VERSION ""

NS_ :

BS_:

BU_: ACM APIM APIM_CDC APIM_CIM APIM_CISM ARM DSP ESPM FCIMB GENERIC GWM HUD_ADV IPC MRCMB_RDAPM_HS3 RACM_RCIM TRM_ITRM TSTR WCM WCMB WCMC

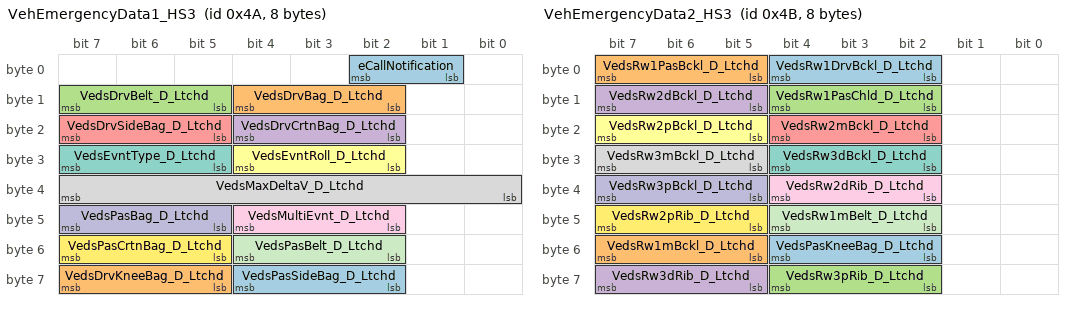
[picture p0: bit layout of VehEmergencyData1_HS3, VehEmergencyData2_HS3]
BO_ 74 VehEmergencyData1_HS3: 8 GWM
 SG_ eCallNotification : 2|2@0+ (1,0) [0|3] "SED"  APIM,APIM_CDC,APIM_CIM,APIM_CISM
 SG_ VedsDrvBag_D_Ltchd : 12|3@0+ (1,0) [0|7] "SED"  ACM,APIM,APIM_CDC,APIM_CIM,APIM_CISM
 SG_ VedsDrvBelt_D_Ltchd : 15|3@0+ (1,0) [0|7] "SED"  APIM,APIM_CDC,APIM_CIM,APIM_CISM
 SG_ VedsDrvCrtnBag_D_Ltchd : 20|3@0+ (1,0) [0|7] "SED"  APIM,APIM_CDC,APIM_CIM,APIM_CISM
 SG_ VedsDrvSideBag_D_Ltchd : 23|3@0+ (1,0) [0|7] "SED"  APIM,APIM_CDC,APIM_CIM,APIM_CISM
 SG_ VedsEvntRoll_D_Ltchd : 28|3@0+ (1,0) [0|7] "SED"  APIM,APIM_CDC,APIM_CIM,APIM_CISM
 SG_ VedsEvntType_D_Ltchd : 31|3@0+ (1,0) [0|7] "SED"  APIM,APIM_CDC,APIM_CIM,APIM_CISM
 SG_ VedsMaxDeltaV_D_Ltchd : 39|8@0+ (1,0) [0|255] "kph"  APIM,APIM_CDC,APIM_CIM,APIM_CISM
 SG_ VedsMultiEvnt_D_Ltchd : 44|3@0+ (1,0) [0|7] "SED"  APIM,APIM_CDC,APIM_CIM,APIM_CISM
 SG_ VedsPasBag_D_Ltchd : 47|3@0+ (1,0) [0|7] "SED"  APIM,APIM_CDC,APIM_CIM,APIM_CISM
 SG_ VedsPasBelt_D_Ltchd : 52|3@0+ (1,0) [0|7] "SED"  APIM,APIM_CDC,APIM_CIM,APIM_CISM
 SG_ VedsPasCrtnBag_D_Ltchd : 55|3@0+ (1,0) [0|7] "SED"  APIM,APIM_CDC,APIM_CIM,APIM_CISM
 SG_ VedsPasSideBag_D_Ltchd : 60|3@0+ (1,0) [0|7] "SED"  APIM,APIM_CDC,APIM_CIM,APIM_CISM
 SG_ VedsDrvKneeBag_D_Ltchd : 63|3@0+ (1,0) [0|7] "SED"  APIM,APIM_CDC,APIM_CIM,APIM_CISM

BO_ 75 VehEmergencyData2_HS3: 8 GWM
 SG_ VedsRw1DrvBckl_D_Ltchd : 4|3@0+ (1,0) [0|7] "SED"  APIM,APIM_CDC,APIM_CIM,APIM_CISM
 SG_ VedsRw1PasBckl_D_Ltchd : 7|3@0+ (1,0) [0|7] "SED"  APIM,APIM_CDC,APIM_CIM,APIM_CISM
 SG_ VedsRw1PasChld_D_Ltchd : 12|3@0+ (1,0) [0|7] "SED"  APIM,APIM_CDC,APIM_CIM,APIM_CISM
 SG_ VedsRw2dBckl_D_Ltchd : 15|3@0+ (1,0) [0|7] "SED"  APIM,APIM_CDC,APIM_CIM,APIM_CISM
 SG_ VedsRw2mBckl_D_Ltchd : 20|3@0+ (1,0) [0|7] "SED"  APIM,APIM_CDC,APIM_CIM,APIM_CISM
 SG_ VedsRw2pBckl_D_Ltchd : 23|3@0+ (1,0) [0|7] "SED"  APIM,APIM_CDC,APIM_CIM,APIM_CISM
 SG_ VedsRw3dBckl_D_Ltchd : 28|3@0+ (1,0) [0|7] "SED"  APIM,APIM_CDC,APIM_CIM,APIM_CISM
 SG_ VedsRw3mBckl_D_Ltchd : 31|3@0+ (1,0) [0|7] "SED"  APIM,APIM_CDC,APIM_CIM,APIM_CISM
 SG_ VedsRw2dRib_D_Ltchd : 36|3@0+ (1,0) [0|7] "SED"  APIM,APIM_CDC,APIM_CIM,APIM_CISM
 SG_ VedsRw3pBckl_D_Ltchd : 39|3@0+ (1,0) [0|7] "SED"  APIM,APIM_CDC,APIM_CIM,APIM_CISM
 SG_ VedsRw1mBelt_D_Ltchd : 44|3@0+ (1,0) [0|7] "SED"  APIM,APIM_CDC,APIM_CIM,APIM_CISM
 SG_ VedsRw2pRib_D_Ltchd : 47|3@0+ (1,0) [0|7] "SED"  APIM,APIM_CDC,APIM_CIM,APIM_CISM
 SG_ VedsPasKneeBag_D_Ltchd : 52|3@0+ (1,0) [0|7] "SED"  ACM,APIM,APIM_CDC,APIM_CIM,APIM_CISM
 SG_ VedsRw1mBckl_D_Ltchd : 55|3@0+ (1,0) [0|7] "SED"  APIM,APIM_CDC,APIM_CIM,APIM_CISM
 SG_ VedsRw3pRib_D_Ltchd : 60|3@0+ (1,0) [0|7] "SED"  APIM,APIM_CDC,APIM_CIM,APIM_CISM
 SG_ VedsRw3dRib_D_Ltchd : 63|3@0+ (1,0) [0|7] "SED"  APIM,APIM_CDC,APIM_CIM,APIM_CISM

BO_ 76 RCMStatusMessage2_HS3: 8 GWM
 SG_ RstrnImpactEvntStatus : 3|3@0+ (1,0) [0|7] "SED"  APIM,APIM_CDC,APIM_CIM,APIM_CISM,HUD_ADV
 SG_ PsngrFrntDetct_D_Actl : 5|2@0+ (1,0) [0|3] "SED"  APIM,APIM_CDC,APIM_CIM,APIM_CISM,IPC
 SG_ RILReq : 7|2@0+ (1,0) [0|3] "SED"  APIM_CDC,APIM_CIM,APIM_CISM,IPC
 SG_ SecondRowBuckleMid : 9|2@0+ (1,0) [0|3] "SED"  APIM,APIM_CDC,APIM_CIM,APIM_CISM,IPC
 SG_ SecondRowBuckleDriver : 11|2@0+ (1,0) [0|3] "SED"  APIM,APIM_CDC,APIM_CIM,APIM_CISM,IPC
 SG_ FirstRowBucklePsngr : 13|2@0+ (1,0) [0|3] "SED"  APIM,APIM_CDC,APIM_CIM,APIM_CISM,IPC
 SG_ FirstRowBuckleDriver : 15|2@0+ (1,0) [0|3] "SED"  APIM,APIM_CDC,APIM_CIM,APIM_CISM,IPC
 SG_ ThirdRowBucklePsngr : 17|2@0+ (1,0) [0|3] "SED"  APIM,APIM_CDC,APIM_CIM,APIM_CISM,IPC
 SG_ ThirdRowBuckleMid : 19|2@0+ (1,0) [0|3] "SED"  APIM,APIM_CDC,APIM_CIM,APIM_CISM,IPC
 SG_ ThirdRowBuckleDriver : 21|2@0+ (1,0) [0|3] "SED"  APIM,APIM_CDC,APIM_CIM,APIM_CISM,IPC
 SG_ SecondRowBucklePsngr : 23|2@0+ (1,0) [0|3] "SED"  APIM,APIM_CDC,APIM_CIM,APIM_CISM,IPC
 SG_ PsngrFmidDetct_D_Actl : 26|2@0+ (1,0) [0|3] "SED"  APIM,APIM_CDC,APIM_CIM,APIM_CISM,IPC
 SG_ FirstRowBuckleMid : 28|2@0+ (1,0) [0|3] "SED"  APIM,APIM_CDC,APIM_CIM,APIM_CISM,IPC
 SG_ EDRTriggerEvntSync : 29|1@0+ (1,0) [0|1] "SED"  APIM,APIM_CDC,APIM_CIM,APIM_CISM,IPC
 SG_ PassRstrnInd_Req : 31|2@0+ (1,0) [0|3] "SED"  APIM_CDC,APIM_CIM,APIM_CISM,FCIMB,GENERIC
 SG_ RCMStatusMsg2_No_Cnt : 35|4@0+ (1,0) [0|15] "unitless"  APIM_CDC,GENERIC
 SG_ RstrnPsngrOn_D_Stat : 39|4@0+ (1,0) [0|15] "SED"  APIM_CDC,APIM_CIM,APIM_CISM,IPC
 SG_ FirstRowBuckle_No_Cs : 47|8@0+ (1,0) [0|255] "unitless"  APIM_CDC,GENERIC
 SG_ RCMStatusMsg2_No_Cs : 55|8@0+ (1,0) [0|255] "unitless"  APIM_CDC
 SG_ PassRstrnIndB_Req : 61|2@0+ (1,0) [0|3] "SED"  APIM,APIM_CDC
 SG_ AirbagDrv_D_Actv : 63|2@0+ (1,0) [0|3] "SED"  APIM_CDC

BO_ 90 Gear_Shift_by_Wire_HS3: 8 GWM
 SG_ TrnGearButtn_B_ActlN0 : 0|1@0+ (1,0) [0|1] "SED" Vector__XXX
 SG_ TrnGearButtn_B_ActlM2 : 1|1@0+ (1,0) [0|1] "SED" Vector__XXX
 SG_ TrnGearButtn_B_ActlM1 : 2|1@0+ (1,0) [0|1] "SED" Vector__XXX
 SG_ TrnGearButtn_B_ActlM0 : 3|1@0+ (1,0) [0|1] "SED" Vector__XXX
 SG_ TrnGearButtn_B_ActlD2 : 4|1@0+ (1,0) [0|1] "SED" Vector__XXX
 SG_ TrnGearButtn_B_ActlD1 : 5|1@0+ (1,0) [0|1] "SED" Vector__XXX
 SG_ TrnGearButtn_B_ActlD0 : 6|1@0+ (1,0) [0|1] "SED" Vector__XXX
 SG_ BrkSwtchPos_B_ActlGsm : 7|1@0+ (1,0) [0|1] "SED" Vector__XXX
 SG_ TrnGearButtn_B_ActlR2 : 8|1@0+ (1,0) [0|1] "SED" Vector__XXX
 SG_ TrnGearButtn_B_ActlR1 : 9|1@0+ (1,0) [0|1] "SED" Vector__XXX
 SG_ TrnGearButtn_B_ActlR0 : 10|1@0+ (1,0) [0|1] "SED" Vector__XXX
 SG_ TrnGearButtn_B_ActlP2 : 11|1@0+ (1,0) [0|1] "SED" Vector__XXX
 SG_ TrnGearButtn_B_ActlP1 : 12|1@0+ (1,0) [0|1] "SED" Vector__XXX
 SG_ TrnGearButtn_B_ActlP0 : 13|1@0+ (1,0) [0|1] "SED" Vector__XXX
 SG_ TrnGearButtn_B_ActlN2 : 14|1@0+ (1,0) [0|1] "SED" Vector__XXX
 SG_ TrnGearButtn_B_ActlN1 : 15|1@0+ (1,0) [0|1] "SED" Vector__XXX
 SG_ TrnGearButtn_U_Actl : 23|8@0+ (0.05,0) [0|12.75] "VOLT" Vector__XXX
 SG_ TrnValidGearRq_D_Stat : 25|2@0+ (1,0) [0|3] "SED" Vector__XXX
 SG_ TrnGearRqCnt_B_Actl : 26|1@0+ (1,0) [0|1] "unitless" Vector__XXX
 SG_ TrnGear_D_RqDrv : 31|5@0+ (1,0) [0|31] "SED" Vector__XXX
 SG_ TrnGear_No_Cs : 39|8@0+ (1,0) [0|255] "unitless" Vector__XXX
 SG_ DrQltyDrv_D_StatGsm : 42|3@0+ (1,0) [0|7] "SED"  IPC
 SG_ TrnBtsiOvrrd_B_Stat : 43|1@0+ (1,0) [0|1] "SED" Vector__XXX
 SG_ TrnGear_No_Cnt : 47|4@0+ (1,0) [0|15] "unitless" Vector__XXX
 SG_ TrnRng_D_RqGsm : 51|4@0+ (1,0) [0|15] "SED" Vector__XXX
 SG_ TrnGsmNtmState_D_Actl : 55|2@0+ (1,0) [0|3] "SED" Vector__XXX
 SG_ GsmGearMsgTxt_D_Rq : 63|2@0+ (1,0) [0|3] "SED"  APIM_CDC,APIM_CIM,IPC

BO_ 92 Gear_Shift_by_Wire_3_HS3: 8 GWM
 SG_ TrnSbwSysHlth_D_Actl : 1|2@0+ (1,0) [0|3] "SED" Vector__XXX
 SG_ TrnGear_D_RqPt : 4|3@0+ (1,0) [0|7] "SED" Vector__XXX
 SG_ TrnNtrlTowCmd_D_Actl : 6|2@0+ (1,0) [0|3] "SED"  APIM,APIM_CDC,APIM_CIM
 SG_ TrnCmdCnt_B_Actl : 7|1@0+ (1,0) [0|1] "unitless" Vector__XXX
 SG_ TrnGearCmd_Pc_ActlPt : 9|10@0+ (0.1,0) [0|102.3] "percent duty cycle" Vector__XXX
 SG_ TrnValidGear_D_Cnfm : 11|2@0+ (1,0) [0|3] "SED" Vector__XXX
 SG_ TrnGearCmd_No_Cnt : 15|4@0+ (1,0) [0|15] "unitless" Vector__XXX
 SG_ TrnGearCmd_No_Cs : 31|8@0+ (1,0) [0|255] "unitless" Vector__XXX
 SG_ TrnGearMsgTxt_D_Rq : 36|5@0+ (1,0) [0|31] "SED"  APIM,APIM_CDC,APIM_CIM,IPC
 SG_ PrkBrkActv_D_RqTrnGear : 38|2@0+ (1,0) [0|3] "SED" Vector__XXX
 SG_ TrnCmdState_B_Actl : 39|1@0+ (1,0) [0|1] "SED" Vector__XXX
 SG_ GearSelLck_D_Rq : 41|2@0+ (1,0) [0|3] "SED" Vector__XXX
 SG_ TrnLvrV_D_Rq : 43|2@0+ (1,0) [0|3] "SED" Vector__XXX
 SG_ TrnDtpCmd_D_Actl : 46|3@0+ (1,0) [0|7] "SED" Vector__XXX
 SG_ TrnGearNtmAllow_B_Stat : 47|1@0+ (1,0) [0|1] "SED"  APIM,APIM_CDC,APIM_CIM,APIM_CISM,IPC
 SG_ TrnGearMsgTxt2_D_Rq : 53|5@0+ (1,0) [0|31] "SED"  APIM_CDC,APIM_CIM,IPC
 SG_ RaceTrakMde_D_Stat : 55|2@0+ (1,0) [0|3] "SED" Vector__XXX
 SG_ PrkBrkAppl_D_Rq : 63|3@0+ (1,0) [0|7] "SED" Vector__XXX

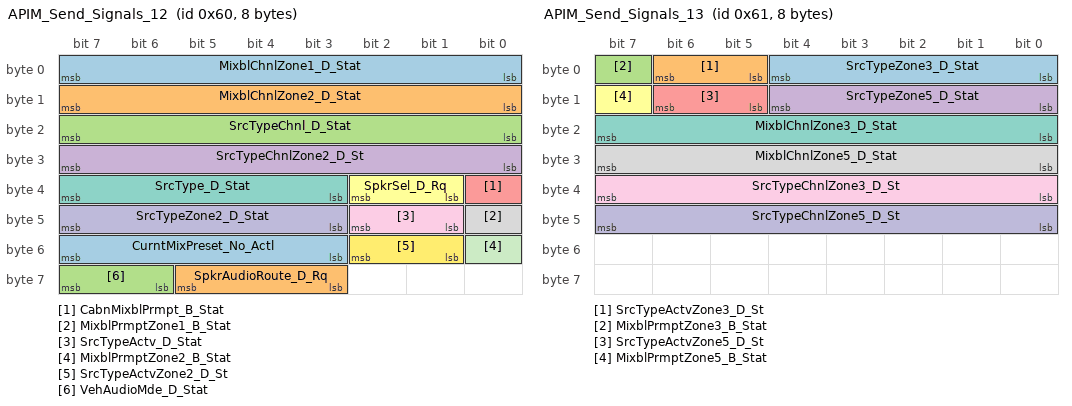
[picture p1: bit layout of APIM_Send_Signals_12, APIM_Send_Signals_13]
BO_ 96 APIM_Send_Signals_12: 8 APIM_CDC
 SG_ MixblChnlZone1_D_Stat : 7|8@0+ (1,0) [0|255] "SED"  ACM,DSP,HUD_ADV,RACM_RCIM,WCM,WCMB,WCMC
 SG_ MixblChnlZone2_D_Stat : 15|8@0+ (1,0) [0|255] "SED"  ACM,DSP
 SG_ SrcTypeChnl_D_Stat : 23|8@0+ (1,0) [0|255] "SED"  ACM,DSP,HUD_ADV,RACM_RCIM,WCM,WCMB,WCMC
 SG_ SrcTypeChnlZone2_D_St : 31|8@0+ (1,0) [0|255] "SED"  ACM,DSP
 SG_ CabnMixblPrmpt_B_Stat : 32|1@0+ (1,0) [0|1] "SED"  ACM,DSP,RACM_RCIM
 SG_ SpkrSel_D_Rq : 34|2@0+ (1,0) [0|3] "unitless"  ACM
 SG_ SrcType_D_Stat : 39|5@0+ (1,0) [0|31] "SED"  ACM,DSP,HUD_ADV,RACM_RCIM,WCM,WCMB,WCMC
 SG_ MixblPrmptZone1_B_Stat : 40|1@0+ (1,0) [0|1] "SED"  ACM,DSP,HUD_ADV,RACM_RCIM,WCM
 SG_ SrcTypeActv_D_Stat : 42|2@0+ (1,0) [0|3] "SED"  ACM,DSP,HUD_ADV,RACM_RCIM,WCM,WCMB,WCMC
 SG_ SrcTypeZone2_D_Stat : 47|5@0+ (1,0) [0|31] "SED"  ACM,DSP,WCM,WCMB,WCMC
 SG_ MixblPrmptZone2_B_Stat : 48|1@0+ (1,0) [0|1] "SED"  ACM,DSP
 SG_ SrcTypeActvZone2_D_St : 50|2@0+ (1,0) [0|3] "SED"  ACM,DSP,WCM,WCMB,WCMC
 SG_ CurntMixPreset_No_Actl : 55|5@0+ (1,0) [0|31] "unitless"  ACM,RACM_RCIM
 SG_ SpkrAudioRoute_D_Rq : 61|3@0+ (1,0) [0|7] "SED"  ACM
 SG_ VehAudioMde_D_Stat : 63|2@0+ (1,0) [0|3] "SED"  ACM,DSP,RACM_RCIM

BO_ 97 APIM_Send_Signals_13: 8 APIM_CDC
 SG_ SrcTypeZone3_D_Stat : 4|5@0+ (1,0) [0|31] "SED"  ACM,DSP,WCM,WCMB,WCMC
 SG_ SrcTypeActvZone3_D_St : 6|2@0+ (1,0) [0|3] "SED"  ACM,DSP,WCM,WCMB,WCMC
 SG_ MixblPrmptZone3_B_Stat : 7|1@0+ (1,0) [0|1] "SED"  ACM,DSP
 SG_ SrcTypeZone5_D_Stat : 12|5@0+ (1,0) [0|31] "SED"  ACM,DSP,WCM,WCMB,WCMC
 SG_ SrcTypeActvZone5_D_St : 14|2@0+ (1,0) [0|3] "SED"  ACM,DSP,WCM,WCMB,WCMC
 SG_ MixblPrmptZone5_B_Stat : 15|1@0+ (1,0) [0|1] "SED"  ACM,DSP
 SG_ MixblChnlZone3_D_Stat : 23|8@0+ (1,0) [0|255] "SED"  ACM,DSP
 SG_ MixblChnlZone5_D_Stat : 31|8@0+ (1,0) [0|255] "SED"  ACM,DSP
 SG_ SrcTypeChnlZone3_D_St : 39|8@0+ (1,0) [0|255] "SED"  ACM,DSP
 SG_ SrcTypeChnlZone5_D_St : 47|8@0+ (1,0) [0|255] "SED"  ACM,DSP

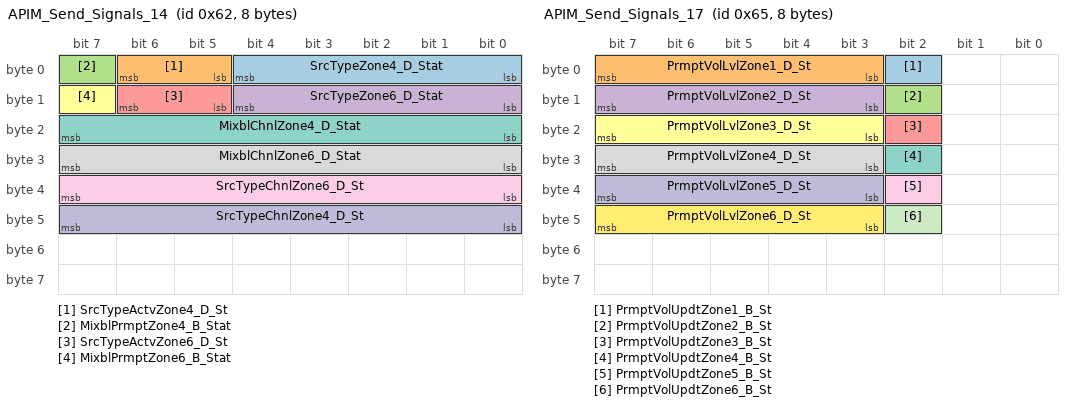
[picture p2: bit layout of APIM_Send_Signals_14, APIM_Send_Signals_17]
BO_ 98 APIM_Send_Signals_14: 8 APIM_CDC
 SG_ SrcTypeZone4_D_Stat : 4|5@0+ (1,0) [0|31] "SED"  ACM,DSP,WCM,WCMB,WCMC
 SG_ SrcTypeActvZone4_D_St : 6|2@0+ (1,0) [0|3] "SED"  ACM,DSP,WCM,WCMB,WCMC
 SG_ MixblPrmptZone4_B_Stat : 7|1@0+ (1,0) [0|1] "SED"  ACM,DSP
 SG_ SrcTypeZone6_D_Stat : 12|5@0+ (1,0) [0|31] "SED"  ACM,DSP,WCM,WCMB,WCMC
 SG_ SrcTypeActvZone6_D_St : 14|2@0+ (1,0) [0|3] "SED"  ACM,DSP,WCM,WCMB,WCMC
 SG_ MixblPrmptZone6_B_Stat : 15|1@0+ (1,0) [0|1] "SED"  ACM,DSP
 SG_ MixblChnlZone4_D_Stat : 23|8@0+ (1,0) [0|255] "SED"  ACM,DSP
 SG_ MixblChnlZone6_D_Stat : 31|8@0+ (1,0) [0|255] "SED"  ACM,DSP
 SG_ SrcTypeChnlZone6_D_St : 39|8@0+ (1,0) [0|255] "SED"  ACM,DSP
 SG_ SrcTypeChnlZone4_D_St : 47|8@0+ (1,0) [0|255] "SED"  ACM,DSP

BO_ 99 APIM_Send_Signals_15: 8 APIM_CDC
 SG_ OffstVolUpdtZone2_B_St : 0|1@0+ (1,0) [0|1] "SED"  ACM,DSP
 SG_ OffstVolZone2_No_Actl : 3|3@0+ (1,-3) [-3|4] "unitless"  ACM,DSP
 SG_ OffstVolUpdtZone1_B_St : 4|1@0+ (1,0) [0|1] "SED"  ACM,DSP
 SG_ OffstVolZone1_No_Actl : 7|3@0+ (1,-3) [-3|4] "unitless"  ACM,DSP
 SG_ OffstVolUpdtZone4_B_St : 8|1@0+ (1,0) [0|1] "SED"  ACM,DSP
 SG_ OffstVolZone4_No_Actl : 11|3@0+ (1,-3) [-3|4] "unitless"  ACM,DSP
 SG_ OffstVolUpdtZone3_B_St : 12|1@0+ (1,0) [0|1] "SED"  ACM,DSP
 SG_ OffstVolZone3_No_Actl : 15|3@0+ (1,-3) [-3|4] "unitless"  ACM,DSP
 SG_ OffstVolUpdtZone6_B_St : 16|1@0+ (1,0) [0|1] "SED"  ACM,DSP
 SG_ OffstVolZone6_No_Actl : 19|3@0+ (1,-3) [-3|4] "unitless"  ACM,DSP
 SG_ OffstVolUpdtZone5_B_St : 20|1@0+ (1,0) [0|1] "SED"  ACM,DSP
 SG_ OffstVolZone5_No_Actl : 23|3@0+ (1,-3) [-3|4] "unitless"  ACM,DSP
 SG_ MedVolUpdt_B_Stat : 26|1@0+ (1,0) [0|1] "SED"  ACM,DSP,RACM_RCIM
 SG_ CabnMedVolLvl_D_Stat : 31|5@0+ (1,0) [0|31] "SED"  ACM,DSP,RACM_RCIM
 SG_ PhonVolUpdt_B_Stat : 34|1@0+ (1,0) [0|1] "SED"  ACM,DSP
 SG_ CabnPhonVolLvl_D_Stat : 39|5@0+ (1,0) [0|31] "SED"  ACM,DSP
 SG_ PrmptVolUpdt_B_Stat : 42|1@0+ (1,0) [0|1] "SED"  ACM,DSP
 SG_ CabnPrmptVolLvl_D_Stat : 47|5@0+ (1,0) [0|31] "SED"  ACM,DSP
 SG_ RaVolUpdt_B_Stat : 50|1@0+ (1,0) [0|1] "SED"  ACM,DSP
 SG_ CabnRaVolLvl_D_Stat : 55|5@0+ (1,0) [0|31] "SED"  ACM,DSP
 SG_ CallRngVolUpdt_B_Stat : 58|1@0+ (1,0) [0|1] "SED"  ACM,DSP
 SG_ CabnCallRngVolLvl_D_St : 63|5@0+ (1,0) [0|31] "SED"  ACM,DSP

BO_ 100 APIM_Send_Signals_16: 8 APIM_CDC
 SG_ OvrhdLamp_B_Rq : 0|1@0+ (1,0) [0|1] "SED"  GWM
 SG_ DrDefeatMde_B_Rq : 1|1@0+ (1,0) [0|1] "SED"  GWM
 SG_ MedVolUpdtZone1_B_Stat : 2|1@0+ (1,0) [0|1] "unitless"  ACM,DSP,RACM_RCIM
 SG_ MedVolLvlZone1_D_Stat : 7|5@0+ (1,0) [0|31] "unitless"  ACM,DSP,RACM_RCIM
 SG_ OvrhdLampFmid_B_Rq : 8|1@0+ (1,0) [0|1] "SED"  GWM
 SG_ OvrhdLampFl_B_Rq : 9|1@0+ (1,0) [0|1] "SED"  GWM
 SG_ MedVolUpdtZone2_B_Stat : 10|1@0+ (1,0) [0|1] "unitless"  ACM,DSP,RACM_RCIM
 SG_ MedVolLvlZone2_D_Stat : 15|5@0+ (1,0) [0|31] "unitless"  ACM,DSP,RACM_RCIM
 SG_ OvrhdLampR2Left_B_Rq : 16|1@0+ (1,0) [0|1] "SED"  GWM
 SG_ OvrhdLampFr_B_Rq : 17|1@0+ (1,0) [0|1] "SED"  GWM
 SG_ MedVolUpdtZone3_B_Stat : 18|1@0+ (1,0) [0|1] "unitless"  ACM,DSP,RACM_RCIM
 SG_ MedVolLvlZone3_D_Stat : 23|5@0+ (1,0) [0|31] "unitless"  ACM,DSP,RACM_RCIM
 SG_ OvrhdLampR2Right_B_Rq : 24|1@0+ (1,0) [0|1] "SED"  GWM
 SG_ OvrhdLampR2Mid_B_Rq : 25|1@0+ (1,0) [0|1] "SED"  GWM
 SG_ MedVolUpdtZone4_B_Stat : 26|1@0+ (1,0) [0|1] "unitless"  ACM,DSP,RACM_RCIM
 SG_ MedVolLvlZone4_D_Stat : 31|5@0+ (1,0) [0|31] "unitless"  ACM,DSP,RACM_RCIM
 SG_ OvrhdLampR3Mid_B_Rq : 32|1@0+ (1,0) [0|1] "SED"  GWM
 SG_ OvrhdLampR3Left_B_Rq : 33|1@0+ (1,0) [0|1] "SED"  GWM
 SG_ MedVolUpdtZone5_B_Stat : 34|1@0+ (1,0) [0|1] "unitless"  ACM,DSP,RACM_RCIM
 SG_ MedVolLvlZone5_D_Stat : 39|5@0+ (1,0) [0|31] "unitless"  ACM,DSP,RACM_RCIM
 SG_ OvrhdLampR3Right_B_Rq : 41|1@0+ (1,0) [0|1] "SED"  GWM
 SG_ MedVolUpdtZone6_B_Stat : 42|1@0+ (1,0) [0|1] "unitless"  ACM,DSP,RACM_RCIM
 SG_ MedVolLvlZone6_D_Stat : 47|5@0+ (1,0) [0|31] "unitless"  ACM,DSP,RACM_RCIM
 SG_ PersStorePsngr_D_Rq : 51|3@0+ (1,0) [0|7] "SED"  GWM
 SG_ PersRecallPsngr_D_Rq : 61|3@0+ (1,0) [0|7] "SED"  GWM
 SG_ StwblStewMde_D_RqMnu : 63|2@0+ (1,0) [0|3] "SED"  GWM

BO_ 101 APIM_Send_Signals_17: 8 APIM_CDC
 SG_ PrmptVolUpdtZone1_B_St : 2|1@0+ (1,0) [0|1] "SED"  ACM,DSP
 SG_ PrmptVolLvlZone1_D_St : 7|5@0+ (1,0) [0|31] "SED"  ACM,DSP
 SG_ PrmptVolUpdtZone2_B_St : 10|1@0+ (1,0) [0|1] "SED"  ACM,DSP
 SG_ PrmptVolLvlZone2_D_St : 15|5@0+ (1,0) [0|31] "SED"  ACM,DSP
 SG_ PrmptVolUpdtZone3_B_St : 18|1@0+ (1,0) [0|1] "SED"  ACM,DSP
 SG_ PrmptVolLvlZone3_D_St : 23|5@0+ (1,0) [0|31] "SED"  ACM,DSP
 SG_ PrmptVolUpdtZone4_B_St : 26|1@0+ (1,0) [0|1] "SED"  ACM,DSP
 SG_ PrmptVolLvlZone4_D_St : 31|5@0+ (1,0) [0|31] "SED"  ACM,DSP
 SG_ PrmptVolUpdtZone5_B_St : 34|1@0+ (1,0) [0|1] "SED"  ACM,DSP
 SG_ PrmptVolLvlZone5_D_St : 39|5@0+ (1,0) [0|31] "SED"  ACM,DSP
 SG_ PrmptVolUpdtZone6_B_St : 42|1@0+ (1,0) [0|1] "SED"  ACM,DSP
 SG_ PrmptVolLvlZone6_D_St : 47|5@0+ (1,0) [0|31] "SED"  ACM,DSP

BO_ 102 APIM_Send_Signals_18: 8 APIM_CDC
 SG_ CaptAnouncmnt_D_Rq : 1|2@0+ (1,0) [0|3] "unitless"  ACM,GWM
 SG_ PhonRaVolUpdtZon1_B_St : 2|1@0+ (1,0) [0|1] "SED"  ACM,DSP,GWM
 SG_ PhonRaVolLvlZone1_D_St : 7|5@0+ (1,0) [0|31] "SED"  ACM,DSP,GWM
 SG_ PhonCallZone2_D_Stat : 9|2@0+ (1,0) [0|3] "unitless"  ACM,GWM
 SG_ PhonRaVolUpdtZon2_B_St : 10|1@0+ (1,0) [0|1] "SED"  ACM,DSP,GWM
 SG_ PhonRaVolLvlZone2_D_St : 15|5@0+ (1,0) [0|31] "SED"  ACM,DSP,GWM
 SG_ PhonCallZone3_D_Stat : 17|2@0+ (1,0) [0|3] "unitless"  ACM,GWM
 SG_ PhonRaVolUpdtZon3_B_St : 18|1@0+ (1,0) [0|1] "SED"  ACM,DSP,GWM
 SG_ PhonRaVolLvlZone3_D_St : 23|5@0+ (1,0) [0|31] "SED"  ACM,DSP,GWM
 SG_ PhonCallZone4_D_Stat : 25|2@0+ (1,0) [0|3] "unitless"  ACM,GWM
 SG_ PhonRaVolUpdtZon4_B_St : 26|1@0+ (1,0) [0|1] "SED"  ACM,DSP,GWM
 SG_ PhonRaVolLvlZone4_D_St : 31|5@0+ (1,0) [0|31] "SED"  ACM,DSP,GWM
 SG_ PhonCallZone5_D_Stat : 33|2@0+ (1,0) [0|3] "unitless"  ACM,GWM
 SG_ PhonRaVolUpdtZon5_B_St : 34|1@0+ (1,0) [0|1] "SED"  ACM,DSP,GWM
 SG_ PhonRaVolLvlZone5_D_St : 39|5@0+ (1,0) [0|31] "SED"  ACM,DSP,GWM
 SG_ PhonCallZone6_D_Stat : 41|2@0+ (1,0) [0|3] "unitless"  ACM,GWM
 SG_ PhonRaVolUpdtZon6_B_St : 42|1@0+ (1,0) [0|1] "SED"  ACM,DSP,GWM
 SG_ PhonRaVolLvlZone6_D_St : 47|5@0+ (1,0) [0|31] "SED"  ACM,DSP,GWM
 SG_ ThemSel_D_Stat : 52|4@0+ (1,0) [0|15] "SED"  GWM,HUD_ADV,RACM_RCIM
 SG_ InCarComm_B_Rq : 55|1@0+ (1,0) [0|1] "unitless"  ACM,GWM
 SG_ TvfSndShrt_D_Stat : 63|2@0+ (1,0) [0|3] "SED"  GWM

BO_ 103 ACU_Send_Signals_15: 8 ACM
 SG_ AuxAmpfy_D_Stat : 1|2@0+ (1,0) [0|3] "SED"  APIM_CDC
 SG_ RaSrcType_D_Stat : 3|2@0+ (1,0) [0|3] "SED"  APIM_CDC,APIM_CIM
 SG_ VehAudioMdeCtl_D_Stat : 5|2@0+ (1,0) [0|3] "SED"  APIM_CDC,APIM_CIM
 SG_ ActvNseMute_D_Stat2 : 7|2@0+ (1,0) [0|3] "SED"  APIM_CDC,APIM_CIM
 SG_ AudioCtlChnl1_D_Stat : 10|2@0+ (1,0) [0|3] "SED"  APIM_CDC
 SG_ RaActvType_D_Stat : 15|5@0+ (1,0) [0|31] "SED"  APIM_CDC,APIM_CIM
 SG_ AudioCtlChnl2_D_Stat : 18|2@0+ (1,0) [0|3] "SED"  APIM_CDC
 SG_ PresetTunCnfm_No_Actl : 23|5@0+ (1,0) [0|31] "unitless"  APIM_CDC,APIM_CIM
 SG_ AudioCtlChnl3_D_Stat : 26|2@0+ (1,0) [0|3] "SED"  APIM_CDC
 SG_ CabnMedVolCtl_D_Stat : 31|5@0+ (1,0) [0|31] "SED"  APIM_CDC,APIM_CIM
 SG_ AudioCtlChnl4_D_Stat : 34|2@0+ (1,0) [0|3] "SED"  APIM_CDC
 SG_ CabnRaVolCtl_D_Stat : 39|5@0+ (1,0) [0|31] "SED"  APIM_CDC,APIM_CIM
 SG_ AudioCtlChnl5_D_Stat : 42|2@0+ (1,0) [0|3] "SED"  APIM_CDC
 SG_ SpkrCnnctRear_D_Stat : 44|2@0+ (1,0) [0|3] "SED"  APIM_CDC,APIM_CIM
 SG_ SpkrCnnctFront_D_Stat : 46|2@0+ (1,0) [0|3] "SED"  APIM_CDC,APIM_CIM
 SG_ SpkrSel_B_Res : 47|1@0+ (1,0) [0|1] "SED"  APIM_CDC,APIM_CIM
 SG_ AuxAmpfyChnl4_D_Stat : 49|2@0+ (1,0) [0|3] "SED"  APIM_CDC
 SG_ AuxAmpfyChnl3_D_Stat : 51|2@0+ (1,0) [0|3] "SED"  APIM_CDC
 SG_ AuxAmpfyChnl2_D_Stat : 53|2@0+ (1,0) [0|3] "SED"  APIM_CDC
 SG_ AuxAmpfyChnl1_D_Stat : 55|2@0+ (1,0) [0|3] "SED"  APIM_CDC
 SG_ SetCrntStation_D_Res : 57|2@0+ (1,0) [0|3] "SED"  APIM_CDC
 SG_ AudioCtlChnl8_D_Stat : 59|2@0+ (1,0) [0|3] "SED"  APIM_CDC
 SG_ AudioCtlChnl7_D_Stat : 61|2@0+ (1,0) [0|3] "SED"  APIM_CDC
 SG_ AudioCtlChnl6_D_Stat : 63|2@0+ (1,0) [0|3] "SED"  APIM_CDC

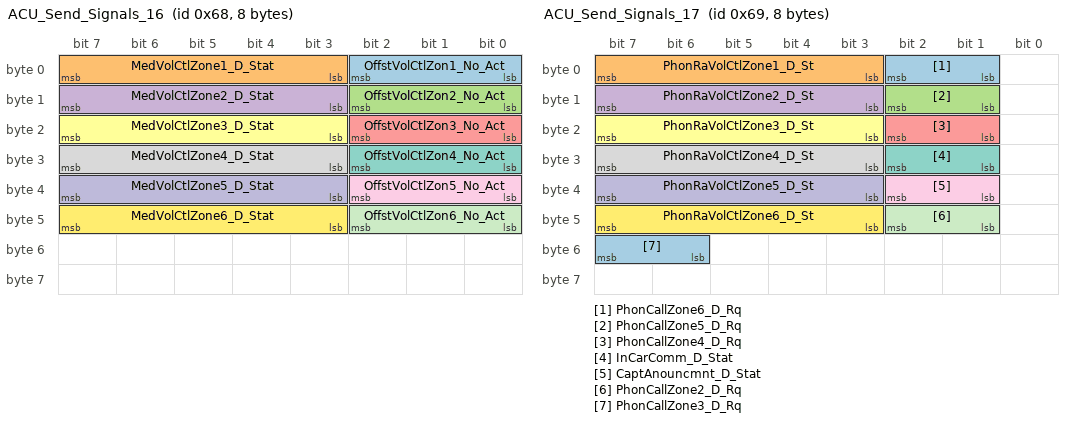
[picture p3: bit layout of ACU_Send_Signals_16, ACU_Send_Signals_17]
BO_ 104 ACU_Send_Signals_16: 8 ACM
 SG_ OffstVolCtlZon1_No_Act : 2|3@0+ (1,-3) [-3|4] "unitless"  APIM_CDC
 SG_ MedVolCtlZone1_D_Stat : 7|5@0+ (1,0) [0|31] "SED"  APIM_CDC,APIM_CIM
 SG_ OffstVolCtlZon2_No_Act : 10|3@0+ (1,-3) [-3|4] "unitless"  APIM_CDC,APIM_CIM
 SG_ MedVolCtlZone2_D_Stat : 15|5@0+ (1,0) [0|31] "SED"  APIM_CDC,APIM_CIM
 SG_ OffstVolCtlZon3_No_Act : 18|3@0+ (1,-3) [-3|4] "unitless"  APIM_CDC,APIM_CIM
 SG_ MedVolCtlZone3_D_Stat : 23|5@0+ (1,0) [0|31] "SED"  APIM_CDC,APIM_CIM
 SG_ OffstVolCtlZon4_No_Act : 26|3@0+ (1,-3) [-3|4] "unitless"  APIM_CDC,APIM_CIM
 SG_ MedVolCtlZone4_D_Stat : 31|5@0+ (1,0) [0|31] "SED"  APIM_CDC,APIM_CIM
 SG_ OffstVolCtlZon5_No_Act : 34|3@0+ (1,-3) [-3|4] "unitless"  APIM_CDC
 SG_ MedVolCtlZone5_D_Stat : 39|5@0+ (1,0) [0|31] "SED"  APIM_CDC,APIM_CIM
 SG_ OffstVolCtlZon6_No_Act : 42|3@0+ (1,-3) [-3|4] "unitless"  APIM_CDC,APIM_CIM
 SG_ MedVolCtlZone6_D_Stat : 47|5@0+ (1,0) [0|31] "SED"  APIM_CDC

BO_ 105 ACU_Send_Signals_17: 8 ACM
 SG_ PhonCallZone6_D_Rq : 2|2@0+ (1,0) [0|3] "SED"  APIM_CDC,APIM_CIM
 SG_ PhonRaVolCtlZone1_D_St : 7|5@0+ (1,0) [0|31] "SED"  APIM_CDC,APIM_CIM
 SG_ PhonCallZone5_D_Rq : 10|2@0+ (1,0) [0|3] "SED"  APIM_CDC,APIM_CIM
 SG_ PhonRaVolCtlZone2_D_St : 15|5@0+ (1,0) [0|31] "SED"  APIM_CDC,APIM_CIM
 SG_ PhonCallZone4_D_Rq : 18|2@0+ (1,0) [0|3] "SED"  APIM_CDC,APIM_CIM
 SG_ PhonRaVolCtlZone3_D_St : 23|5@0+ (1,0) [0|31] "SED"  APIM_CDC,APIM_CIM
 SG_ InCarComm_D_Stat : 26|2@0+ (1,0) [0|3] "SED"  APIM_CDC,APIM_CIM
 SG_ PhonRaVolCtlZone4_D_St : 31|5@0+ (1,0) [0|31] "SED"  APIM_CDC,APIM_CIM
 SG_ CaptAnouncmnt_D_Stat : 34|2@0+ (1,0) [0|3] "SED"  APIM_CDC,APIM_CIM
 SG_ PhonRaVolCtlZone5_D_St : 39|5@0+ (1,0) [0|31] "SED"  APIM_CDC,APIM_CIM
 SG_ PhonCallZone2_D_Rq : 42|2@0+ (1,0) [0|3] "SED"  APIM_CDC,APIM_CIM
 SG_ PhonRaVolCtlZone6_D_St : 47|5@0+ (1,0) [0|31] "SED"  APIM_CDC,APIM_CIM
 SG_ PhonCallZone3_D_Rq : 55|2@0+ (1,0) [0|3] "SED"  APIM_CDC,APIM_CIM

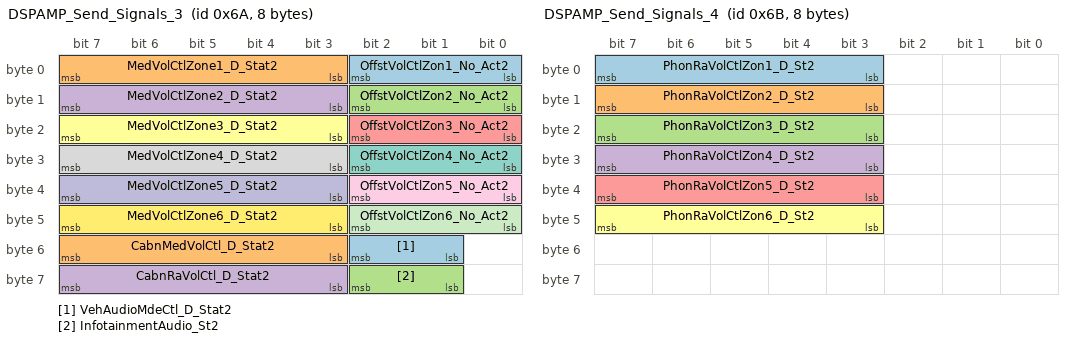
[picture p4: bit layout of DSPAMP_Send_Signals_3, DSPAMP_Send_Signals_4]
BO_ 106 DSPAMP_Send_Signals_3: 8 DSP
 SG_ OffstVolCtlZon1_No_Act2 : 2|3@0+ (1,-3) [-3|4] "unitless"  APIM_CDC,APIM_CIM
 SG_ MedVolCtlZone1_D_Stat2 : 7|5@0+ (1,0) [0|31] "unitless"  APIM_CDC,APIM_CIM
 SG_ OffstVolCtlZon2_No_Act2 : 10|3@0+ (1,-3) [-3|4] "unitless"  APIM_CDC,APIM_CIM
 SG_ MedVolCtlZone2_D_Stat2 : 15|5@0+ (1,0) [0|31] "unitless"  APIM_CDC,APIM_CIM
 SG_ OffstVolCtlZon3_No_Act2 : 18|3@0+ (1,-3) [-3|4] "unitless"  APIM_CDC,APIM_CIM
 SG_ MedVolCtlZone3_D_Stat2 : 23|5@0+ (1,0) [0|31] "unitless"  APIM_CDC,APIM_CIM
 SG_ OffstVolCtlZon4_No_Act2 : 26|3@0+ (1,-3) [-3|4] "unitless"  APIM_CDC,APIM_CIM
 SG_ MedVolCtlZone4_D_Stat2 : 31|5@0+ (1,0) [0|31] "unitless"  APIM_CDC,APIM_CIM
 SG_ OffstVolCtlZon5_No_Act2 : 34|3@0+ (1,-3) [-3|4] "unitless"  APIM_CDC,APIM_CIM
 SG_ MedVolCtlZone5_D_Stat2 : 39|5@0+ (1,0) [0|31] "unitless"  APIM_CDC,APIM_CIM
 SG_ OffstVolCtlZon6_No_Act2 : 42|3@0+ (1,-3) [-3|4] "unitless"  APIM_CDC,APIM_CIM
 SG_ MedVolCtlZone6_D_Stat2 : 47|5@0+ (1,0) [0|31] "unitless"  APIM_CDC,APIM_CIM
 SG_ VehAudioMdeCtl_D_Stat2 : 50|2@0+ (1,0) [0|3] "unitless"  APIM_CDC,APIM_CIM
 SG_ CabnMedVolCtl_D_Stat2 : 55|5@0+ (1,0) [0|31] "unitless"  APIM_CDC,APIM_CIM
 SG_ InfotainmentAudio_St2 : 58|2@0+ (1,0) [0|3] "unitless"  APIM_CDC,APIM_CIM
 SG_ CabnRaVolCtl_D_Stat2 : 63|5@0+ (1,0) [0|31] "unitless"  APIM_CDC,APIM_CIM

BO_ 107 DSPAMP_Send_Signals_4: 8 DSP
 SG_ PhonRaVolCtlZon1_D_St2 : 7|5@0+ (1,0) [0|31] "unitless"  APIM_CDC,APIM_CIM
 SG_ PhonRaVolCtlZon2_D_St2 : 15|5@0+ (1,0) [0|31] "unitless"  APIM_CDC,APIM_CIM
 SG_ PhonRaVolCtlZon3_D_St2 : 23|5@0+ (1,0) [0|31] "unitless"  APIM_CDC,APIM_CIM
 SG_ PhonRaVolCtlZon4_D_St2 : 31|5@0+ (1,0) [0|31] "unitless"  APIM_CDC,APIM_CIM
 SG_ PhonRaVolCtlZon5_D_St2 : 39|5@0+ (1,0) [0|31] "unitless"  APIM_CDC,APIM_CIM
 SG_ PhonRaVolCtlZon6_D_St2 : 47|5@0+ (1,0) [0|31] "unitless"  APIM_CDC,APIM_CIM

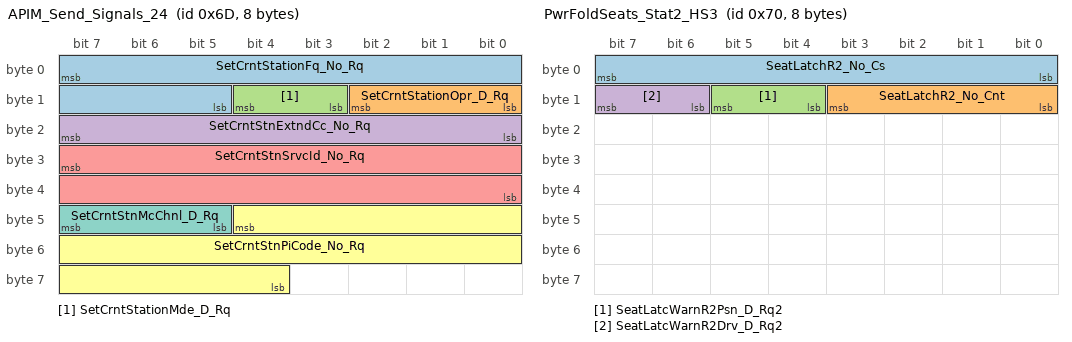
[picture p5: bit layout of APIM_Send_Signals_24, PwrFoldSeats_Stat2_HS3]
BO_ 109 APIM_Send_Signals_24: 8 APIM_CDC
 SG_ SetCrntStationFq_No_Rq : 7|11@0+ (1,0) [0|1557] "unitless"  ACM
 SG_ SetCrntStationOpr_D_Rq : 10|3@0+ (1,0) [0|7] "SED"  ACM
 SG_ SetCrntStationMde_D_Rq : 12|2@0+ (1,0) [0|3] "SED"  ACM
 SG_ SetCrntStnExtndCc_No_Rq : 23|8@0+ (1,0) [0|255] "unitless"  ACM
 SG_ SetCrntStnSrvcId_No_Rq : 31|16@0+ (1,0) [0|65535] "unitless"  ACM
 SG_ SetCrntStnPiCode_No_Rq : 44|17@0+ (1,0) [0|65535] "unitless"  ACM
 SG_ SetCrntStnMcChnl_D_Rq : 47|3@0+ (1,0) [0|7] "SED"  ACM

BO_ 110 DSPAMP_Send_Signals_5: 8 DSP
 SG_ AudioAmpfyChnl4_D_Stat : 1|2@0+ (1,0) [0|3] "SED"  APIM_CDC
 SG_ AudioAmpfyChnl3_D_Stat : 3|2@0+ (1,0) [0|3] "SED"  APIM_CDC
 SG_ AudioAmpfyChnl2_D_Stat : 5|2@0+ (1,0) [0|3] "SED"  APIM_CDC
 SG_ AudioAmpfyChnl1_D_Stat : 7|2@0+ (1,0) [0|3] "SED"  APIM_CDC
 SG_ AudioAmpfyChnl8_D_Stat : 9|2@0+ (1,0) [0|3] "SED"  APIM_CDC
 SG_ AudioAmpfyChnl7_D_Stat : 11|2@0+ (1,0) [0|3] "SED"  APIM_CDC
 SG_ AudioAmpfyChnl6_D_Stat : 13|2@0+ (1,0) [0|3] "SED"  APIM_CDC
 SG_ AudioAmpfyChnl5_D_Stat : 15|2@0+ (1,0) [0|3] "SED"  APIM_CDC
 SG_ AudioAmpfyChnl12_D_St : 17|2@0+ (1,0) [0|3] "SED"  APIM_CDC
 SG_ AudioAmpfyChnl11_D_St : 19|2@0+ (1,0) [0|3] "SED"  APIM_CDC
 SG_ AudioAmpfyChnl10_D_St : 21|2@0+ (1,0) [0|3] "SED"  APIM_CDC
 SG_ AudioAmpfyChnl9_D_Stat : 23|2@0+ (1,0) [0|3] "SED"  APIM_CDC
 SG_ AudioAmpfyChnl16_D_St : 25|2@0+ (1,0) [0|3] "SED"  APIM_CDC
 SG_ AudioAmpfyChnl15_D_St : 27|2@0+ (1,0) [0|3] "SED"  APIM_CDC
 SG_ AudioAmpfyChnl14_D_St : 29|2@0+ (1,0) [0|3] "SED"  APIM_CDC
 SG_ AudioAmpfyChnl13_D_St : 31|2@0+ (1,0) [0|3] "SED"  APIM_CDC
 SG_ AudioAmpfyChnl20_D_St : 33|2@0+ (1,0) [0|3] "SED"  APIM_CDC
 SG_ AudioAmpfyChnl19_D_St : 35|2@0+ (1,0) [0|3] "SED"  APIM_CDC
 SG_ AudioAmpfyChnl18_D_St : 37|2@0+ (1,0) [0|3] "SED"  APIM_CDC
 SG_ AudioAmpfyChnl17_D_St : 39|2@0+ (1,0) [0|3] "SED"  APIM_CDC
 SG_ AudioAmpfyChnl24_D_St : 41|2@0+ (1,0) [0|3] "SED"  APIM_CDC
 SG_ AudioAmpfyChnl23_D_St : 43|2@0+ (1,0) [0|3] "SED"  APIM_CDC
 SG_ AudioAmpfyChnl22_D_St : 45|2@0+ (1,0) [0|3] "SED"  APIM_CDC
 SG_ AudioAmpfyChnl21_D_St : 47|2@0+ (1,0) [0|3] "SED"  APIM_CDC

BO_ 112 PwrFoldSeats_Stat2_HS3: 8 GWM
 SG_ SeatLatchR2_No_Cs : 7|8@0+ (1,0) [0|255] "unitless"  APIM_CDC,IPC
 SG_ SeatLatchR2_No_Cnt : 11|4@0+ (1,0) [0|15] "unitless"  APIM_CDC,IPC
 SG_ SeatLatcWarnR2Psn_D_Rq2 : 13|2@0+ (1,0) [0|3] "SED"  APIM_CDC,IPC
 SG_ SeatLatcWarnR2Drv_D_Rq2 : 15|2@0+ (1,0) [0|3] "SED"  APIM_CDC,IPC

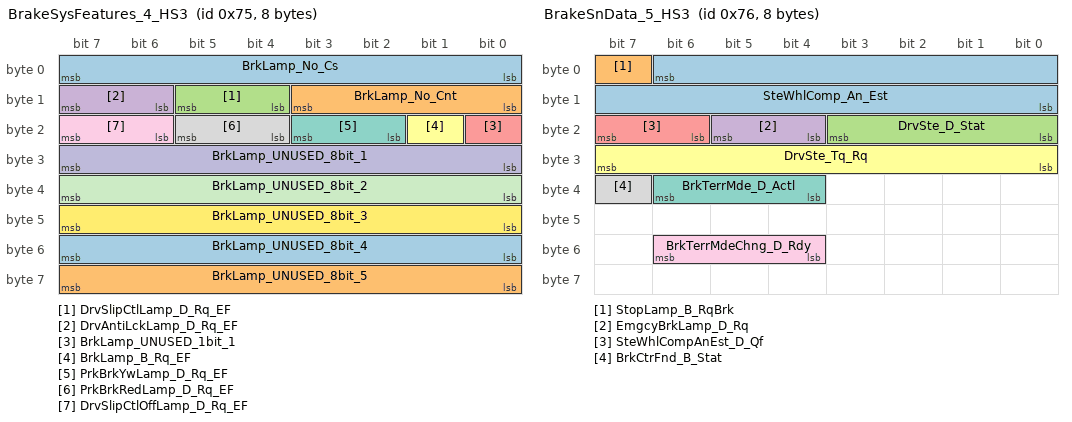
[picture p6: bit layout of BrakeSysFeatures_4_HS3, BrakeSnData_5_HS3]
BO_ 117 BrakeSysFeatures_4_HS3: 8 GWM
 SG_ BrkLamp_No_Cs : 7|8@0+ (1,0) [0|255] "unitless"  APIM_CDC,APIM_CIM,IPC
 SG_ BrkLamp_No_Cnt : 11|4@0+ (1,0) [0|15] "unitless"  APIM_CDC,APIM_CIM,IPC
 SG_ DrvSlipCtlLamp_D_Rq_EF : 13|2@0+ (1,0) [0|3] "SED"  APIM_CDC,APIM_CIM,IPC
 SG_ DrvAntiLckLamp_D_Rq_EF : 15|2@0+ (1,0) [0|3] "SED"  APIM_CDC,APIM_CIM,IPC
 SG_ BrkLamp_UNUSED_1bit_1 : 16|1@0+ (1,0) [1|1] "Unitless"  APIM_CDC,IPC
 SG_ BrkLamp_B_Rq_EF : 17|1@0+ (1,0) [0|1] "SED"  APIM_CDC,APIM_CIM,IPC
 SG_ PrkBrkYwLamp_D_Rq_EF : 19|2@0+ (1,0) [0|3] "SED"  APIM_CDC,APIM_CIM,IPC
 SG_ PrkBrkRedLamp_D_Rq_EF : 21|2@0+ (1,0) [0|3] "SED"  APIM_CDC,APIM_CIM,IPC
 SG_ DrvSlipCtlOffLamp_D_Rq_EF : 23|2@0+ (1,0) [0|3] "SED"  APIM_CDC,APIM_CIM,IPC
 SG_ BrkLamp_UNUSED_8bit_1 : 31|8@0+ (1,0) [255|255] "Unitless"  APIM_CDC,IPC
 SG_ BrkLamp_UNUSED_8bit_2 : 39|8@0+ (1,0) [255|255] "Unitless"  APIM_CDC,IPC
 SG_ BrkLamp_UNUSED_8bit_3 : 47|8@0+ (1,0) [255|255] "Unitless"  APIM_CDC,IPC
 SG_ BrkLamp_UNUSED_8bit_4 : 55|8@0+ (1,0) [255|255] "Unitless"  APIM_CDC,IPC
 SG_ BrkLamp_UNUSED_8bit_5 : 63|8@0+ (1,0) [255|255] "Unitless"  APIM_CDC,IPC

BO_ 118 BrakeSnData_5_HS3: 8 GWM
 SG_ SteWhlComp_An_Est : 6|15@0+ (0.1,-1600) [-1600|1676.7] "degrees"  APIM,APIM_CDC,APIM_CIM,APIM_CISM,IPC
 SG_ StopLamp_B_RqBrk : 7|1@0+ (1,0) [0|1] "SED" Vector__XXX
 SG_ DrvSte_D_Stat : 19|4@0+ (1,0) [0|15] "SED" Vector__XXX
 SG_ EmgcyBrkLamp_D_Rq : 21|2@0+ (1,0) [0|3] "SED" Vector__XXX
 SG_ SteWhlCompAnEst_D_Qf : 23|2@0+ (1,0) [0|3] "SED"  APIM,APIM_CDC,APIM_CIM,APIM_CISM,IPC
 SG_ DrvSte_Tq_Rq : 31|8@0+ (0.0625,-8) [-8|7.9375] "Nm" Vector__XXX
 SG_ BrkTerrMde_D_Actl : 38|3@0+ (1,0) [0|7] "SED" Vector__XXX
 SG_ BrkCtrFnd_B_Stat : 39|1@0+ (1,0) [0|1] "SED" Vector__XXX
 SG_ BrkTerrMdeChng_D_Rdy : 54|3@0+ (1,0) [0|7] "SED" Vector__XXX

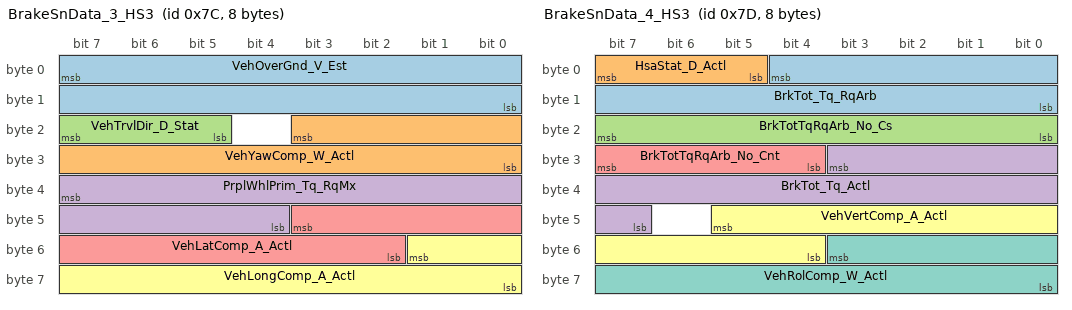
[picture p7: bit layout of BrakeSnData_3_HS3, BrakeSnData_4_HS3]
BO_ 124 BrakeSnData_3_HS3: 8 GWM
 SG_ VehOverGnd_V_Est : 7|16@0+ (0.01,0) [0|655.35] "kph"  APIM,APIM_CDC,APIM_CIM,APIM_CISM,IPC
 SG_ VehYawComp_W_Actl : 19|12@0+ (0.03663,-75) [-75|74.99985] "deg/s"  APIM,APIM_CDC,APIM_CIM,APIM_CISM,ARM,IPC
 SG_ VehTrvlDir_D_Stat : 23|3@0+ (1,0) [0|7] "SED"  GENERIC
 SG_ PrplWhlPrim_Tq_RqMx : 39|12@0+ (8,0) [0|32760] "Nm"  GENERIC
 SG_ VehLatComp_A_Actl : 43|10@0+ (0.035,-17.9) [-17.9|17.905] "m/s^2"  APIM,APIM_CDC,APIM_CIM,APIM_CISM,ARM,IPC
 SG_ VehLongComp_A_Actl : 49|10@0+ (0.035,-17.9) [-17.9|17.905] "m/s^2"  APIM,APIM_CDC,APIM_CIM,APIM_CISM,ARM,IPC

BO_ 125 BrakeSnData_4_HS3: 8 GWM
 SG_ BrkTot_Tq_RqArb : 4|13@0+ (4,0) [0|32764] "Nm"  APIM,APIM_CDC,APIM_CIM,APIM_CISM,TRM_ITRM
 SG_ HsaStat_D_Actl : 7|3@0+ (1,0) [0|7] "SED"  APIM_CDC,APIM_CIM,IPC
 SG_ BrkTotTqRqArb_No_Cs : 23|8@0+ (1,0) [0|255] "unitless"  TRM_ITRM
 SG_ BrkTot_Tq_Actl : 27|13@0+ (4,0) [0|32764] "Nm"  APIM,APIM_CDC,APIM_CIM,APIM_CISM,IPC
 SG_ BrkTotTqRqArb_No_Cnt : 31|4@0+ (1,0) [0|15] "unitless"  TRM_ITRM
 SG_ VehVertComp_A_Actl : 45|10@0+ (0.035,-17.9) [-17.9|17.905] "m/s^2"  APIM,APIM_CDC,APIM_CIM,APIM_CISM
 SG_ VehRolComp_W_Actl : 51|12@0+ (0.03663,-75) [-75|74.99985] "degrees/sec"  APIM,APIM_CDC,APIM_CIM,APIM_CISM,ARM

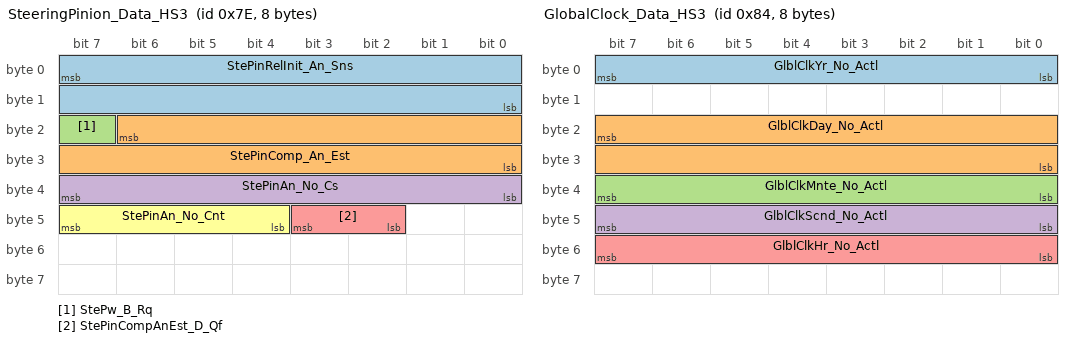
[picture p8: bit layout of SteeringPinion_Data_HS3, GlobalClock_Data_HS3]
BO_ 126 SteeringPinion_Data_HS3: 8 GWM
 SG_ StePinRelInit_An_Sns : 7|16@0+ (0.1,-3200) [-3200|3353.5] "degrees" Vector__XXX
 SG_ StePinComp_An_Est : 22|15@0+ (0.1,-1600) [-1600|1676.7] "degrees"  APIM,APIM_CDC,APIM_CIM,APIM_CISM,ARM,HUD_ADV,IPC
 SG_ StePw_B_Rq : 23|1@0+ (1,0) [0|1] "SED" Vector__XXX
 SG_ StePinAn_No_Cs : 39|8@0+ (1,0) [0|255] "unitless" Vector__XXX
 SG_ StePinCompAnEst_D_Qf : 43|2@0+ (1,0) [0|3] "SED"  APIM,APIM_CDC,APIM_CIM,APIM_CISM,ARM,HUD_ADV,IPC
 SG_ StePinAn_No_Cnt : 47|4@0+ (1,0) [0|15] "unitless" Vector__XXX

BO_ 129 Steering_Wheel_Data2_HS3: 8 GWM
 SG_ SteWhlSwtchDown_B_Stat : 0|1@0+ (1,0) [0|1] "SED"  APIM_CDC,APIM_CIM,HUD_ADV,IPC
 SG_ SteWhlSwtchLeft_B_Stat : 1|1@0+ (1,0) [0|1] "SED"  APIM_CDC,APIM_CIM,IPC
 SG_ SteWhlSwtchRght_B_Stat : 2|1@0+ (1,0) [0|1] "SED"  APIM_CDC,APIM_CIM,IPC
 SG_ SteWhlSwtchUp_B_Stat : 3|1@0+ (1,0) [0|1] "SED"  APIM_CDC,APIM_CIM,HUD_ADV,IPC
 SG_ SteWhlSwtchOk_B_Stat : 4|1@0+ (1,0) [0|1] "SED"  APIM_CDC,APIM_CIM,HUD_ADV,IPC
 SG_ SteEffortInc_B_RqDrv : 5|1@0+ (1,0) [0|1] "SED"  APIM_CDC,APIM_CIM,IPC
 SG_ SelDrvMdeInc_B_RqDrv : 6|1@0+ (1,0) [0|1] "SED"  APIM_CDC,APIM_CIM,IPC
 SG_ SelDrvMdeDec_B_RqDrv : 7|1@0+ (1,0) [0|1] "SED"  APIM_CDC,APIM_CIM,IPC
 SG_ SteWhlSwtchSet_B_Stat : 8|1@0+ (1,0) [0|1] "SED"  APIM_CDC,APIM_CIM,IPC
 SG_ SteWhlSwtchPhon_B_Stat : 9|1@0+ (1,0) [0|1] "SED"  APIM_CDC,APIM_CIM,HUD_ADV,IPC
 SG_ SteWhlSwtchNav_B_Stat : 10|1@0+ (1,0) [0|1] "SED"  APIM_CDC,APIM_CIM,IPC
 SG_ SteWhlSwtchMed_B_Stat : 11|1@0+ (1,0) [0|1] "SED"  APIM_CDC,APIM_CIM,HUD_ADV,IPC
 SG_ SteWhlSwtchIod_B_Stat : 12|1@0+ (1,0) [0|1] "SED"  IPC
 SG_ SteWhlSwtchHud_B_Stat : 13|1@0+ (1,0) [0|1] "SED"  APIM_CDC,APIM_CIM,HUD_ADV,IPC
 SG_ SteWhlSwtchBack_B_Stat : 14|1@0+ (1,0) [0|1] "SED"  APIM_CDC,APIM_CIM,HUD_ADV,IPC
 SG_ SuspDampInc_B_RqDrv : 15|1@0+ (1,0) [0|1] "SED"  APIM_CDC,APIM_CIM,IPC
 SG_ PoliceAux2Swtch_B_Stat : 16|1@0+ (1,0) [0|1] "SED"  TRM_ITRM
 SG_ PoliceAux1Swtch_B_Stat : 17|1@0+ (1,0) [0|1] "SED"  TRM_ITRM
 SG_ SteWhlSwtchInfo_B_Stat : 18|1@0+ (1,0) [0|1] "SED"  APIM_CDC,APIM_CIM,IPC
 SG_ SteWhlSwtchHome_B_Stat : 19|1@0+ (1,0) [0|1] "SED"  APIM_CDC,APIM_CIM,IPC
 SG_ SelDrvMdeSwtch_D_Stat4 : 21|2@0+ (1,0) [0|3] "SED"  APIM,APIM_CDC,APIM_CIM,APIM_CISM
 SG_ SteWhlSwtchMenu_B_Stat : 22|1@0+ (1,0) [0|1] "SED"  APIM_CDC,APIM_CIM,IPC
 SG_ SteWhlSwtchView_B_Stat : 23|1@0+ (1,0) [0|1] "SED"  APIM_CDC,APIM_CIM,IPC
 SG_ SelDrvMdeSwtch3_D_Stat4 : 25|2@0+ (1,0) [0|3] "SED"  GENERIC
 SG_ SelDrvMdeSwtch2_D_Stat4 : 27|2@0+ (1,0) [0|3] "SED"  GENERIC
 SG_ SelDrvMdeSwtch1_D_Stat4 : 29|2@0+ (1,0) [0|3] "SED"  GENERIC
 SG_ PoliceAux4Swtch_B_Stat : 30|1@0+ (1,0) [0|1] "SED"  TRM_ITRM
 SG_ PoliceAux3Swtch_B_Stat : 31|1@0+ (1,0) [0|1] "SED"  TRM_ITRM
 SG_ TiltableSteMsgTxt_D_Rq : 35|4@0+ (1,0) [0|15] "SED"  APIM_CDC,APIM_CIM,IPC
 SG_ AirbagDrv_B_RqDactv : 36|1@0+ (1,0) [0|1] "SED" Vector__XXX
 SG_ SelDrvMdeSwtch4_D_Stat4 : 38|2@0+ (1,0) [0|3] "SED" Vector__XXX
 SG_ EngExhMdeQuiet_B_RqDrv2 : 39|1@0+ (1,0) [0|1] "SED"  APIM_CDC,APIM_CIM,IPC
 SG_ StewSwtchScnd_D_Stat : 40|1@0+ (1,0) [0|1] "SED"  APIM_CDC,APIM_CIM
 SG_ StewSwtchPrimPos_D_St : 44|4@0+ (1,0) [0|15] "SED"  APIM_CDC,APIM_CIM
 SG_ StewSwtchPrim_D_Stat : 45|1@0+ (1,0) [0|1] "SED"  APIM_CDC,APIM_CIM
 SG_ VdsButtnOn_B_Rq : 46|1@0+ (1,0) [0|1] "SED" Vector__XXX
 SG_ VdsButtnActv_B_Rq : 47|1@0+ (1,0) [0|1] "SED" Vector__XXX
 SG_ AirbagDrvRqDac_No_Cnt : 51|4@0+ (1,0) [0|15] "unitless" Vector__XXX
 SG_ StewSwtchScndPos_D_St : 55|4@0+ (1,0) [0|15] "SED"  APIM_CDC,APIM_CIM
 SG_ AirbagDrvRqDac_No_Cs : 63|8@0+ (1,0) [0|255] "unitless" Vector__XXX

BO_ 130 EPAS_INFO_HS3: 8 GWM
 SG_ SteeringColumnTorque : 7|8@0+ (0.0625,-8) [-8|7.9375] "Nm" Vector__XXX
 SG_ EPAS_Failure : 9|2@0+ (1,0) [0|3] "SED"  APIM_CDC,APIM_CIM,IPC
 SG_ DrvSteActv_B_Stat : 10|1@0+ (1,0) [0|1] "SED" Vector__XXX
 SG_ SAPPAngleControlStat2 : 11|1@0+ (1,0) [0|1] "SED" Vector__XXX
 SG_ SAPPAngleControlStat3 : 12|1@0+ (1,0) [0|1] "SED" Vector__XXX
 SG_ SAPPAngleControlStat4 : 13|1@0+ (1,0) [0|1] "SED" Vector__XXX
 SG_ SAPPAngleControlStat5 : 14|1@0+ (1,0) [0|1] "SED" Vector__XXX
 SG_ SAPPAngleControlStat6 : 15|1@0+ (1,0) [0|1] "SED" Vector__XXX
 SG_ SteMdule_I_Est : 21|12@0+ (0.05,-64) [-64|140.75] "Amps" Vector__XXX
 SG_ SAPPAngleControlStat1 : 23|2@0+ (1,0) [0|3] "SED" Vector__XXX
 SG_ TrlrHitchLamp_D_Rqst : 24|1@0+ (1,0) [0|1] "SED" Vector__XXX
 SG_ VehVTrlrAid_B_Rq : 25|1@0+ (1,0) [0|1] "SED" Vector__XXX
 SG_ SteMdule_U_Meas : 39|8@0+ (0.05,6) [6|18.75] "Volts" Vector__XXX
 SG_ DrvSte_Tq_Actl : 47|8@0+ (0.0625,-8) [-8|7.9375] "Nm" Vector__XXX
 SG_ ElPwAsstSte_B_Stat : 49|1@0+ (1,0) [0|1] "SED" Vector__XXX
 SG_ SteEffort_D_Stat : 52|3@0+ (1,0) [0|7] "SED"  APIM_CDC,APIM_CIM,IPC
 SG_ SteMdule_D_Stat : 55|3@0+ (1,0) [0|7] "SED" Vector__XXX
 SG_ Veh_V_RqMxTrlrAid : 63|8@0+ (0.1,0) [0|25.5] "km/h" Vector__XXX

BO_ 131 Steering_Data_HS3: 8 GWM
 SG_ WiprFront_D_Stat : 3|4@0+ (1,0) [0|15] "SED"  APIM,APIM_CDC,APIM_CIM,APIM_CISM,ARM
 SG_ TurnLghtSwtch_D_Stat : 5|2@0+ (1,0) [0|3] "SED"  APIM,APIM_CDC,APIM_CIM,APIM_CISM,ARM,IPC
 SG_ ElPwAsstSte_B_RqDactv : 7|1@0+ (1,0) [0|1] "SED" Vector__XXX
 SG_ CcAslButtnCnclPress : 8|1@0+ (1,0) [0|1] "SED" Vector__XXX
 SG_ AslButtnOnOffPress : 9|1@0+ (1,0) [0|1] "SED" Vector__XXX
 SG_ AslButtnOnOffCnclPress : 10|1@0+ (1,0) [0|1] "SED" Vector__XXX
 SG_ AccButtnGapIncPress : 11|1@0+ (1,0) [0|1] "SED" Vector__XXX
 SG_ AccButtnGapDecPress : 12|1@0+ (1,0) [0|1] "SED" Vector__XXX
 SG_ LghtAmb_D_Sns : 15|3@0+ (1,0) [0|7] "SED" Vector__XXX
 SG_ CcAslButtnOnOffCncl : 16|1@0+ (1,0) [0|1] "SED" Vector__XXX
 SG_ CcAslButtnOffCnclPress : 17|1@0+ (1,0) [0|1] "SED" Vector__XXX
 SG_ CcAslButtnIndxIncPress : 18|1@0+ (1,0) [0|1] "SED" Vector__XXX
 SG_ CcAslButtnIndxDecPress : 19|1@0+ (1,0) [0|1] "SED" Vector__XXX
 SG_ CcAslButtnDeny_B_Actl : 20|1@0+ (1,0) [0|1] "SED" Vector__XXX
 SG_ CcAslButtnCnclResPress : 21|1@0+ (1,0) [0|1] "SED" Vector__XXX
 SG_ LaSwtchPos_D_Stat : 23|2@0+ (1,0) [0|3] "SED" Vector__XXX
 SG_ CcButtnOffPress : 24|1@0+ (1,0) [0|1] "SED" Vector__XXX
 SG_ CcAsllButtnResPress : 25|1@0+ (1,0) [0|1] "SED" Vector__XXX
 SG_ CcAslButtnSetPress : 26|1@0+ (1,0) [0|1] "SED" Vector__XXX
 SG_ CcAslButtnSetIncPress : 27|1@0+ (1,0) [0|1] "SED" Vector__XXX
 SG_ CcAslButtnSetDecPress : 28|1@0+ (1,0) [0|1] "SED" Vector__XXX
 SG_ CcAslButtnResIncPress : 29|1@0+ (1,0) [0|1] "SED" Vector__XXX
 SG_ CcAslButtnResDecPress : 30|1@0+ (1,0) [0|1] "SED" Vector__XXX
 SG_ CcAslButtnOnPress : 31|1@0+ (1,0) [0|1] "SED" Vector__XXX
 SG_ AccButtnGapTogglePress : 32|1@0+ (1,0) [0|1] "SED" Vector__XXX
 SG_ AhbStat_B_Dsply : 33|1@0+ (1,0) [0|1] "SED"  APIM_CDC,APIM_CIM,APIM_CISM,IPC
 SG_ HeadLghtHiOn_B_StatAhb : 34|1@0+ (1,0) [0|1] "SED"  APIM,APIM_CDC,APIM_CIM,APIM_CISM,IPC
 SG_ HeadLghtHiFlash_D_Actl : 36|2@0+ (1,0) [0|3] "SED" Vector__XXX
 SG_ CcButtnOnPress : 37|1@0+ (1,0) [0|1] "SED" Vector__XXX
 SG_ CcButtnOnOffPress : 38|1@0+ (1,0) [0|1] "SED" Vector__XXX
 SG_ CcButtnOnOffCnclPress : 39|1@0+ (1,0) [0|1] "SED" Vector__XXX
 SG_ TjaButtnOnOffPress : 40|1@0+ (1,0) [0|1] "SED" Vector__XXX
 SG_ HeadLghtHiCtrl_D_RqAhb : 43|3@0+ (1,0) [0|7] "SED" Vector__XXX
 SG_ WiprFrontSwtch_D_Stat : 47|4@0+ (1,0) [0|15] "SED"  ARM
 SG_ RainIntensity_D_Stat : 49|3@0+ (1,0) [0|7] "SED" Vector__XXX
 SG_ HeadLghtHiFlash_D_Stat : 51|2@0+ (1,0) [0|3] "SED" Vector__XXX
 SG_ TurnLghtSwtch_D_Arb : 55|4@0+ (1,0) [0|15] "SED" Vector__XXX

BO_ 132 GlobalClock_Data_HS3: 8 GWM
 SG_ GlblClkYr_No_Actl : 7|8@0+ (1,2000) [2000|2255] "year"  ACM,APIM,APIM_CDC,APIM_CIM,APIM_CISM,HUD_ADV,IPC,MRCMB_RDAPM_HS3,RACM_RCIM,TRM_ITRM
 SG_ GlblClkDay_No_Actl : 23|16@0+ (1,0) [0|65535] "julian day"  ACM,APIM,APIM_CDC,APIM_CIM,APIM_CISM,HUD_ADV,IPC,MRCMB_RDAPM_HS3,RACM_RCIM,TRM_ITRM
 SG_ GlblClkMnte_No_Actl : 39|8@0+ (1,0) [0|255] "minute"  APIM,APIM_CDC,APIM_CIM,APIM_CISM,HUD_ADV,IPC,MRCMB_RDAPM_HS3,RACM_RCIM,TRM_ITRM
 SG_ GlblClkScnd_No_Actl : 47|8@0+ (1,0) [0|255] "second"  APIM,APIM_CDC,APIM_CIM,APIM_CISM,HUD_ADV,IPC,MRCMB_RDAPM_HS3,RACM_RCIM,TRM_ITRM
 SG_ GlblClkHr_No_Actl : 55|8@0+ (1,0) [0|255] "hour"  APIM,APIM_CDC,APIM_CIM,APIM_CISM,HUD_ADV,IPC,MRCMB_RDAPM_HS3,RACM_RCIM,TRM_ITRM

BO_ 133 WCMB_Send_Signals: 8 WCMB
 SG_ WrlssAcsyChrg_Pc_Actl2 : 7|7@0+ (1,0) [0|127] "percent"  APIM
 SG_ WrlssAcsyChrgr_D_Stat2 : 15|3@0+ (1,0) [0|7] "SED"  ACM,APIM

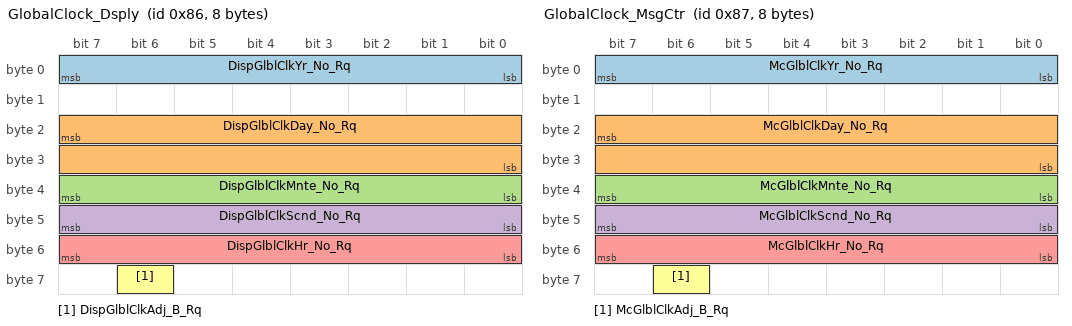
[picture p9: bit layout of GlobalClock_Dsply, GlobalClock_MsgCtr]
BO_ 134 GlobalClock_Dsply: 8 APIM_CDC
 SG_ DispGlblClkYr_No_Rq : 7|8@0+ (1,2000) [2000|2255] "year"  GWM,IPC
 SG_ DispGlblClkDay_No_Rq : 23|16@0+ (1,0) [0|65535] "julian day"  GWM,IPC
 SG_ DispGlblClkMnte_No_Rq : 39|8@0+ (1,0) [0|255] "minute"  GWM,IPC
 SG_ DispGlblClkScnd_No_Rq : 47|8@0+ (1,0) [0|255] "second"  GWM,IPC
 SG_ DispGlblClkHr_No_Rq : 55|8@0+ (1,0) [0|255] "hour"  GWM,IPC
 SG_ DispGlblClkAdj_B_Rq : 62|1@0+ (1,0) [0|1] "SED"  GWM,IPC

BO_ 135 GlobalClock_MsgCtr: 8 APIM_CDC
 SG_ McGlblClkYr_No_Rq : 7|8@0+ (1,2000) [2000|2255] "year"  GWM
 SG_ McGlblClkDay_No_Rq : 23|16@0+ (1,0) [0|65535] "julian day"  GWM
 SG_ McGlblClkMnte_No_Rq : 39|8@0+ (1,0) [0|255] "minute"  GWM
 SG_ McGlblClkScnd_No_Rq : 47|8@0+ (1,0) [0|255] "second"  GWM
 SG_ McGlblClkHr_No_Rq : 55|8@0+ (1,0) [0|255] "hour"  GWM
 SG_ McGlblClkAdj_B_Rq : 62|1@0+ (1,0) [0|1] "SED"  GWM

BO_ 139 CruiseCtrl_Strg_Data_HS3: 8 GWM
 SG_ CcAslButtnIndxDecPres2 : 0|1@0+ (1,0) [0|1] "SED" Vector__XXX
 SG_ CcAslButtnDeny_B_Actl2 : 1|1@0+ (1,0) [0|1] "SED" Vector__XXX
 SG_ CcAslButtnCnclResPres2 : 2|1@0+ (1,0) [0|1] "SED" Vector__XXX
 SG_ CcAslButtnCnclPress2 : 3|1@0+ (1,0) [0|1] "SED" Vector__XXX
 SG_ AslButtnOnOffPress2 : 4|1@0+ (1,0) [0|1] "SED" Vector__XXX
 SG_ AslButtnOnOffCnclPres2 : 5|1@0+ (1,0) [0|1] "SED" Vector__XXX
 SG_ AccButtnGapIncPress2 : 6|1@0+ (1,0) [0|1] "SED" Vector__XXX
 SG_ AccButtnGapDecPress2 : 7|1@0+ (1,0) [0|1] "SED" Vector__XXX
 SG_ CcAslButtnSetIncPress2 : 8|1@0+ (1,0) [0|1] "SED" Vector__XXX
 SG_ CcAslButtnSetDecPress2 : 9|1@0+ (1,0) [0|1] "SED" Vector__XXX
 SG_ CcAslButtnResIncPress2 : 10|1@0+ (1,0) [0|1] "SED" Vector__XXX
 SG_ CcAslButtnResDecPress2 : 11|1@0+ (1,0) [0|1] "SED" Vector__XXX
 SG_ CcAslButtnOnPress2 : 12|1@0+ (1,0) [0|1] "SED" Vector__XXX
 SG_ CcAslButtnOnOffCncl2 : 13|1@0+ (1,0) [0|1] "SED" Vector__XXX
 SG_ CcAslButtnOffCnclPres2 : 14|1@0+ (1,0) [0|1] "SED" Vector__XXX
 SG_ CcAslButtnIndxIncPres2 : 15|1@0+ (1,0) [0|1] "SED" Vector__XXX
 SG_ ActvFrontSteLck_D_Stat : 17|2@0+ (1,0) [0|3] "SED" Vector__XXX
 SG_ CcButtnOnPress2 : 18|1@0+ (1,0) [0|1] "SED" Vector__XXX
 SG_ CcButtnOnOffPress2 : 19|1@0+ (1,0) [0|1] "SED" Vector__XXX
 SG_ CcButtnOnOffCnclPress2 : 20|1@0+ (1,0) [0|1] "SED" Vector__XXX
 SG_ CcButtnOffPress2 : 21|1@0+ (1,0) [0|1] "SED" Vector__XXX
 SG_ CcAsllButtnResPress2 : 22|1@0+ (1,0) [0|1] "SED" Vector__XXX
 SG_ CcAslButtnSetPress2 : 23|1@0+ (1,0) [0|1] "SED" Vector__XXX
 SG_ AfsPw_B_Rq : 24|1@0+ (1,0) [0|1] "SED" Vector__XXX
 SG_ AccButtnGpTogglePress2 : 25|1@0+ (1,0) [0|1] "SED" Vector__XXX
 SG_ TjaButtnOnOffPress2 : 26|1@0+ (1,0) [0|1] "SED" Vector__XXX
 SG_ SelDrvMdeAdptSte_D_Stat : 28|2@0+ (1,0) [0|3] "SED" Vector__XXX
 SG_ ActvFrontSteMsgTxt_D_Rq : 31|3@0+ (1,0) [0|7] "SED"  APIM_CDC,APIM_CIM,IPC

BO_ 140 CruiseCtrl_StrgData2: 8 APIM_CDC
 SG_ StewPosAdjTlt_D_Rq : 1|2@0+ (1,0) [0|3] "SED"  GWM
 SG_ StewPosAdjTel_D_Rq : 3|2@0+ (1,0) [0|3] "SED"  GWM
 SG_ TjaButtnOnOffPress4 : 4|1@0+ (1,0) [0|1] "SED"  GWM
 SG_ AccButtnGapTogglePress3 : 5|1@0+ (1,0) [0|1] "SED"  GWM
 SG_ AccButtnGapIncPress4 : 6|1@0+ (1,0) [0|1] "SED"  GWM
 SG_ AccButtnGapDecPress4 : 7|1@0+ (1,0) [0|1] "SED"  GWM
 SG_ CcAslButtnCnclPress3 : 8|1@0+ (1,0) [0|1] "SED"  GWM
 SG_ AslButtnOnOffPress3 : 9|1@0+ (1,0) [0|1] "SED"  GWM
 SG_ AslButtnOnOffCnclPress2 : 10|1@0+ (1,0) [0|1] "SED"  GWM
 SG_ ExtMirrorAdj_D_Rq : 13|3@0+ (1,0) [0|7] "SED"  GWM
 SG_ MirrorSelFold_D_Rq : 15|2@0+ (1,0) [0|3] "SED"  GWM
 SG_ CcAslButtnOnOffCncl3 : 16|1@0+ (1,0) [0|1] "SED"  GWM
 SG_ CcAslButtnOffCnclPress2 : 17|1@0+ (1,0) [0|1] "SED"  GWM
 SG_ CcAslButtnIndxIncPress2 : 18|1@0+ (1,0) [0|1] "SED"  GWM
 SG_ CcAslButtnIndxDecPress2 : 19|1@0+ (1,0) [0|1] "SED"  GWM
 SG_ CcAslButtnDeny_B_Actl3 : 20|1@0+ (1,0) [0|1] "SED"  GWM
 SG_ CcAslButtnCnclResPress2 : 21|1@0+ (1,0) [0|1] "SED"  GWM
 SG_ SteWhlSwtchMde_D_Stat : 23|2@0+ (1,0) [0|3] "SED"  GWM
 SG_ CcButtnOffPress3 : 24|1@0+ (1,0) [0|1] "SED"  GWM
 SG_ CcAsllButtnResPress3 : 25|1@0+ (1,0) [0|1] "SED"  GWM
 SG_ CcAslButtnSetPress3 : 26|1@0+ (1,0) [0|1] "SED"  GWM
 SG_ CcAslButtnSetIncPress3 : 27|1@0+ (1,0) [0|1] "SED"  GWM
 SG_ CcAslButtnSetDecPress3 : 28|1@0+ (1,0) [0|1] "SED"  GWM
 SG_ CcAslButtnResIncPress3 : 29|1@0+ (1,0) [0|1] "SED"  GWM
 SG_ CcAslButtnResDecPress3 : 30|1@0+ (1,0) [0|1] "SED"  GWM
 SG_ CcAslButtnOnPress3 : 31|1@0+ (1,0) [0|1] "SED"  GWM
 SG_ PdlAdj_D_Rq : 33|2@0+ (1,0) [0|3] "SED"  GWM
 SG_ StewSwtchIlumnat_B_Rq : 34|1@0+ (1,0) [0|1] "SED"  GWM
 SG_ DcacPwResetBttn_D_Stat : 36|2@0+ (1,0) [0|3] "SED"  GWM
 SG_ CcButtnOnPress3 : 37|1@0+ (1,0) [0|1] "SED"  GWM
 SG_ CcButtnOnOffPress3 : 38|1@0+ (1,0) [0|1] "SED"  GWM
 SG_ CcButtnOnOffCnclPress3 : 39|1@0+ (1,0) [0|1] "SED"  GWM
 SG_ BrkMaintMde_D_Rq : 47|2@0+ (1,0) [0|3] "SED"  GWM

BO_ 141 WCMC_Send_Signals: 8 WCMC
 SG_ WrlssAcsyChrg_Pc_Actl3 : 7|7@0+ (1,0) [0|127] "percent"  ACM,APIM
 SG_ WrlssAcsyChrgr_D_Stat3 : 15|3@0+ (1,0) [0|7] "SED"  ACM,APIM

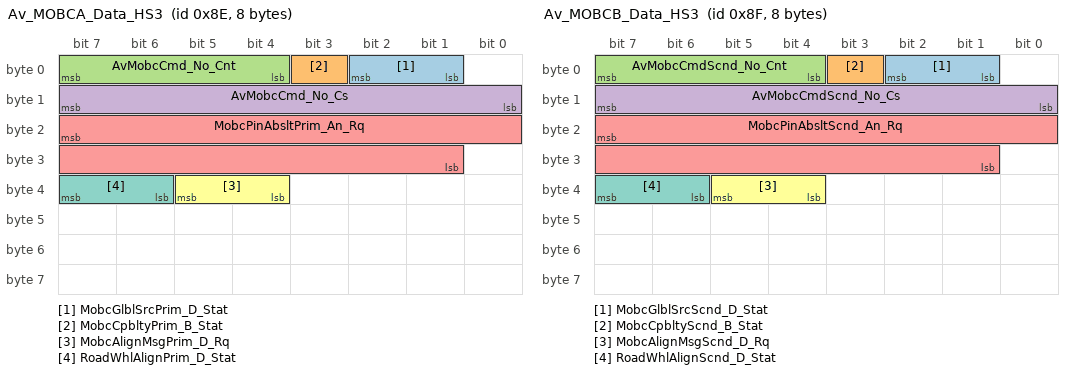
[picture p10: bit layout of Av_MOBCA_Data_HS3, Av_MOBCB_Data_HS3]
BO_ 142 Av_MOBCA_Data_HS3: 8 GWM
 SG_ MobcGlblSrcPrim_D_Stat : 2|2@0+ (1,0) [0|3] "SED" Vector__XXX
 SG_ MobcCpbltyPrim_B_Stat : 3|1@0+ (1,0) [0|1] "SED" Vector__XXX
 SG_ AvMobcCmd_No_Cnt : 7|4@0+ (1,0) [0|15] "unitless" Vector__XXX
 SG_ AvMobcCmd_No_Cs : 15|8@0+ (1,0) [0|255] "unitless" Vector__XXX
 SG_ MobcPinAbsltPrim_An_Rq : 23|15@0+ (0.1,-1600) [-1600|1676.7] "deg" Vector__XXX
 SG_ MobcAlignMsgPrim_D_Rq : 37|2@0+ (1,0) [0|3] "SED"  APIM_CDC
 SG_ RoadWhlAlignPrim_D_Stat : 39|2@0+ (1,0) [0|3] "SED" Vector__XXX

BO_ 143 Av_MOBCB_Data_HS3: 8 GWM
 SG_ MobcGlblSrcScnd_D_Stat : 2|2@0+ (1,0) [0|3] "SED" Vector__XXX
 SG_ MobcCpbltyScnd_B_Stat : 3|1@0+ (1,0) [0|1] "SED" Vector__XXX
 SG_ AvMobcCmdScnd_No_Cnt : 7|4@0+ (1,0) [0|15] "unitless" Vector__XXX
 SG_ AvMobcCmdScnd_No_Cs : 15|8@0+ (1,0) [0|255] "unitless" Vector__XXX
 SG_ MobcPinAbsltScnd_An_Rq : 23|15@0+ (0.1,-1600) [-1600|1676.7] "deg" Vector__XXX
 SG_ MobcAlignMsgScnd_D_Rq : 37|2@0+ (1,0) [0|3] "SED"  APIM_CDC
 SG_ RoadWhlAlignScnd_D_Stat : 39|2@0+ (1,0) [0|3] "SED" Vector__XXX

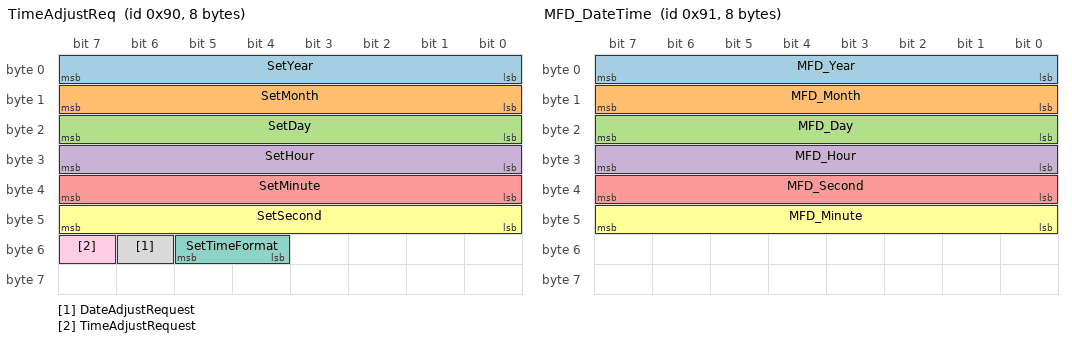
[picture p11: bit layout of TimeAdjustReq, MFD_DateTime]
BO_ 144 TimeAdjustReq: 8 APIM_CISM
 SG_ SetYear : 7|8@0+ (1,2000) [2000|2254] "year"  GENERIC,IPC
 SG_ SetMonth : 15|8@0+ (1,0) [0|12] "month"  GENERIC,IPC
 SG_ SetDay : 23|8@0+ (1,0) [0|31] "day"  GENERIC,IPC
 SG_ SetHour : 31|8@0+ (1,0) [0|23] "hour"  GENERIC,IPC
 SG_ SetMinute : 39|8@0+ (1,0) [0|59] "minute"  GENERIC,IPC
 SG_ SetSecond : 47|8@0+ (1,0) [0|59] "second"  GENERIC,IPC
 SG_ SetTimeFormat : 53|2@0+ (1,0) [0|3] "SED"  IPC
 SG_ DateAdjustRequest : 54|1@0+ (1,0) [0|1] "SED"  GENERIC,IPC
 SG_ TimeAdjustRequest : 55|1@0+ (1,0) [0|1] "SED"  GENERIC,IPC

BO_ 145 MFD_DateTime: 8 APIM_CDC
 SG_ MFD_Year : 7|8@0+ (1,2000) [2000|2254] "year"  DSP,IPC,RACM_RCIM
 SG_ MFD_Month : 15|8@0+ (1,0) [0|12] "month"  DSP,IPC,RACM_RCIM
 SG_ MFD_Day : 23|8@0+ (1,0) [0|31] "day"  DSP,IPC,RACM_RCIM
 SG_ MFD_Hour : 31|8@0+ (1,0) [0|23] "hour"  DSP,IPC,RACM_RCIM
 SG_ MFD_Second : 39|8@0+ (1,0) [0|59] "second"  DSP,IPC,RACM_RCIM
 SG_ MFD_Minute : 47|8@0+ (1,0) [0|59] "minute"  DSP,IPC,RACM_RCIM

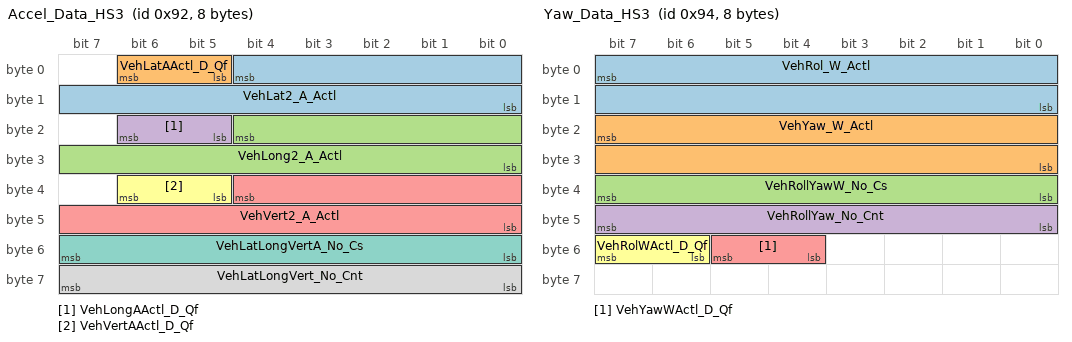
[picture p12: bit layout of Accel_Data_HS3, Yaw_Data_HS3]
BO_ 146 Accel_Data_HS3: 8 GWM
 SG_ VehLat2_A_Actl : 4|13@0+ (0.01,-40) [-40|41.91] "m/s^2" Vector__XXX
 SG_ VehLatAActl_D_Qf : 6|2@0+ (1,0) [0|3] "SED" Vector__XXX
 SG_ VehLong2_A_Actl : 20|13@0+ (0.01,-40) [-40|41.91] "m/s^2"  ACM,APIM_CDC,APIM_CIM,APIM_CISM
 SG_ VehLongAActl_D_Qf : 22|2@0+ (1,0) [0|3] "SED" Vector__XXX
 SG_ VehVert2_A_Actl : 36|13@0+ (0.01,-40) [-40|41.91] "m/s^2" Vector__XXX
 SG_ VehVertAActl_D_Qf : 38|2@0+ (1,0) [0|3] "SED" Vector__XXX
 SG_ VehLatLongVertA_No_Cs : 55|8@0+ (1,0) [0|255] "unitless" Vector__XXX
 SG_ VehLatLongVert_No_Cnt : 63|8@0+ (1,0) [0|255] "unitless" Vector__XXX

BO_ 148 Yaw_Data_HS3: 8 GWM
 SG_ VehRol_W_Actl : 7|16@0+ (0.0002,-6.5) [-6.5|6.607] "rad/s" Vector__XXX
 SG_ VehYaw_W_Actl : 23|16@0+ (0.0002,-6.5) [-6.5|6.607] "rad/s"  ACM,APIM,APIM_CDC,APIM_CIM,APIM_CISM
 SG_ VehRollYawW_No_Cs : 39|8@0+ (1,0) [0|255] "unitless" Vector__XXX
 SG_ VehRollYaw_No_Cnt : 47|8@0+ (1,0) [0|255] "unitless" Vector__XXX
 SG_ VehYawWActl_D_Qf : 53|2@0+ (1,0) [0|3] "SED" Vector__XXX
 SG_ VehRolWActl_D_Qf : 55|2@0+ (1,0) [0|3] "SED" Vector__XXX

BO_ 256 AUX_FrwlAnmtn_Rq_HS3: 8 GWM
 SG_ FrwlAnmtnDsply_D_Rq : 7|2@0+ (1,0) [0|3] "SED"  APIM_CDC,APIM_CIM

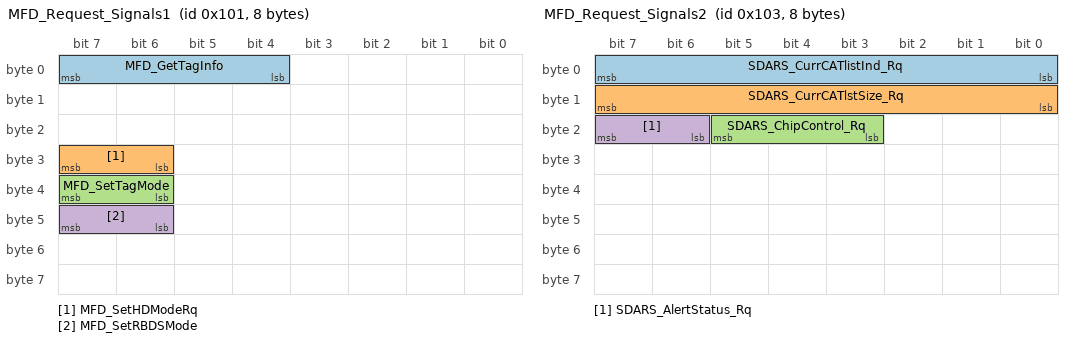
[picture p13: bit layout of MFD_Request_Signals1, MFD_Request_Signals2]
BO_ 257 MFD_Request_Signals1: 8 APIM_CDC
 SG_ MFD_GetTagInfo : 7|4@0+ (1,0) [0|15] "day"  ACM
 SG_ MFD_SetHDModeRq : 31|2@0+ (1,0) [0|3] "SED"  ACM
 SG_ MFD_SetTagMode : 39|2@0+ (1,0) [0|3] "SED"  ACM
 SG_ MFD_SetRBDSMode : 47|2@0+ (1,0) [0|3] "SED"  ACM

BO_ 258 APIM_AmbLght_Rq: 8 APIM_CDC
 SG_ LghtAmbDynmc_D_Rq : 7|2@0+ (1,0) [0|3] "SED"  GWM

BO_ 259 MFD_Request_Signals2: 8 APIM_CDC
 SG_ SDARS_CurrCATlistInd_Rq : 7|8@0+ (1,0) [0|255] "unitless"  ACM
 SG_ SDARS_CurrCATlstSize_Rq : 15|8@0+ (1,0) [0|255] "unitless"  ACM
 SG_ SDARS_ChipControl_Rq : 21|3@0+ (1,0) [0|7] "SED"  ACM
 SG_ SDARS_AlertStatus_Rq : 23|2@0+ (1,0) [0|3] "SED"  ACM

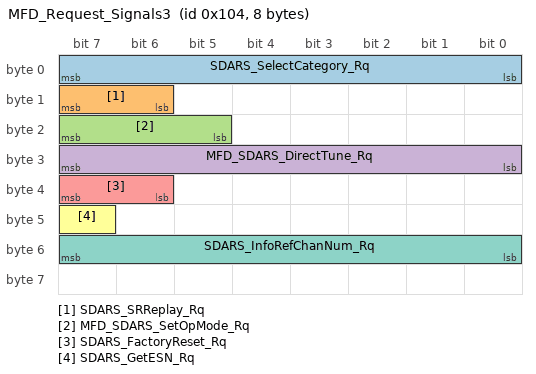
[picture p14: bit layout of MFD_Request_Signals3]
BO_ 260 MFD_Request_Signals3: 8 APIM_CDC
 SG_ SDARS_SelectCategory_Rq : 7|8@0+ (1,0) [0|255] "unitless"  ACM
 SG_ SDARS_SRReplay_Rq : 15|2@0+ (1,0) [0|3] "SED"  ACM
 SG_ MFD_SDARS_SetOpMode_Rq : 23|3@0+ (1,0) [0|7] "SED"  ACM
 SG_ MFD_SDARS_DirectTune_Rq : 31|8@0+ (1,0) [0|255] "unitless"  ACM
 SG_ SDARS_FactoryReset_Rq : 39|2@0+ (1,0) [0|3] "SED"  ACM,DSP
 SG_ SDARS_GetESN_Rq : 47|1@0+ (1,0) [0|1] "SED"  ACM
 SG_ SDARS_InfoRefChanNum_Rq : 55|8@0+ (1,0) [0|255] "unitless"  ACM

BO_TX_BU_ 96 : APIM_CDC,APIM_CIM;
BO_TX_BU_ 97 : APIM_CDC,APIM_CIM;
BO_TX_BU_ 98 : APIM_CDC,APIM_CIM;
BO_TX_BU_ 99 : APIM_CDC,APIM_CIM;
BO_TX_BU_ 100 : APIM,APIM_CDC,APIM_CIM;
BO_TX_BU_ 101 : APIM_CDC,APIM_CIM;
BO_TX_BU_ 102 : APIM_CDC,APIM_CIM;
BO_TX_BU_ 134 : APIM,APIM_CDC,APIM_CIM,APIM_CISM;
BO_TX_BU_ 135 : APIM_CDC,APIM_CIM,IPC;
BO_TX_BU_ 140 : APIM,APIM_CDC,APIM_CIM,IPC;
BO_TX_BU_ 144 : APIM,APIM_CISM;
BO_TX_BU_ 145 : APIM,APIM_CDC,APIM_CIM,APIM_CISM;
BO_TX_BU_ 257 : APIM,APIM_CDC,APIM_CISM;
BO_TX_BU_ 258 : APIM_CDC,APIM_CIM;
BO_TX_BU_ 259 : APIM,APIM_CDC,APIM_CISM;
BO_TX_BU_ 260 : APIM,APIM_CDC,APIM_CISM;

CM_ BU_ ACM "Audio Control Module";
CM_ BU_ APIM "Accessory Protocol Interface Module 4.0";
CM_ BU_ APIM_CDC "Accessory Protocol Interface Module - Cockpit Domain Controller";
CM_ BU_ APIM_CIM "Accessory Protocol Interface Module - Centralized Infotainment Module";
CM_ BU_ APIM_CISM "Accessory Protocol Interface Module - Cockpit Infotainment System Module";
CM_ BU_ ARM "Augmented Reality Module";
CM_ BU_ DSP "Audio Digital Signal Processing Module";
CM_ BU_ ESPM "Ethernet Switch Port Module";
CM_ BU_ FCIMB "Front Controls Interface Module B";
CM_ BU_ GENERIC "Holding pattern ECU for developmental messages";
CM_ BU_ GWM "Gateway Module";
CM_ BU_ HUD_ADV "Advanced HUD";
CM_ BU_ IPC "Instrument Panel Cluster Control Module";
CM_ BU_ MRCMB_RDAPM_HS3 "Movable Roof Control Module B - Right Door Access Panel Module";
CM_ BU_ RACM_RCIM "Rear Audio Control Module - Rear Controls Interface Module";
CM_ BU_ TRM_ITRM "Integrated Trailer Module with TBM on HS2 for FNV2.5";
CM_ BU_ TSTR "Diagnostic Tester";
CM_ BU_ WCM "Wireless Charging Module";
CM_ BU_ WCMB "Wireless Charging Module B";
CM_ BU_ WCMC "Wireless Charging Module C";
CM_ BO_ 74 "Reserve eCallNotification message";
CM_ BO_ 130 "drecker 10/23/09 Need SAPP in sync w/Strg Torque for proper PAM interpretation, else fault msg's displayed FP@20ms IPC needs EPAS_Failure for msg to driver.  Not map w/Lane Assist FP@30s FP), save bandwidth if feature not on vehicle ";
CM_ BO_ 134 "FCDIM APIM TX";
CM_ BO_ 144 "GW Message IMS->BMS";
CM_ BO_ 145 "MFD Shall not send this message when configured as a slave

Method: Clock Modes";
BA_DEF_ BO_  "E2EDataId" INT 0 65535;
BA_DEF_ BO_  "E2EDataLength" INT 0 512;
BA_DEF_  "E2EP01CounterOffset" INT 8 8;
BA_DEF_  "E2EP01DataIdMode" ENUM  "all16Bit","alternating8Bit","lower12Bit","lower8Bit";
BA_DEF_  "E2EP01MaxDeltaCounter" INT 0 65535;
BA_DEF_  "E2EP01MaxDeltaCounterInit" INT 0 65535;
BA_DEF_  "E2EP01MaxErrorStateValid" INT 0 0;
BA_DEF_  "E2EP01MaxNoNewOrRepeatedData" INT 0 0;
BA_DEF_  "E2EP01MinOkStateInit" INT 0 0;
BA_DEF_  "E2EP01MinOkStateInvalid" INT 0 0;
BA_DEF_  "E2EP01MinOkStateValid" INT 0 0;
BA_DEF_  "E2EP01ProfileBehavior" ENUM  "PRE_R4_2","R4_2";
BA_DEF_  "E2EP01ProfileName" STRING ;
BA_DEF_  "E2EP01WindowSize" INT 0 0;
BA_DEF_ BO_  "E2EProfile" STRING ;
BA_DEF_  "ExportInformation" STRING ;
BA_DEF_ BO_  "GenMsgRoutingTimeoutTime" INT 0 5000;
BA_DEF_ BO_  "MessageGateway" ENUM  "No","Yes";
BA_DEF_ BO_  "VFrameFormat" ENUM  "StandardCAN","ExtendedCAN","reserved","reserved","reserved","reserved","reserved","reserved","reserved","reserved","reserved","reserved","reserved","reserved","StandardCAN_FD","ExtendedCAN_FD";
BA_DEF_  "VersionDay" INT 1 31;
BA_DEF_  "VersionMonth" INT 1 12;
BA_DEF_  "VersionNumber" INT 0 10000;
BA_DEF_  "VersionYear" INT 2000 3000;
BA_DEF_ SG_  "ECGUsedRxSignal" ENUM  "No","Yes";
BA_DEF_  "BusType" STRING ;
BA_DEF_ SG_  "ECGUsedTxSignal" ENUM  "No","Yes";
BA_DEF_ SG_  "GenSigInactiveValue" INT 0 100000;
BA_DEF_ SG_  "GenSigSendType" ENUM  "Cyclic","OnWrite","vector_leerstring","OnChange","vector_leerstring","IfActive","vector_leerstring","NoSigSendType";
BA_DEF_ BO_  "NetworkInitialization" ENUM  "No","Yes";
BA_DEF_ SG_  "GenSigStartValue" HEX 0 268435455;
BA_DEF_ BO_  "GenMsgStartDelayTime" INT 0 10000;
BA_DEF_ SG_  "WakeupSignal" ENUM  "No","Yes";
BA_DEF_ BO_  "GenMsgNrOfRepetition" INT 0 100;
BA_DEF_ BO_  "GenMsgDelayTime" INT 0 1000;
BA_DEF_ BO_  "GenMsgCycleTime" INT 0 100000;
BA_DEF_ BO_  "GenMsgSendType" ENUM  "FixedPeriodic","Event","EnabledPeriodic","NotUsed","NotUsed","EventPeriodic","NotUsed","NotUsed","NoMsgSendType";
BA_DEF_ BO_  "FrameRouting" STRING ;
BA_DEF_ BO_  "TpTxIndex" INT 0 536870911;
BA_DEF_ BO_  "OvtpPushApplication" ENUM  "FALSE","TRUE";
BA_DEF_ BO_  "SCP_FreshnessValueLength" INT 0 512;
BA_DEF_ BO_  "SCP_FreshnessValueTxLength" INT 0 512;
BA_DEF_ BO_  "SCP_AuthInfoTxLength" INT 0 512;
BA_DEF_ BO_  "NmAsrMessage" ENUM  "No","Yes";
BA_DEF_ BO_  "DiagState" ENUM  "No","Yes";
BA_DEF_ BO_  "DiagRequest" ENUM  "No","Yes";
BA_DEF_ BO_  "DiagResponse" ENUM  "No","Yes";
BA_DEF_ BO_  "GenMsgILSupport" ENUM  "No","Yes";
BA_DEF_ BU_  "OvtpOperationMode" ENUM  "SERVER","CLIENT";
BA_DEF_ BU_  "OvtpEcuAddress" INT 0 1022;
BA_DEF_ BU_  "ILUsed" ENUM  "No","Yes";
BA_DEF_ BU_  "Terminator" ENUM  "No","Yes";
BA_DEF_ BU_  "NodeWakeUpTime" INT 0 10000;
BA_DEF_ BU_  "NodeStartUpTime" INT 0 10000;
BA_DEF_ BU_  "NmAsrNodeIdentifier" HEX 0 255;
BA_DEF_ BU_  "NmAsrNode" ENUM  "No","Yes";
BA_DEF_ BU_  "PowerType" ENUM  "Switched","Latched","Sleep","vector_leerstring","vector_leerstring";
BA_DEF_ BU_  "NmStationAddress" INT 0 255;
BA_DEF_ BU_  "GatewayECU" ENUM  "No","Yes";
BA_DEF_  "NetworkSpeed" ENUM  "500kBits/s","125kBit/s";
BA_DEF_  "NmType" STRING ;
BA_DEF_  "NmAsrMessageCount" INT 128 256;
BA_DEF_  "NmAsrBaseAddress" HEX 1280 1408;
BA_DEF_  "DBName" STRING ;
BA_DEF_  "Manufacturer" STRING ;
BA_DEF_  "NmBaseAddress" HEX 1280 1280;
BA_DEF_  "NmMessageCount" INT 0 128;
BA_DEF_ SG_  "SystemSignalLongSymbol" STRING ;
BA_DEF_ BO_  "SystemMessageLongSymbol" STRING ;
BA_DEF_DEF_  "E2EDataId" 1;
BA_DEF_DEF_  "E2EDataLength" 0;
BA_DEF_DEF_  "E2EP01CounterOffset" 8;
BA_DEF_DEF_  "E2EP01DataIdMode" "all16Bit";
BA_DEF_DEF_  "E2EP01MaxDeltaCounter" 10;
BA_DEF_DEF_  "E2EP01MaxDeltaCounterInit" 9;
BA_DEF_DEF_  "E2EP01MaxErrorStateValid" 0;
BA_DEF_DEF_  "E2EP01MaxNoNewOrRepeatedData" 2;
BA_DEF_DEF_  "E2EP01MinOkStateInit" 1;
BA_DEF_DEF_  "E2EP01MinOkStateInvalid" 1;
BA_DEF_DEF_  "E2EP01MinOkStateValid" 1;
BA_DEF_DEF_  "E2EP01ProfileBehavior" "R4_2";
BA_DEF_DEF_  "E2EP01ProfileName" "PROFILE_01";
BA_DEF_DEF_  "E2EP01WindowSize" 1;
BA_DEF_DEF_  "E2EProfile" "";
BA_DEF_DEF_  "ExportInformation" "";
BA_DEF_DEF_  "GenMsgRoutingTimeoutTime" 0;
BA_DEF_DEF_  "MessageGateway" "No";
BA_DEF_DEF_  "VFrameFormat" "StandardCAN";
BA_DEF_DEF_  "VersionDay" 1;
BA_DEF_DEF_  "VersionMonth" 1;
BA_DEF_DEF_  "VersionNumber" 1;
BA_DEF_DEF_  "VersionYear" 2011;
BA_DEF_DEF_  "ECGUsedRxSignal" "No";
BA_DEF_DEF_  "BusType" "";
BA_DEF_DEF_  "ECGUsedTxSignal" "No";
BA_DEF_DEF_  "GenSigInactiveValue" 0;
BA_DEF_DEF_  "GenSigSendType" "NoSigSendType";
BA_DEF_DEF_  "NetworkInitialization" "Yes";
BA_DEF_DEF_  "GenSigStartValue" 0;
BA_DEF_DEF_  "GenMsgStartDelayTime" 0;
BA_DEF_DEF_  "WakeupSignal" "No";
BA_DEF_DEF_  "GenMsgNrOfRepetition" 1;
BA_DEF_DEF_  "GenMsgDelayTime" 20;
BA_DEF_DEF_  "GenMsgCycleTime" 0;
BA_DEF_DEF_  "GenMsgSendType" "NoMsgSendType";
BA_DEF_DEF_  "FrameRouting" "";
BA_DEF_DEF_  "TpTxIndex" 0;
BA_DEF_DEF_  "OvtpPushApplication" "FALSE";
BA_DEF_DEF_  "SCP_FreshnessValueLength" 64;
BA_DEF_DEF_  "SCP_FreshnessValueTxLength" 11;
BA_DEF_DEF_  "SCP_AuthInfoTxLength" 53;
BA_DEF_DEF_  "NmAsrMessage" "No";
BA_DEF_DEF_  "DiagState" "No";
BA_DEF_DEF_  "DiagRequest" "No";
BA_DEF_DEF_  "DiagResponse" "No";
BA_DEF_DEF_  "GenMsgILSupport" "Yes";
BA_DEF_DEF_  "OvtpOperationMode" "SERVER";
BA_DEF_DEF_  "OvtpEcuAddress" 0;
BA_DEF_DEF_  "ILUsed" "Yes";
BA_DEF_DEF_  "Terminator" "No";
BA_DEF_DEF_  "NodeWakeUpTime" 10;
BA_DEF_DEF_  "NodeStartUpTime" 250;
BA_DEF_DEF_  "NmAsrNodeIdentifier" 128;
BA_DEF_DEF_  "NmAsrNode" "No";
BA_DEF_DEF_  "PowerType" "Switched";
BA_DEF_DEF_  "NmStationAddress" 0;
BA_DEF_DEF_  "GatewayECU" "No";
BA_DEF_DEF_  "NetworkSpeed" "500kBits/s";
BA_DEF_DEF_  "NmType" "Ford-OSEK";
BA_DEF_DEF_  "NmAsrMessageCount" 254;
BA_DEF_DEF_  "NmAsrBaseAddress" 1281;
BA_DEF_DEF_  "DBName" "";
BA_DEF_DEF_  "Manufacturer" "Ford";
BA_DEF_DEF_  "NmBaseAddress" 1280;
BA_DEF_DEF_  "NmMessageCount" 1;
BA_DEF_DEF_  "SystemSignalLongSymbol" "";
BA_DEF_DEF_  "SystemMessageLongSymbol" "";
BA_ "VersionYear" 2023;
BA_ "VersionNumber" 5;
BA_ "VersionMonth" 4;
BA_ "VersionDay" 6;
BA_ "NmAsrMessageCount" 128;
BA_ "NmAsrBaseAddress" 1408;
BA_ "ExportInformation" "2023_04_06_15_30_DFAUCHER_51984";
BA_ "E2EP01ProfileName" "PROFILE_01A";
BA_ "E2EP01MaxErrorStateValid" 1;
BA_ "E2EP01MaxDeltaCounterInit" 2;
BA_ "BusType" "CAN";
BA_ "DBName" "HS3_CAN";
BA_ "PowerType" BU_ ACM 2;
BA_ "OvtpEcuAddress" BU_ ACM 128;
BA_ "NodeWakeUpTime" BU_ ACM 150;
BA_ "NodeStartUpTime" BU_ ACM 1000;
BA_ "NmStationAddress" BU_ ACM 12;
BA_ "NmAsrNodeIdentifier" BU_ ACM 140;
BA_ "NmAsrNode" BU_ ACM 1;
BA_ "PowerType" BU_ APIM 2;
BA_ "OvtpEcuAddress" BU_ APIM 137;
BA_ "NodeWakeUpTime" BU_ APIM 150;
BA_ "NodeStartUpTime" BU_ APIM 1000;
BA_ "NmStationAddress" BU_ APIM 98;
BA_ "NmAsrNodeIdentifier" BU_ APIM 226;
BA_ "NmAsrNode" BU_ APIM 1;
BA_ "Terminator" BU_ APIM_CDC 1;
BA_ "PowerType" BU_ APIM_CDC 2;
BA_ "OvtpEcuAddress" BU_ APIM_CDC 137;
BA_ "NodeWakeUpTime" BU_ APIM_CDC 150;
BA_ "NodeStartUpTime" BU_ APIM_CDC 1000;
BA_ "NmStationAddress" BU_ APIM_CDC 98;
BA_ "NmAsrNodeIdentifier" BU_ APIM_CDC 226;
BA_ "NmAsrNode" BU_ APIM_CDC 1;
BA_ "Terminator" BU_ APIM_CIM 1;
BA_ "PowerType" BU_ APIM_CIM 2;
BA_ "OvtpEcuAddress" BU_ APIM_CIM 137;
BA_ "NodeWakeUpTime" BU_ APIM_CIM 150;
BA_ "NodeStartUpTime" BU_ APIM_CIM 1000;
BA_ "NmStationAddress" BU_ APIM_CIM 98;
BA_ "NmAsrNodeIdentifier" BU_ APIM_CIM 226;
BA_ "NmAsrNode" BU_ APIM_CIM 1;
BA_ "PowerType" BU_ APIM_CISM 2;
BA_ "OvtpEcuAddress" BU_ APIM_CISM 137;
BA_ "NodeWakeUpTime" BU_ APIM_CISM 150;
BA_ "NodeStartUpTime" BU_ APIM_CISM 1000;
BA_ "NmStationAddress" BU_ APIM_CISM 98;
BA_ "NmAsrNodeIdentifier" BU_ APIM_CISM 226;
BA_ "NmAsrNode" BU_ APIM_CISM 1;
BA_ "PowerType" BU_ ARM 1;
BA_ "OvtpEcuAddress" BU_ ARM 211;
BA_ "NodeWakeUpTime" BU_ ARM 100;
BA_ "NmStationAddress" BU_ ARM 220;
BA_ "NmAsrNodeIdentifier" BU_ ARM 220;
BA_ "NmAsrNode" BU_ ARM 1;
BA_ "PowerType" BU_ DSP 2;
BA_ "OvtpEcuAddress" BU_ DSP 9;
BA_ "NodeWakeUpTime" BU_ DSP 150;
BA_ "NmStationAddress" BU_ DSP 70;
BA_ "NmAsrNodeIdentifier" BU_ DSP 198;
BA_ "NmAsrNode" BU_ DSP 1;
BA_ "PowerType" BU_ ESPM 2;
BA_ "OvtpEcuAddress" BU_ ESPM 207;
BA_ "NodeWakeUpTime" BU_ ESPM 100;
BA_ "NodeStartUpTime" BU_ ESPM 100;
BA_ "NmStationAddress" BU_ ESPM 108;
BA_ "NmAsrNodeIdentifier" BU_ ESPM 108;
BA_ "NmAsrNode" BU_ ESPM 1;
BA_ "OvtpEcuAddress" BU_ FCIMB 71;
BA_ "NodeWakeUpTime" BU_ FCIMB 100;
BA_ "NmStationAddress" BU_ FCIMB 210;
BA_ "NodeWakeUpTime" BU_ GENERIC 100;
BA_ "Terminator" BU_ GWM 1;
BA_ "PowerType" BU_ GWM 2;
BA_ "OvtpOperationMode" BU_ GWM 1;
BA_ "OvtpEcuAddress" BU_ GWM 216;
BA_ "NodeWakeUpTime" BU_ GWM 100;
BA_ "NodeStartUpTime" BU_ GWM 100;
BA_ "NmStationAddress" BU_ GWM 30;
BA_ "NmAsrNodeIdentifier" BU_ GWM 158;
BA_ "NmAsrNode" BU_ GWM 1;
BA_ "GatewayECU" BU_ GWM 1;
BA_ "PowerType" BU_ HUD_ADV 2;
BA_ "OvtpEcuAddress" BU_ HUD_ADV 6;
BA_ "NodeWakeUpTime" BU_ HUD_ADV 150;
BA_ "NodeStartUpTime" BU_ HUD_ADV 1000;
BA_ "NmStationAddress" BU_ HUD_ADV 27;
BA_ "NmAsrNodeIdentifier" BU_ HUD_ADV 155;
BA_ "NmAsrNode" BU_ HUD_ADV 1;
BA_ "Terminator" BU_ IPC 1;
BA_ "PowerType" BU_ IPC 2;
BA_ "OvtpEcuAddress" BU_ IPC 96;
BA_ "NodeWakeUpTime" BU_ IPC 100;
BA_ "NodeStartUpTime" BU_ IPC 1000;
BA_ "NmStationAddress" BU_ IPC 17;
BA_ "NmAsrNodeIdentifier" BU_ IPC 145;
BA_ "NmAsrNode" BU_ IPC 1;
BA_ "PowerType" BU_ MRCMB_RDAPM_HS3 2;
BA_ "OvtpEcuAddress" BU_ MRCMB_RDAPM_HS3 51;
BA_ "NodeWakeUpTime" BU_ MRCMB_RDAPM_HS3 350;
BA_ "NodeStartUpTime" BU_ MRCMB_RDAPM_HS3 350;
BA_ "NmStationAddress" BU_ MRCMB_RDAPM_HS3 76;
BA_ "NmAsrNodeIdentifier" BU_ MRCMB_RDAPM_HS3 204;
BA_ "NmAsrNode" BU_ MRCMB_RDAPM_HS3 1;
BA_ "PowerType" BU_ RACM_RCIM 2;
BA_ "OvtpEcuAddress" BU_ RACM_RCIM 140;
BA_ "NodeWakeUpTime" BU_ RACM_RCIM 150;
BA_ "NodeStartUpTime" BU_ RACM_RCIM 1000;
BA_ "NmStationAddress" BU_ RACM_RCIM 24;
BA_ "NmAsrNodeIdentifier" BU_ RACM_RCIM 152;
BA_ "NmAsrNode" BU_ RACM_RCIM 1;
BA_ "PowerType" BU_ TRM_ITRM 2;
BA_ "OvtpEcuAddress" BU_ TRM_ITRM 36;
BA_ "NodeWakeUpTime" BU_ TRM_ITRM 150;
BA_ "NodeStartUpTime" BU_ TRM_ITRM 1000;
BA_ "NmStationAddress" BU_ TRM_ITRM 84;
BA_ "NmAsrNodeIdentifier" BU_ TRM_ITRM 212;
BA_ "NmAsrNode" BU_ TRM_ITRM 1;
BA_ "NodeWakeUpTime" BU_ TSTR 100;
BA_ "PowerType" BU_ WCM 2;
BA_ "OvtpEcuAddress" BU_ WCM 64;
BA_ "NodeWakeUpTime" BU_ WCM 150;
BA_ "NodeStartUpTime" BU_ WCM 1000;
BA_ "NmStationAddress" BU_ WCM 31;
BA_ "NmAsrNodeIdentifier" BU_ WCM 159;
BA_ "NmAsrNode" BU_ WCM 1;
BA_ "PowerType" BU_ WCMB 2;
BA_ "OvtpEcuAddress" BU_ WCMB 112;
BA_ "NodeWakeUpTime" BU_ WCMB 150;
BA_ "NodeStartUpTime" BU_ WCMB 1000;
BA_ "NmStationAddress" BU_ WCMB 57;
BA_ "NmAsrNodeIdentifier" BU_ WCMB 57;
BA_ "NmAsrNode" BU_ WCMB 1;
BA_ "PowerType" BU_ WCMC 2;
BA_ "OvtpEcuAddress" BU_ WCMC 84;
BA_ "NodeWakeUpTime" BU_ WCMC 150;
BA_ "NodeStartUpTime" BU_ WCMC 1000;
BA_ "NmStationAddress" BU_ WCMC 58;
BA_ "NmAsrNodeIdentifier" BU_ WCMC 58;
BA_ "NmAsrNode" BU_ WCMC 1;
BA_ "MessageGateway" BO_ 74 1;
BA_ "GenMsgSendType" BO_ 74 5;
BA_ "GenMsgRoutingTimeoutTime" BO_ 74 300;
BA_ "GenMsgCycleTime" BO_ 74 1000;
BA_ "MessageGateway" BO_ 75 1;
BA_ "GenMsgSendType" BO_ 75 5;
BA_ "GenMsgRoutingTimeoutTime" BO_ 75 300;
BA_ "GenMsgCycleTime" BO_ 75 1000;
BA_ "GenMsgDelayTime" BO_ 76 10;
BA_ "FrameRouting" BO_ 76 "HS2_CAN,0x4C;FD1_CAN,0x4C;";
BA_ "FrameRouting" BO_ 90 "FD3_CAN,0x5A;";
BA_ "FrameRouting" BO_ 92 "FD1_CAN,0x5C;";
BA_ "GenMsgSendType" BO_ 96 5;
BA_ "GenMsgCycleTime" BO_ 96 1000;
BA_ "GenMsgSendType" BO_ 97 5;
BA_ "GenMsgCycleTime" BO_ 97 1000;
BA_ "GenMsgSendType" BO_ 98 5;
BA_ "GenMsgCycleTime" BO_ 98 1000;
BA_ "GenMsgSendType" BO_ 99 5;
BA_ "GenMsgCycleTime" BO_ 99 1000;
BA_ "GenMsgSendType" BO_ 100 5;
BA_ "GenMsgCycleTime" BO_ 100 1000;
BA_ "GenMsgSendType" BO_ 101 5;
BA_ "GenMsgCycleTime" BO_ 101 1000;
BA_ "GenMsgSendType" BO_ 102 5;
BA_ "GenMsgCycleTime" BO_ 102 1000;
BA_ "GenMsgSendType" BO_ 103 5;
BA_ "GenMsgCycleTime" BO_ 103 1000;
BA_ "GenMsgSendType" BO_ 104 5;
BA_ "GenMsgCycleTime" BO_ 104 1000;
BA_ "GenMsgSendType" BO_ 105 5;
BA_ "GenMsgCycleTime" BO_ 105 1000;
BA_ "GenMsgSendType" BO_ 106 5;
BA_ "GenMsgCycleTime" BO_ 106 1000;
BA_ "GenMsgSendType" BO_ 107 5;
BA_ "GenMsgCycleTime" BO_ 107 1000;
BA_ "GenMsgSendType" BO_ 109 1;
BA_ "GenMsgDelayTime" BO_ 109 0;
BA_ "GenMsgSendType" BO_ 110 5;
BA_ "GenMsgDelayTime" BO_ 110 0;
BA_ "GenMsgCycleTime" BO_ 110 1000;
BA_ "FrameRouting" BO_ 112 "MS1_CAN,0x70;";
BA_ "FrameRouting" BO_ 117 "FD1_CAN,0x75;";
BA_ "FrameRouting" BO_ 118 "FD1_CAN,0x76;";
BA_ "FrameRouting" BO_ 124 "FD1_CAN,0x77;";
BA_ "FrameRouting" BO_ 125 "FD1_CAN,0x7D;";
BA_ "FrameRouting" BO_ 126 "FD3_CAN,0x7E;FD1_CAN,0x7E;";
BA_ "FrameRouting" BO_ 129 "FD3_CAN,0x81;HS2_CAN,0x81;HS2_CAN,0x81;";
BA_ "FrameRouting" BO_ 130 "FD1_CAN,0x82;FD3_CAN,0x82;";
BA_ "FrameRouting" BO_ 131 "FD3_CAN,0x83;HS2_CAN,0x83;";
BA_ "FrameRouting" BO_ 132 "FD1_CAN,0x84;";
BA_ "GenMsgSendType" BO_ 133 5;
BA_ "GenMsgCycleTime" BO_ 133 1000;
BA_ "GenMsgSendType" BO_ 134 1;
BA_ "NetworkInitialization" BO_ 135 0;
BA_ "GenMsgSendType" BO_ 135 1;
BA_ "FrameRouting" BO_ 139 "HS2_CAN,0x8B;";
BA_ "GenMsgSendType" BO_ 140 5;
BA_ "GenMsgCycleTime" BO_ 140 1000;
BA_ "GenMsgSendType" BO_ 141 5;
BA_ "GenMsgCycleTime" BO_ 141 1000;
BA_ "GenMsgDelayTime" BO_ 142 0;
BA_ "FrameRouting" BO_ 142 "FD1_CAN,0x8E;";
BA_ "GenMsgDelayTime" BO_ 143 0;
BA_ "FrameRouting" BO_ 143 "FD8_CAN,0x8F;";
BA_ "GenMsgSendType" BO_ 144 1;
BA_ "GenMsgSendType" BO_ 145 1;
BA_ "FrameRouting" BO_ 146 "HS2_CAN,0x92;FD1_CAN,0x92;";
BA_ "FrameRouting" BO_ 148 "HS2_CAN,0x91;FD1_CAN,0x91;";
BA_ "FrameRouting" BO_ 256 "MS1_CAN,0x100;";
BA_ "GenMsgSendType" BO_ 257 1;
BA_ "GenMsgSendType" BO_ 258 5;
BA_ "GenMsgCycleTime" BO_ 258 50;
BA_ "GenMsgSendType" BO_ 259 1;
BA_ "GenMsgSendType" BO_ 260 1;
BA_ "GenSigStartValue" SG_ 74 eCallNotification 1;
BA_ "GenSigSendType" SG_ 74 eCallNotification 3;
BA_ "GenSigSendType" SG_ 74 VedsDrvBag_D_Ltchd 3;
BA_ "GenSigSendType" SG_ 74 VedsDrvBelt_D_Ltchd 3;
BA_ "GenSigSendType" SG_ 74 VedsDrvCrtnBag_D_Ltchd 3;
BA_ "GenSigSendType" SG_ 74 VedsDrvSideBag_D_Ltchd 3;
BA_ "GenSigSendType" SG_ 74 VedsEvntRoll_D_Ltchd 3;
BA_ "GenSigSendType" SG_ 74 VedsEvntType_D_Ltchd 3;
BA_ "GenSigSendType" SG_ 74 VedsMultiEvnt_D_Ltchd 3;
BA_ "GenSigSendType" SG_ 74 VedsPasBag_D_Ltchd 3;
BA_ "GenSigSendType" SG_ 74 VedsPasBelt_D_Ltchd 3;
BA_ "GenSigSendType" SG_ 74 VedsPasCrtnBag_D_Ltchd 3;
BA_ "GenSigSendType" SG_ 74 VedsPasSideBag_D_Ltchd 3;
BA_ "GenSigSendType" SG_ 74 VedsDrvKneeBag_D_Ltchd 3;
BA_ "GenSigSendType" SG_ 75 VedsRw1DrvBckl_D_Ltchd 3;
BA_ "GenSigSendType" SG_ 75 VedsRw1PasBckl_D_Ltchd 3;
BA_ "GenSigSendType" SG_ 75 VedsRw1PasChld_D_Ltchd 3;
BA_ "GenSigSendType" SG_ 75 VedsRw2dBckl_D_Ltchd 3;
BA_ "GenSigSendType" SG_ 75 VedsRw2mBckl_D_Ltchd 3;
BA_ "GenSigSendType" SG_ 75 VedsRw2pBckl_D_Ltchd 3;
BA_ "GenSigSendType" SG_ 75 VedsRw3dBckl_D_Ltchd 3;
BA_ "GenSigSendType" SG_ 75 VedsRw3mBckl_D_Ltchd 3;
BA_ "GenSigSendType" SG_ 75 VedsRw2dRib_D_Ltchd 3;
BA_ "GenSigSendType" SG_ 75 VedsRw3pBckl_D_Ltchd 3;
BA_ "GenSigSendType" SG_ 75 VedsRw1mBelt_D_Ltchd 3;
BA_ "GenSigSendType" SG_ 75 VedsRw2pRib_D_Ltchd 3;
BA_ "GenSigSendType" SG_ 75 VedsPasKneeBag_D_Ltchd 3;
BA_ "GenSigSendType" SG_ 75 VedsRw1mBckl_D_Ltchd 3;
BA_ "GenSigSendType" SG_ 75 VedsRw3pRib_D_Ltchd 3;
BA_ "GenSigSendType" SG_ 75 VedsRw3dRib_D_Ltchd 3;
BA_ "WakeupSignal" SG_ 76 RstrnImpactEvntStatus 1;
BA_ "GenSigStartValue" SG_ 76 PsngrFrntDetct_D_Actl 3;
BA_ "GenSigStartValue" SG_ 76 SecondRowBuckleMid 3;
BA_ "GenSigStartValue" SG_ 76 SecondRowBuckleDriver 3;
BA_ "GenSigStartValue" SG_ 76 FirstRowBucklePsngr 3;
BA_ "GenSigStartValue" SG_ 76 FirstRowBuckleDriver 3;
BA_ "GenSigStartValue" SG_ 76 ThirdRowBucklePsngr 3;
BA_ "GenSigStartValue" SG_ 76 ThirdRowBuckleMid 3;
BA_ "GenSigStartValue" SG_ 76 ThirdRowBuckleDriver 3;
BA_ "GenSigStartValue" SG_ 76 SecondRowBucklePsngr 3;
BA_ "GenSigStartValue" SG_ 76 PsngrFmidDetct_D_Actl 3;
BA_ "GenSigStartValue" SG_ 76 FirstRowBuckleMid 3;
BA_ "GenSigStartValue" SG_ 76 PassRstrnInd_Req 3;
BA_ "GenSigStartValue" SG_ 76 PassRstrnIndB_Req 3;
BA_ "WakeupSignal" SG_ 90 TrnGearButtn_B_ActlN0 1;
BA_ "WakeupSignal" SG_ 90 TrnGearButtn_B_ActlM2 1;
BA_ "WakeupSignal" SG_ 90 TrnGearButtn_B_ActlM1 1;
BA_ "WakeupSignal" SG_ 90 TrnGearButtn_B_ActlM0 1;
BA_ "WakeupSignal" SG_ 90 TrnGearButtn_B_ActlD2 1;
BA_ "WakeupSignal" SG_ 90 TrnGearButtn_B_ActlD1 1;
BA_ "WakeupSignal" SG_ 90 TrnGearButtn_B_ActlD0 1;
BA_ "WakeupSignal" SG_ 90 TrnGearButtn_B_ActlR2 1;
BA_ "WakeupSignal" SG_ 90 TrnGearButtn_B_ActlR1 1;
BA_ "WakeupSignal" SG_ 90 TrnGearButtn_B_ActlR0 1;
BA_ "WakeupSignal" SG_ 90 TrnGearButtn_B_ActlP2 1;
BA_ "WakeupSignal" SG_ 90 TrnGearButtn_B_ActlP1 1;
BA_ "WakeupSignal" SG_ 90 TrnGearButtn_B_ActlP0 1;
BA_ "WakeupSignal" SG_ 90 TrnGearButtn_B_ActlN2 1;
BA_ "WakeupSignal" SG_ 90 TrnGearButtn_B_ActlN1 1;
BA_ "WakeupSignal" SG_ 90 TrnGearButtn_U_Actl 1;
BA_ "WakeupSignal" SG_ 90 TrnGear_D_RqDrv 1;
BA_ "GenSigStartValue" SG_ 90 DrQltyDrv_D_StatGsm 6;
BA_ "GenSigStartValue" SG_ 90 TrnRng_D_RqGsm 14;
BA_ "GenSigStartValue" SG_ 92 TrnSbwSysHlth_D_Actl 1;
BA_ "GenSigStartValue" SG_ 92 PrkBrkActv_D_RqTrnGear 1;
BA_ "GenSigStartValue" SG_ 92 TrnLvrV_D_Rq 1;
BA_ "WakeupSignal" SG_ 92 TrnDtpCmd_D_Actl 1;
BA_ "GenSigStartValue" SG_ 92 TrnDtpCmd_D_Actl 1;
BA_ "GenSigSendType" SG_ 96 MixblChnlZone1_D_Stat 3;
BA_ "GenSigSendType" SG_ 96 MixblChnlZone2_D_Stat 3;
BA_ "GenSigSendType" SG_ 96 SrcTypeChnl_D_Stat 3;
BA_ "GenSigSendType" SG_ 96 SrcTypeChnlZone2_D_St 3;
BA_ "GenSigSendType" SG_ 96 CabnMixblPrmpt_B_Stat 3;
BA_ "GenSigSendType" SG_ 96 SpkrSel_D_Rq 3;
BA_ "GenSigSendType" SG_ 96 SrcType_D_Stat 3;
BA_ "GenSigSendType" SG_ 96 MixblPrmptZone1_B_Stat 3;
BA_ "GenSigSendType" SG_ 96 SrcTypeActv_D_Stat 3;
BA_ "GenSigSendType" SG_ 96 SrcTypeZone2_D_Stat 3;
BA_ "GenSigSendType" SG_ 96 MixblPrmptZone2_B_Stat 3;
BA_ "GenSigSendType" SG_ 96 SrcTypeActvZone2_D_St 3;
BA_ "GenSigSendType" SG_ 96 CurntMixPreset_No_Actl 3;
BA_ "GenSigSendType" SG_ 96 SpkrAudioRoute_D_Rq 3;
BA_ "GenSigSendType" SG_ 96 VehAudioMde_D_Stat 3;
BA_ "GenSigSendType" SG_ 97 SrcTypeZone3_D_Stat 3;
BA_ "GenSigSendType" SG_ 97 SrcTypeActvZone3_D_St 3;
BA_ "GenSigSendType" SG_ 97 MixblPrmptZone3_B_Stat 3;
BA_ "GenSigSendType" SG_ 97 SrcTypeZone5_D_Stat 3;
BA_ "GenSigSendType" SG_ 97 SrcTypeActvZone5_D_St 3;
BA_ "GenSigSendType" SG_ 97 MixblPrmptZone5_B_Stat 3;
BA_ "GenSigSendType" SG_ 97 MixblChnlZone3_D_Stat 3;
BA_ "GenSigSendType" SG_ 97 MixblChnlZone5_D_Stat 3;
BA_ "GenSigSendType" SG_ 97 SrcTypeChnlZone3_D_St 3;
BA_ "GenSigSendType" SG_ 97 SrcTypeChnlZone5_D_St 3;
BA_ "GenSigSendType" SG_ 98 SrcTypeZone4_D_Stat 3;
BA_ "GenSigSendType" SG_ 98 SrcTypeActvZone4_D_St 3;
BA_ "GenSigSendType" SG_ 98 MixblPrmptZone4_B_Stat 3;
BA_ "GenSigSendType" SG_ 98 SrcTypeZone6_D_Stat 3;
BA_ "GenSigSendType" SG_ 98 SrcTypeActvZone6_D_St 3;
BA_ "GenSigSendType" SG_ 98 MixblPrmptZone6_B_Stat 3;
BA_ "GenSigSendType" SG_ 98 MixblChnlZone4_D_Stat 3;
BA_ "GenSigSendType" SG_ 98 MixblChnlZone6_D_Stat 3;
BA_ "GenSigSendType" SG_ 98 SrcTypeChnlZone6_D_St 3;
BA_ "GenSigSendType" SG_ 98 SrcTypeChnlZone4_D_St 3;
BA_ "GenSigSendType" SG_ 99 OffstVolUpdtZone2_B_St 3;
BA_ "GenSigSendType" SG_ 99 OffstVolZone2_No_Actl 3;
BA_ "GenSigSendType" SG_ 99 OffstVolUpdtZone1_B_St 3;
BA_ "GenSigSendType" SG_ 99 OffstVolZone1_No_Actl 3;
BA_ "GenSigSendType" SG_ 99 OffstVolUpdtZone4_B_St 3;
BA_ "GenSigSendType" SG_ 99 OffstVolZone4_No_Actl 3;
BA_ "GenSigSendType" SG_ 99 OffstVolUpdtZone3_B_St 3;
BA_ "GenSigSendType" SG_ 99 OffstVolZone3_No_Actl 3;
BA_ "GenSigSendType" SG_ 99 OffstVolUpdtZone6_B_St 3;
BA_ "GenSigSendType" SG_ 99 OffstVolZone6_No_Actl 3;
BA_ "GenSigSendType" SG_ 99 OffstVolUpdtZone5_B_St 3;
BA_ "GenSigSendType" SG_ 99 OffstVolZone5_No_Actl 3;
BA_ "GenSigSendType" SG_ 99 MedVolUpdt_B_Stat 3;
BA_ "GenSigSendType" SG_ 99 CabnMedVolLvl_D_Stat 3;
BA_ "GenSigSendType" SG_ 99 PhonVolUpdt_B_Stat 3;
BA_ "GenSigSendType" SG_ 99 CabnPhonVolLvl_D_Stat 3;
BA_ "GenSigSendType" SG_ 99 PrmptVolUpdt_B_Stat 3;
BA_ "GenSigSendType" SG_ 99 CabnPrmptVolLvl_D_Stat 3;
BA_ "GenSigSendType" SG_ 99 RaVolUpdt_B_Stat 3;
BA_ "GenSigSendType" SG_ 99 CabnRaVolLvl_D_Stat 3;
BA_ "GenSigSendType" SG_ 99 CallRngVolUpdt_B_Stat 3;
BA_ "GenSigSendType" SG_ 99 CabnCallRngVolLvl_D_St 3;
BA_ "GenSigSendType" SG_ 100 OvrhdLamp_B_Rq 3;
BA_ "GenSigSendType" SG_ 100 DrDefeatMde_B_Rq 3;
BA_ "GenSigSendType" SG_ 100 MedVolUpdtZone1_B_Stat 3;
BA_ "GenSigSendType" SG_ 100 MedVolLvlZone1_D_Stat 3;
BA_ "GenSigSendType" SG_ 100 OvrhdLampFmid_B_Rq 3;
BA_ "GenSigSendType" SG_ 100 OvrhdLampFl_B_Rq 3;
BA_ "GenSigSendType" SG_ 100 MedVolUpdtZone2_B_Stat 3;
BA_ "GenSigSendType" SG_ 100 MedVolLvlZone2_D_Stat 3;
BA_ "GenSigSendType" SG_ 100 OvrhdLampR2Left_B_Rq 3;
BA_ "GenSigSendType" SG_ 100 OvrhdLampFr_B_Rq 3;
BA_ "GenSigSendType" SG_ 100 MedVolUpdtZone3_B_Stat 3;
BA_ "GenSigSendType" SG_ 100 MedVolLvlZone3_D_Stat 3;
BA_ "GenSigSendType" SG_ 100 OvrhdLampR2Right_B_Rq 3;
BA_ "GenSigSendType" SG_ 100 OvrhdLampR2Mid_B_Rq 3;
BA_ "GenSigSendType" SG_ 100 MedVolUpdtZone4_B_Stat 3;
BA_ "GenSigSendType" SG_ 100 MedVolLvlZone4_D_Stat 3;
BA_ "GenSigSendType" SG_ 100 OvrhdLampR3Mid_B_Rq 3;
BA_ "GenSigSendType" SG_ 100 OvrhdLampR3Left_B_Rq 3;
BA_ "GenSigSendType" SG_ 100 MedVolUpdtZone5_B_Stat 3;
BA_ "GenSigSendType" SG_ 100 MedVolLvlZone5_D_Stat 3;
BA_ "GenSigSendType" SG_ 100 OvrhdLampR3Right_B_Rq 3;
BA_ "GenSigSendType" SG_ 100 MedVolUpdtZone6_B_Stat 3;
BA_ "GenSigSendType" SG_ 100 MedVolLvlZone6_D_Stat 3;
BA_ "GenSigSendType" SG_ 100 PersStorePsngr_D_Rq 3;
BA_ "GenSigSendType" SG_ 100 PersRecallPsngr_D_Rq 3;
BA_ "GenSigSendType" SG_ 100 StwblStewMde_D_RqMnu 3;
BA_ "ECGUsedRxSignal" SG_ 100 StwblStewMde_D_RqMnu 1;
BA_ "GenSigSendType" SG_ 101 PrmptVolUpdtZone1_B_St 3;
BA_ "GenSigSendType" SG_ 101 PrmptVolLvlZone1_D_St 3;
BA_ "GenSigSendType" SG_ 101 PrmptVolUpdtZone2_B_St 3;
BA_ "GenSigSendType" SG_ 101 PrmptVolLvlZone2_D_St 3;
BA_ "GenSigSendType" SG_ 101 PrmptVolUpdtZone3_B_St 3;
BA_ "GenSigSendType" SG_ 101 PrmptVolLvlZone3_D_St 3;
BA_ "GenSigSendType" SG_ 101 PrmptVolUpdtZone4_B_St 3;
BA_ "GenSigSendType" SG_ 101 PrmptVolLvlZone4_D_St 3;
BA_ "GenSigSendType" SG_ 101 PrmptVolUpdtZone5_B_St 3;
BA_ "GenSigSendType" SG_ 101 PrmptVolLvlZone5_D_St 3;
BA_ "GenSigSendType" SG_ 101 PrmptVolUpdtZone6_B_St 3;
BA_ "GenSigSendType" SG_ 101 PrmptVolLvlZone6_D_St 3;
BA_ "GenSigSendType" SG_ 102 CaptAnouncmnt_D_Rq 3;
BA_ "GenSigSendType" SG_ 102 PhonRaVolUpdtZon1_B_St 3;
BA_ "GenSigSendType" SG_ 102 PhonRaVolLvlZone1_D_St 3;
BA_ "GenSigSendType" SG_ 102 PhonCallZone2_D_Stat 3;
BA_ "GenSigSendType" SG_ 102 PhonRaVolUpdtZon2_B_St 3;
BA_ "GenSigSendType" SG_ 102 PhonRaVolLvlZone2_D_St 3;
BA_ "GenSigSendType" SG_ 102 PhonCallZone3_D_Stat 3;
BA_ "GenSigSendType" SG_ 102 PhonRaVolUpdtZon3_B_St 3;
BA_ "GenSigSendType" SG_ 102 PhonRaVolLvlZone3_D_St 3;
BA_ "GenSigSendType" SG_ 102 PhonCallZone4_D_Stat 3;
BA_ "GenSigSendType" SG_ 102 PhonRaVolUpdtZon4_B_St 3;
BA_ "GenSigSendType" SG_ 102 PhonRaVolLvlZone4_D_St 3;
BA_ "GenSigSendType" SG_ 102 PhonCallZone5_D_Stat 3;
BA_ "GenSigSendType" SG_ 102 PhonRaVolUpdtZon5_B_St 3;
BA_ "GenSigSendType" SG_ 102 PhonRaVolLvlZone5_D_St 3;
BA_ "GenSigSendType" SG_ 102 PhonCallZone6_D_Stat 3;
BA_ "GenSigSendType" SG_ 102 PhonRaVolUpdtZon6_B_St 3;
BA_ "GenSigSendType" SG_ 102 PhonRaVolLvlZone6_D_St 3;
BA_ "GenSigSendType" SG_ 102 ThemSel_D_Stat 3;
BA_ "GenSigSendType" SG_ 102 InCarComm_B_Rq 3;
BA_ "GenSigSendType" SG_ 102 TvfSndShrt_D_Stat 3;
BA_ "GenSigStartValue" SG_ 103 AuxAmpfy_D_Stat 1;
BA_ "GenSigSendType" SG_ 103 AuxAmpfy_D_Stat 3;
BA_ "GenSigSendType" SG_ 103 RaSrcType_D_Stat 3;
BA_ "GenSigSendType" SG_ 103 VehAudioMdeCtl_D_Stat 3;
BA_ "GenSigSendType" SG_ 103 ActvNseMute_D_Stat2 3;
BA_ "GenSigStartValue" SG_ 103 AudioCtlChnl1_D_Stat 1;
BA_ "GenSigSendType" SG_ 103 AudioCtlChnl1_D_Stat 3;
BA_ "GenSigSendType" SG_ 103 RaActvType_D_Stat 3;
BA_ "GenSigStartValue" SG_ 103 AudioCtlChnl2_D_Stat 1;
BA_ "GenSigSendType" SG_ 103 AudioCtlChnl2_D_Stat 3;
BA_ "GenSigSendType" SG_ 103 PresetTunCnfm_No_Actl 3;
BA_ "GenSigStartValue" SG_ 103 AudioCtlChnl3_D_Stat 1;
BA_ "GenSigSendType" SG_ 103 AudioCtlChnl3_D_Stat 3;
BA_ "GenSigSendType" SG_ 103 CabnMedVolCtl_D_Stat 3;
BA_ "GenSigStartValue" SG_ 103 AudioCtlChnl4_D_Stat 1;
BA_ "GenSigSendType" SG_ 103 AudioCtlChnl4_D_Stat 3;
BA_ "GenSigSendType" SG_ 103 CabnRaVolCtl_D_Stat 3;
BA_ "GenSigStartValue" SG_ 103 AudioCtlChnl5_D_Stat 1;
BA_ "GenSigSendType" SG_ 103 AudioCtlChnl5_D_Stat 3;
BA_ "GenSigSendType" SG_ 103 SpkrCnnctRear_D_Stat 3;
BA_ "GenSigSendType" SG_ 103 SpkrCnnctFront_D_Stat 3;
BA_ "GenSigSendType" SG_ 103 SpkrSel_B_Res 3;
BA_ "GenSigStartValue" SG_ 103 AuxAmpfyChnl4_D_Stat 1;
BA_ "GenSigSendType" SG_ 103 AuxAmpfyChnl4_D_Stat 3;
BA_ "GenSigStartValue" SG_ 103 AuxAmpfyChnl3_D_Stat 1;
BA_ "GenSigSendType" SG_ 103 AuxAmpfyChnl3_D_Stat 3;
BA_ "GenSigStartValue" SG_ 103 AuxAmpfyChnl2_D_Stat 1;
BA_ "GenSigSendType" SG_ 103 AuxAmpfyChnl2_D_Stat 3;
BA_ "GenSigStartValue" SG_ 103 AuxAmpfyChnl1_D_Stat 1;
BA_ "GenSigSendType" SG_ 103 AuxAmpfyChnl1_D_Stat 3;
BA_ "GenSigSendType" SG_ 103 SetCrntStation_D_Res 3;
BA_ "GenSigStartValue" SG_ 103 AudioCtlChnl8_D_Stat 1;
BA_ "GenSigSendType" SG_ 103 AudioCtlChnl8_D_Stat 3;
BA_ "GenSigStartValue" SG_ 103 AudioCtlChnl7_D_Stat 1;
BA_ "GenSigSendType" SG_ 103 AudioCtlChnl7_D_Stat 3;
BA_ "GenSigStartValue" SG_ 103 AudioCtlChnl6_D_Stat 1;
BA_ "GenSigSendType" SG_ 103 AudioCtlChnl6_D_Stat 3;
BA_ "GenSigSendType" SG_ 104 OffstVolCtlZon1_No_Act 3;
BA_ "GenSigSendType" SG_ 104 MedVolCtlZone1_D_Stat 3;
BA_ "GenSigSendType" SG_ 104 OffstVolCtlZon2_No_Act 3;
BA_ "GenSigSendType" SG_ 104 MedVolCtlZone2_D_Stat 3;
BA_ "GenSigSendType" SG_ 104 OffstVolCtlZon3_No_Act 3;
BA_ "GenSigSendType" SG_ 104 MedVolCtlZone3_D_Stat 3;
BA_ "GenSigSendType" SG_ 104 OffstVolCtlZon4_No_Act 3;
BA_ "GenSigSendType" SG_ 104 MedVolCtlZone4_D_Stat 3;
BA_ "GenSigSendType" SG_ 104 OffstVolCtlZon5_No_Act 3;
BA_ "GenSigSendType" SG_ 104 MedVolCtlZone5_D_Stat 3;
BA_ "GenSigSendType" SG_ 104 OffstVolCtlZon6_No_Act 3;
BA_ "GenSigSendType" SG_ 104 MedVolCtlZone6_D_Stat 3;
BA_ "GenSigSendType" SG_ 105 PhonCallZone6_D_Rq 3;
BA_ "GenSigSendType" SG_ 105 PhonRaVolCtlZone1_D_St 3;
BA_ "GenSigSendType" SG_ 105 PhonCallZone5_D_Rq 3;
BA_ "GenSigSendType" SG_ 105 PhonRaVolCtlZone2_D_St 3;
BA_ "GenSigSendType" SG_ 105 PhonCallZone4_D_Rq 3;
BA_ "GenSigSendType" SG_ 105 PhonRaVolCtlZone3_D_St 3;
BA_ "GenSigSendType" SG_ 105 InCarComm_D_Stat 3;
BA_ "GenSigSendType" SG_ 105 PhonRaVolCtlZone4_D_St 3;
BA_ "GenSigSendType" SG_ 105 CaptAnouncmnt_D_Stat 3;
BA_ "GenSigSendType" SG_ 105 PhonRaVolCtlZone5_D_St 3;
BA_ "GenSigSendType" SG_ 105 PhonCallZone2_D_Rq 3;
BA_ "GenSigSendType" SG_ 105 PhonRaVolCtlZone6_D_St 3;
BA_ "GenSigSendType" SG_ 105 PhonCallZone3_D_Rq 3;
BA_ "GenSigSendType" SG_ 106 OffstVolCtlZon1_No_Act2 3;
BA_ "GenSigSendType" SG_ 106 MedVolCtlZone1_D_Stat2 3;
BA_ "GenSigSendType" SG_ 106 OffstVolCtlZon2_No_Act2 3;
BA_ "GenSigSendType" SG_ 106 MedVolCtlZone2_D_Stat2 3;
BA_ "GenSigSendType" SG_ 106 OffstVolCtlZon3_No_Act2 3;
BA_ "GenSigSendType" SG_ 106 MedVolCtlZone3_D_Stat2 3;
BA_ "GenSigSendType" SG_ 106 OffstVolCtlZon4_No_Act2 3;
BA_ "GenSigSendType" SG_ 106 MedVolCtlZone4_D_Stat2 3;
BA_ "GenSigSendType" SG_ 106 OffstVolCtlZon5_No_Act2 3;
BA_ "GenSigSendType" SG_ 106 MedVolCtlZone5_D_Stat2 3;
BA_ "GenSigSendType" SG_ 106 OffstVolCtlZon6_No_Act2 3;
BA_ "GenSigSendType" SG_ 106 MedVolCtlZone6_D_Stat2 3;
BA_ "GenSigSendType" SG_ 106 VehAudioMdeCtl_D_Stat2 3;
BA_ "GenSigSendType" SG_ 106 CabnMedVolCtl_D_Stat2 3;
BA_ "GenSigSendType" SG_ 106 InfotainmentAudio_St2 3;
BA_ "GenSigSendType" SG_ 106 CabnRaVolCtl_D_Stat2 3;
BA_ "GenSigSendType" SG_ 107 PhonRaVolCtlZon1_D_St2 3;
BA_ "GenSigSendType" SG_ 107 PhonRaVolCtlZon2_D_St2 3;
BA_ "GenSigSendType" SG_ 107 PhonRaVolCtlZon3_D_St2 3;
BA_ "GenSigSendType" SG_ 107 PhonRaVolCtlZon4_D_St2 3;
BA_ "GenSigSendType" SG_ 107 PhonRaVolCtlZon5_D_St2 3;
BA_ "GenSigSendType" SG_ 107 PhonRaVolCtlZon6_D_St2 3;
BA_ "GenSigSendType" SG_ 109 SetCrntStationFq_No_Rq 3;
BA_ "GenSigSendType" SG_ 109 SetCrntStationOpr_D_Rq 3;
BA_ "GenSigSendType" SG_ 109 SetCrntStationMde_D_Rq 3;
BA_ "GenSigSendType" SG_ 109 SetCrntStnExtndCc_No_Rq 3;
BA_ "GenSigSendType" SG_ 109 SetCrntStnSrvcId_No_Rq 3;
BA_ "GenSigSendType" SG_ 109 SetCrntStnPiCode_No_Rq 3;
BA_ "GenSigSendType" SG_ 109 SetCrntStnMcChnl_D_Rq 3;
BA_ "GenSigStartValue" SG_ 110 AudioAmpfyChnl4_D_Stat 1;
BA_ "GenSigSendType" SG_ 110 AudioAmpfyChnl4_D_Stat 3;
BA_ "GenSigStartValue" SG_ 110 AudioAmpfyChnl3_D_Stat 1;
BA_ "GenSigSendType" SG_ 110 AudioAmpfyChnl3_D_Stat 3;
BA_ "GenSigStartValue" SG_ 110 AudioAmpfyChnl2_D_Stat 1;
BA_ "GenSigSendType" SG_ 110 AudioAmpfyChnl2_D_Stat 3;
BA_ "GenSigStartValue" SG_ 110 AudioAmpfyChnl1_D_Stat 1;
BA_ "GenSigSendType" SG_ 110 AudioAmpfyChnl1_D_Stat 3;
BA_ "GenSigStartValue" SG_ 110 AudioAmpfyChnl8_D_Stat 1;
BA_ "GenSigSendType" SG_ 110 AudioAmpfyChnl8_D_Stat 3;
BA_ "GenSigStartValue" SG_ 110 AudioAmpfyChnl7_D_Stat 1;
BA_ "GenSigSendType" SG_ 110 AudioAmpfyChnl7_D_Stat 3;
BA_ "GenSigStartValue" SG_ 110 AudioAmpfyChnl6_D_Stat 1;
BA_ "GenSigSendType" SG_ 110 AudioAmpfyChnl6_D_Stat 3;
BA_ "GenSigStartValue" SG_ 110 AudioAmpfyChnl5_D_Stat 1;
BA_ "GenSigSendType" SG_ 110 AudioAmpfyChnl5_D_Stat 3;
BA_ "GenSigStartValue" SG_ 110 AudioAmpfyChnl12_D_St 1;
BA_ "GenSigSendType" SG_ 110 AudioAmpfyChnl12_D_St 3;
BA_ "GenSigStartValue" SG_ 110 AudioAmpfyChnl11_D_St 1;
BA_ "GenSigSendType" SG_ 110 AudioAmpfyChnl11_D_St 3;
BA_ "GenSigStartValue" SG_ 110 AudioAmpfyChnl10_D_St 1;
BA_ "GenSigSendType" SG_ 110 AudioAmpfyChnl10_D_St 3;
BA_ "GenSigStartValue" SG_ 110 AudioAmpfyChnl9_D_Stat 1;
BA_ "GenSigSendType" SG_ 110 AudioAmpfyChnl9_D_Stat 3;
BA_ "GenSigStartValue" SG_ 110 AudioAmpfyChnl16_D_St 1;
BA_ "GenSigSendType" SG_ 110 AudioAmpfyChnl16_D_St 3;
BA_ "GenSigStartValue" SG_ 110 AudioAmpfyChnl15_D_St 1;
BA_ "GenSigSendType" SG_ 110 AudioAmpfyChnl15_D_St 3;
BA_ "GenSigStartValue" SG_ 110 AudioAmpfyChnl14_D_St 1;
BA_ "GenSigSendType" SG_ 110 AudioAmpfyChnl14_D_St 3;
BA_ "GenSigStartValue" SG_ 110 AudioAmpfyChnl13_D_St 1;
BA_ "GenSigSendType" SG_ 110 AudioAmpfyChnl13_D_St 3;
BA_ "GenSigStartValue" SG_ 110 AudioAmpfyChnl20_D_St 1;
BA_ "GenSigSendType" SG_ 110 AudioAmpfyChnl20_D_St 3;
BA_ "GenSigStartValue" SG_ 110 AudioAmpfyChnl19_D_St 1;
BA_ "GenSigSendType" SG_ 110 AudioAmpfyChnl19_D_St 3;
BA_ "GenSigStartValue" SG_ 110 AudioAmpfyChnl18_D_St 1;
BA_ "GenSigSendType" SG_ 110 AudioAmpfyChnl18_D_St 3;
BA_ "GenSigStartValue" SG_ 110 AudioAmpfyChnl17_D_St 1;
BA_ "GenSigSendType" SG_ 110 AudioAmpfyChnl17_D_St 3;
BA_ "GenSigStartValue" SG_ 110 AudioAmpfyChnl24_D_St 1;
BA_ "GenSigSendType" SG_ 110 AudioAmpfyChnl24_D_St 3;
BA_ "GenSigStartValue" SG_ 110 AudioAmpfyChnl23_D_St 1;
BA_ "GenSigSendType" SG_ 110 AudioAmpfyChnl23_D_St 3;
BA_ "GenSigStartValue" SG_ 110 AudioAmpfyChnl22_D_St 1;
BA_ "GenSigSendType" SG_ 110 AudioAmpfyChnl22_D_St 3;
BA_ "GenSigStartValue" SG_ 110 AudioAmpfyChnl21_D_St 1;
BA_ "GenSigSendType" SG_ 110 AudioAmpfyChnl21_D_St 3;
BA_ "GenSigStartValue" SG_ 117 BrkLamp_UNUSED_1bit_1 1;
BA_ "GenSigInactiveValue" SG_ 117 BrkLamp_UNUSED_1bit_1 1;
BA_ "GenSigStartValue" SG_ 117 BrkLamp_UNUSED_8bit_1 255;
BA_ "GenSigInactiveValue" SG_ 117 BrkLamp_UNUSED_8bit_1 255;
BA_ "GenSigStartValue" SG_ 117 BrkLamp_UNUSED_8bit_2 255;
BA_ "GenSigInactiveValue" SG_ 117 BrkLamp_UNUSED_8bit_2 255;
BA_ "GenSigStartValue" SG_ 117 BrkLamp_UNUSED_8bit_3 255;
BA_ "GenSigInactiveValue" SG_ 117 BrkLamp_UNUSED_8bit_3 255;
BA_ "GenSigStartValue" SG_ 117 BrkLamp_UNUSED_8bit_4 255;
BA_ "GenSigInactiveValue" SG_ 117 BrkLamp_UNUSED_8bit_4 255;
BA_ "GenSigStartValue" SG_ 117 BrkLamp_UNUSED_8bit_5 255;
BA_ "GenSigInactiveValue" SG_ 117 BrkLamp_UNUSED_8bit_5 255;
BA_ "GenSigStartValue" SG_ 124 VehYawComp_W_Actl 4094;
BA_ "GenSigStartValue" SG_ 124 VehTrvlDir_D_Stat 6;
BA_ "GenSigStartValue" SG_ 124 VehLatComp_A_Actl 1022;
BA_ "GenSigStartValue" SG_ 124 VehLongComp_A_Actl 1022;
BA_ "GenSigStartValue" SG_ 125 VehVertComp_A_Actl 1022;
BA_ "GenSigStartValue" SG_ 125 VehRolComp_W_Actl 4094;
BA_ "GenSigStartValue" SG_ 126 StePinRelInit_An_Sns 65535;
BA_ "GenSigStartValue" SG_ 126 StePinCompAnEst_D_Qf 1;
BA_ "WakeupSignal" SG_ 129 SteWhlSwtchDown_B_Stat 1;
BA_ "WakeupSignal" SG_ 129 SteWhlSwtchLeft_B_Stat 1;
BA_ "WakeupSignal" SG_ 129 SteWhlSwtchRght_B_Stat 1;
BA_ "WakeupSignal" SG_ 129 SteWhlSwtchUp_B_Stat 1;
BA_ "WakeupSignal" SG_ 129 SteWhlSwtchOk_B_Stat 1;
BA_ "WakeupSignal" SG_ 129 SteWhlSwtchSet_B_Stat 1;
BA_ "WakeupSignal" SG_ 129 SteWhlSwtchPhon_B_Stat 1;
BA_ "WakeupSignal" SG_ 129 SteWhlSwtchNav_B_Stat 1;
BA_ "WakeupSignal" SG_ 129 SteWhlSwtchMed_B_Stat 1;
BA_ "WakeupSignal" SG_ 129 SteWhlSwtchIod_B_Stat 1;
BA_ "WakeupSignal" SG_ 129 SteWhlSwtchHud_B_Stat 1;
BA_ "WakeupSignal" SG_ 129 SteWhlSwtchBack_B_Stat 1;
BA_ "WakeupSignal" SG_ 129 SteWhlSwtchMenu_B_Stat 1;
BA_ "WakeupSignal" SG_ 129 SteWhlSwtchView_B_Stat 1;
BA_ "WakeupSignal" SG_ 129 StewSwtchScnd_D_Stat 1;
BA_ "WakeupSignal" SG_ 129 StewSwtchPrim_D_Stat 1;
BA_ "WakeupSignal" SG_ 129 AirbagDrvRqDac_No_Cnt 1;
BA_ "WakeupSignal" SG_ 129 AirbagDrvRqDac_No_Cs 1;
BA_ "GenSigStartValue" SG_ 130 SteeringColumnTorque 254;
BA_ "GenSigStartValue" SG_ 130 SteMdule_I_Est 4095;
BA_ "GenSigStartValue" SG_ 130 SteMdule_U_Meas 255;
BA_ "GenSigStartValue" SG_ 130 ElPwAsstSte_B_Stat 1;
BA_ "GenSigStartValue" SG_ 130 Veh_V_RqMxTrlrAid 255;
BA_ "GenSigStartValue" SG_ 131 WiprFront_D_Stat 15;
BA_ "WakeupSignal" SG_ 131 TurnLghtSwtch_D_Stat 1;
BA_ "WakeupSignal" SG_ 131 ElPwAsstSte_B_RqDactv 1;
BA_ "GenSigStartValue" SG_ 131 LghtAmb_D_Sns 7;
BA_ "WakeupSignal" SG_ 131 HeadLghtHiOn_B_StatAhb 1;
BA_ "WakeupSignal" SG_ 131 HeadLghtHiCtrl_D_RqAhb 1;
BA_ "GenSigStartValue" SG_ 131 WiprFrontSwtch_D_Stat 9;
BA_ "GenSigStartValue" SG_ 133 WrlssAcsyChrg_Pc_Actl2 126;
BA_ "GenSigSendType" SG_ 133 WrlssAcsyChrg_Pc_Actl2 3;
BA_ "GenSigStartValue" SG_ 133 WrlssAcsyChrgr_D_Stat2 1;
BA_ "GenSigSendType" SG_ 133 WrlssAcsyChrgr_D_Stat2 3;
BA_ "WakeupSignal" SG_ 134 DispGlblClkYr_No_Rq 1;
BA_ "WakeupSignal" SG_ 134 DispGlblClkDay_No_Rq 1;
BA_ "WakeupSignal" SG_ 134 DispGlblClkMnte_No_Rq 1;
BA_ "WakeupSignal" SG_ 134 DispGlblClkScnd_No_Rq 1;
BA_ "WakeupSignal" SG_ 134 DispGlblClkHr_No_Rq 1;
BA_ "WakeupSignal" SG_ 134 DispGlblClkAdj_B_Rq 1;
BA_ "GenSigSendType" SG_ 134 DispGlblClkAdj_B_Rq 3;
BA_ "WakeupSignal" SG_ 135 McGlblClkYr_No_Rq 1;
BA_ "WakeupSignal" SG_ 135 McGlblClkDay_No_Rq 1;
BA_ "WakeupSignal" SG_ 135 McGlblClkMnte_No_Rq 1;
BA_ "WakeupSignal" SG_ 135 McGlblClkScnd_No_Rq 1;
BA_ "WakeupSignal" SG_ 135 McGlblClkHr_No_Rq 1;
BA_ "WakeupSignal" SG_ 135 McGlblClkAdj_B_Rq 1;
BA_ "GenSigSendType" SG_ 135 McGlblClkAdj_B_Rq 3;
BA_ "GenSigSendType" SG_ 140 StewPosAdjTlt_D_Rq 3;
BA_ "GenSigSendType" SG_ 140 StewPosAdjTel_D_Rq 3;
BA_ "GenSigSendType" SG_ 140 TjaButtnOnOffPress4 3;
BA_ "GenSigSendType" SG_ 140 AccButtnGapTogglePress3 3;
BA_ "GenSigSendType" SG_ 140 AccButtnGapIncPress4 3;
BA_ "GenSigSendType" SG_ 140 AccButtnGapDecPress4 3;
BA_ "GenSigSendType" SG_ 140 CcAslButtnCnclPress3 3;
BA_ "GenSigSendType" SG_ 140 AslButtnOnOffPress3 3;
BA_ "GenSigSendType" SG_ 140 AslButtnOnOffCnclPress2 3;
BA_ "GenSigSendType" SG_ 140 ExtMirrorAdj_D_Rq 3;
BA_ "GenSigSendType" SG_ 140 MirrorSelFold_D_Rq 3;
BA_ "GenSigSendType" SG_ 140 CcAslButtnOnOffCncl3 3;
BA_ "GenSigSendType" SG_ 140 CcAslButtnOffCnclPress2 3;
BA_ "GenSigSendType" SG_ 140 CcAslButtnIndxIncPress2 3;
BA_ "GenSigSendType" SG_ 140 CcAslButtnIndxDecPress2 3;
BA_ "GenSigSendType" SG_ 140 CcAslButtnDeny_B_Actl3 3;
BA_ "GenSigSendType" SG_ 140 CcAslButtnCnclResPress2 3;
BA_ "GenSigSendType" SG_ 140 SteWhlSwtchMde_D_Stat 3;
BA_ "GenSigSendType" SG_ 140 CcButtnOffPress3 3;
BA_ "GenSigSendType" SG_ 140 CcAsllButtnResPress3 3;
BA_ "GenSigSendType" SG_ 140 CcAslButtnSetPress3 3;
BA_ "GenSigSendType" SG_ 140 CcAslButtnSetIncPress3 3;
BA_ "GenSigSendType" SG_ 140 CcAslButtnSetDecPress3 3;
BA_ "GenSigSendType" SG_ 140 CcAslButtnResIncPress3 3;
BA_ "GenSigSendType" SG_ 140 CcAslButtnResDecPress3 3;
BA_ "GenSigSendType" SG_ 140 CcAslButtnOnPress3 3;
BA_ "GenSigSendType" SG_ 140 PdlAdj_D_Rq 3;
BA_ "GenSigStartValue" SG_ 140 StewSwtchIlumnat_B_Rq 1;
BA_ "GenSigSendType" SG_ 140 StewSwtchIlumnat_B_Rq 3;
BA_ "GenSigSendType" SG_ 140 DcacPwResetBttn_D_Stat 3;
BA_ "GenSigSendType" SG_ 140 CcButtnOnPress3 3;
BA_ "GenSigSendType" SG_ 140 CcButtnOnOffPress3 3;
BA_ "GenSigSendType" SG_ 140 CcButtnOnOffCnclPress3 3;
BA_ "GenSigSendType" SG_ 140 BrkMaintMde_D_Rq 3;
BA_ "GenSigStartValue" SG_ 141 WrlssAcsyChrg_Pc_Actl3 126;
BA_ "GenSigSendType" SG_ 141 WrlssAcsyChrg_Pc_Actl3 3;
BA_ "GenSigStartValue" SG_ 141 WrlssAcsyChrgr_D_Stat3 1;
BA_ "GenSigSendType" SG_ 141 WrlssAcsyChrgr_D_Stat3 3;
BA_ "GenSigStartValue" SG_ 142 MobcPinAbsltPrim_An_Rq 16000;
BA_ "GenSigSendType" SG_ 144 SetTimeFormat 3;
BA_ "GenSigSendType" SG_ 144 DateAdjustRequest 3;
BA_ "GenSigSendType" SG_ 144 TimeAdjustRequest 3;
BA_ "GenSigSendType" SG_ 145 MFD_Second 3;
BA_ "GenSigStartValue" SG_ 146 VehLat2_A_Actl 8190;
BA_ "GenSigStartValue" SG_ 146 VehLatAActl_D_Qf 1;
BA_ "GenSigStartValue" SG_ 146 VehLong2_A_Actl 8190;
BA_ "GenSigStartValue" SG_ 146 VehLongAActl_D_Qf 1;
BA_ "GenSigStartValue" SG_ 146 VehVert2_A_Actl 8190;
BA_ "GenSigStartValue" SG_ 146 VehVertAActl_D_Qf 1;
BA_ "GenSigStartValue" SG_ 148 VehRol_W_Actl 65534;
BA_ "GenSigStartValue" SG_ 148 VehYaw_W_Actl 65534;
BA_ "GenSigStartValue" SG_ 148 VehYawWActl_D_Qf 1;
BA_ "GenSigStartValue" SG_ 148 VehRolWActl_D_Qf 1;
BA_ "GenSigSendType" SG_ 257 MFD_GetTagInfo 3;
BA_ "GenSigSendType" SG_ 257 MFD_SetHDModeRq 3;
BA_ "GenSigSendType" SG_ 257 MFD_SetTagMode 3;
BA_ "GenSigSendType" SG_ 257 MFD_SetRBDSMode 3;
BA_ "GenSigSendType" SG_ 258 LghtAmbDynmc_D_Rq 3;
BA_ "GenSigSendType" SG_ 259 SDARS_CurrCATlistInd_Rq 3;
BA_ "GenSigSendType" SG_ 259 SDARS_ChipControl_Rq 3;
BA_ "GenSigSendType" SG_ 259 SDARS_AlertStatus_Rq 3;
BA_ "GenSigSendType" SG_ 260 SDARS_SelectCategory_Rq 3;
BA_ "GenSigSendType" SG_ 260 SDARS_SRReplay_Rq 3;
BA_ "GenSigSendType" SG_ 260 MFD_SDARS_SetOpMode_Rq 3;
BA_ "GenSigStartValue" SG_ 260 MFD_SDARS_DirectTune_Rq 255;
BA_ "GenSigSendType" SG_ 260 MFD_SDARS_DirectTune_Rq 3;
BA_ "GenSigSendType" SG_ 260 SDARS_FactoryReset_Rq 3;
BA_ "GenSigSendType" SG_ 260 SDARS_GetESN_Rq 3;
BA_ "GenSigSendType" SG_ 260 SDARS_InfoRefChanNum_Rq 3;
VAL_ 74 eCallNotification 0 "Not_Supported" 1 "Normal" 2 "Active" 3 "Not_Used" ;
VAL_ 74 VedsDrvBag_D_Ltchd 0 "NoEvent" 1 "Deployed" 2 "NotDeployed" 3 "Unused_1" 4 "Unused_2" 5 "Unused_3" 6 "NotSupported" 7 "Fault" ;
VAL_ 74 VedsDrvBelt_D_Ltchd 0 "NoEvent" 1 "Deployed" 2 "NotDeployed" 3 "Unused_1" 4 "Unused_2" 5 "Unused_3" 6 "NotSupported" 7 "Fault" ;
VAL_ 74 VedsDrvCrtnBag_D_Ltchd 0 "NoEvent" 1 "Deployed" 2 "NotDeployed" 3 "Unused_1" 4 "Unused_2" 5 "Unused_3" 6 "NotSupported" 7 "Fault" ;
VAL_ 74 VedsDrvSideBag_D_Ltchd 0 "NoEvent" 1 "Deployed" 2 "NotDeployed" 3 "Unused_1" 4 "Unused_2" 5 "Unused_3" 6 "NotSupported" 7 "Fault" ;
VAL_ 74 VedsEvntRoll_D_Ltchd 0 "NoEvent" 1 "No" 2 "Yes" 3 "Unused_1" 4 "Unused_2" 5 "Unused_3" 6 "NotSupported" 7 "Fault" ;
VAL_ 74 VedsEvntType_D_Ltchd 0 "NoEvent" 1 "Frontal" 2 "Side" 3 "Rear" 4 "Rolllover" 5 "Unused" 6 "NotSupported" 7 "Fault" ;
VAL_ 74 VedsMaxDeltaV_D_Ltchd 0 "NoEvent" 254 "NotSupported" 255 "Fault" ;
VAL_ 74 VedsMultiEvnt_D_Ltchd 0 "NoEvent" 1 "No" 2 "Yes" 3 "Unused_1" 4 "Unused_2" 5 "Unused_3" 6 "NotSupported" 7 "Fault" ;
VAL_ 74 VedsPasBag_D_Ltchd 0 "NoEvent" 1 "Deployed" 2 "NotDeployed" 3 "Unused_1" 4 "Unused_2" 5 "Unused_3" 6 "NotSupported" 7 "Fault" ;
VAL_ 74 VedsPasBelt_D_Ltchd 0 "NoEvent" 1 "Deployed" 2 "NotDeployed" 3 "Unused_1" 4 "Unused_2" 5 "Unused_3" 6 "NotSupported" 7 "Fault" ;
VAL_ 74 VedsPasCrtnBag_D_Ltchd 0 "NoEvent" 1 "Deployed" 2 "NotDeployed" 3 "Unused_1" 4 "Unused_2" 5 "Unused_3" 6 "NotSupported" 7 "Fault" ;
VAL_ 74 VedsPasSideBag_D_Ltchd 0 "NoEvent" 1 "Deployed" 2 "NotDeployed" 3 "Unused_1" 4 "Unused_2" 5 "Unused_3" 6 "NotSupported" 7 "Fault" ;
VAL_ 74 VedsDrvKneeBag_D_Ltchd 0 "NoEvent" 1 "Deployed" 2 "NotDeployed" 3 "Unused_1" 4 "Unused_2" 5 "Unused_3" 6 "NotSupported" 7 "Fault" ;
VAL_ 75 VedsRw1DrvBckl_D_Ltchd 0 "NoEvent" 1 "Belted" 2 "NotBelted" 3 "Unused_1" 4 "Unused_2" 5 "Unused_3" 6 "NotSupported" 7 "Fault" ;
VAL_ 75 VedsRw1PasBckl_D_Ltchd 0 "NoEvent" 1 "Belted" 2 "NotBelted" 3 "Unused_1" 4 "Unused_2" 5 "Unused_3" 6 "NotSupported" 7 "Fault" ;
VAL_ 75 VedsRw1PasChld_D_Ltchd 0 "NoEvent" 1 "ChildDetected" 2 "ChildNotDetected" 3 "Unused_1" 4 "Unused_2" 5 "Unused_3" 6 "NotSupported" 7 "Fault" ;
VAL_ 75 VedsRw2dBckl_D_Ltchd 0 "NoEvent" 1 "Belted" 2 "NotBelted" 3 "Unused_1" 4 "Unused_2" 5 "Unused_3" 6 "NotSupported" 7 "Fault" ;
VAL_ 75 VedsRw2mBckl_D_Ltchd 0 "NoEvent" 1 "Belted" 2 "NotBelted" 3 "Unused_1" 4 "Unused_2" 5 "Unused_3" 6 "NotSupported" 7 "Fault" ;
VAL_ 75 VedsRw2pBckl_D_Ltchd 0 "NoEvent" 1 "Belted" 2 "NotBelted" 3 "Unused_1" 4 "Unused_2" 5 "Unused_3" 6 "NotSupported" 7 "Fault" ;
VAL_ 75 VedsRw3dBckl_D_Ltchd 0 "NoEvent" 1 "Belted" 2 "NotBelted" 3 "Unused_1" 4 "Unused_2" 5 "Unused_3" 6 "NotSupported" 7 "Fault" ;
VAL_ 75 VedsRw3mBckl_D_Ltchd 0 "NoEvent" 1 "Belted" 2 "NotBelted" 3 "Unused_1" 4 "Unused_2" 5 "Unused_3" 6 "NotSupported" 7 "Fault" ;
VAL_ 75 VedsRw2dRib_D_Ltchd 0 "NoEvent" 1 "Deployed" 2 "NotDeployed" 3 "Unused_1" 4 "Unused_2" 5 "Unused_3" 6 "NotSupported" 7 "Fault" ;
VAL_ 75 VedsRw3pBckl_D_Ltchd 0 "NoEvent" 1 "Belted" 2 "NotBelted" 3 "Unused_1" 4 "Unused_2" 5 "Unused_3" 6 "NotSupported" 7 "Fault" ;
VAL_ 75 VedsRw1mBelt_D_Ltchd 0 "NoEvent" 1 "Deployed" 2 "NotDeployed" 3 "Unused_1" 4 "Unused_2" 5 "Unused_3" 6 "NotSupported" 7 "Fault" ;
VAL_ 75 VedsRw2pRib_D_Ltchd 0 "NoEvent" 1 "Deployed" 2 "NotDeployed" 3 "Unused_1" 4 "Unused_2" 5 "Unused_3" 6 "NotSupported" 7 "Fault" ;
VAL_ 75 VedsPasKneeBag_D_Ltchd 0 "NoEvent" 1 "Deployed" 2 "NotDeployed" 3 "Unused_1" 4 "Unused_2" 5 "Unused_3" 6 "NotSupported" 7 "Fault" ;
VAL_ 75 VedsRw1mBckl_D_Ltchd 0 "NoEvent" 1 "Belted" 2 "NotBelted" 3 "Unused_1" 4 "Unused_2" 5 "Unused_3" 6 "NotSupported" 7 "Fault" ;
VAL_ 75 VedsRw3pRib_D_Ltchd 0 "NoEvent" 1 "Deployed" 2 "NotDeployed" 3 "Unused_1" 4 "Unused_2" 5 "Unused_3" 6 "NotSupported" 7 "Fault" ;
VAL_ 75 VedsRw3dRib_D_Ltchd 0 "NoEvent" 1 "Deployed" 2 "NotDeployed" 3 "Unused_1" 4 "Unused_2" 5 "Unused_3" 6 "NotSupported" 7 "Fault" ;
VAL_ 76 RstrnImpactEvntStatus 0 "Normal" 1 "Not_Used_1" 2 "Not_Used_2" 3 "Threshold_1_Exceeded" 4 "Not_Used_3" 5 "Threshold_2_Exceeded" 6 "Not_Used_4" 7 "Invalid" ;
VAL_ 76 PsngrFrntDetct_D_Actl 0 "Faulty" 1 "Occupied" 2 "Empty" 3 "Unknown" ;
VAL_ 76 RILReq 0 "Off" 1 "On" 2 "Plant_Mode" 3 "Not_Used" ;
VAL_ 76 SecondRowBuckleMid 0 "Faulty" 1 "Belted" 2 "Unbelted" 3 "Unknown" ;
VAL_ 76 SecondRowBuckleDriver 0 "Faulty" 1 "Belted" 2 "Unbelted" 3 "Unknown" ;
VAL_ 76 FirstRowBucklePsngr 0 "Faulty" 1 "Belted" 2 "Unbelted" 3 "Unknown" ;
VAL_ 76 FirstRowBuckleDriver 0 "Faulty" 1 "Belted" 2 "Unbelted" 3 "Unknown" ;
VAL_ 76 ThirdRowBucklePsngr 0 "Faulty" 1 "Belted" 2 "Unbelted" 3 "Unknown" ;
VAL_ 76 ThirdRowBuckleMid 0 "Faulty" 1 "Belted" 2 "Unbelted" 3 "Unknown" ;
VAL_ 76 ThirdRowBuckleDriver 0 "Faulty" 1 "Belted" 2 "Unbelted" 3 "Unknown" ;
VAL_ 76 SecondRowBucklePsngr 0 "Faulty" 1 "Belted" 2 "Unbelted" 3 "Unknown" ;
VAL_ 76 PsngrFmidDetct_D_Actl 0 "Fault" 1 "Occupied" 2 "Empty" 3 "Unknown" ;
VAL_ 76 FirstRowBuckleMid 0 "Faulty" 1 "Belted" 2 "Unbelted" 3 "Unknown" ;
VAL_ 76 EDRTriggerEvntSync 0 "Normal" 1 "Threshold_Exceeded" ;
VAL_ 76 PassRstrnInd_Req 0 "AirbagOn_Illum_Off_Illum" 1 "AirbagOn_Illum_OffNotIllum" 2 "AirbagOnNot_Illum_OffIllum" 3 "ABOnNotIllum_OffNotIllum" ;
VAL_ 76 RstrnPsngrOn_D_Stat 0 "NoAction" 1 "NotUsed_1" 2 "NotUsed_2" 3 "NotUsed_3" 4 "NotUsed_4" 5 "Off" 6 "NotUsed_5" 7 "NotUsed_6" 8 "NotUsed_7" 9 "NotUsed_8" 10 "On" 11 "NotUsed_9" 12 "ConfiguredOff" 13 "NotUsed_10" 14 "NotUsed_11" 15 "Faulty" ;
VAL_ 76 PassRstrnIndB_Req 0 "AirbagOn_Illum_Off_Illum" 1 "AirbagOn_Illum_OffNotIllum" 2 "AirbagOnNot_Illum_OffIllum" 3 "ABOnNotIllum_OffNotIllum" ;
VAL_ 76 AirbagDrv_D_Actv 0 "NotAvailable" 1 "Off" 2 "On" 3 "Faulty" ;
VAL_ 90 TrnGearButtn_B_ActlN0 0 "No" 1 "Yes" ;
VAL_ 90 TrnGearButtn_B_ActlM2 0 "No" 1 "Yes" ;
VAL_ 90 TrnGearButtn_B_ActlM1 0 "No" 1 "Yes" ;
VAL_ 90 TrnGearButtn_B_ActlM0 0 "No" 1 "Yes" ;
VAL_ 90 TrnGearButtn_B_ActlD2 0 "No" 1 "Yes" ;
VAL_ 90 TrnGearButtn_B_ActlD1 0 "No" 1 "Yes" ;
VAL_ 90 TrnGearButtn_B_ActlD0 0 "No" 1 "Yes" ;
VAL_ 90 BrkSwtchPos_B_ActlGsm 0 "No" 1 "Yes" ;
VAL_ 90 TrnGearButtn_B_ActlR2 0 "No" 1 "Yes" ;
VAL_ 90 TrnGearButtn_B_ActlR1 0 "No" 1 "Yes" ;
VAL_ 90 TrnGearButtn_B_ActlR0 0 "No" 1 "Yes" ;
VAL_ 90 TrnGearButtn_B_ActlP2 0 "No" 1 "Yes" ;
VAL_ 90 TrnGearButtn_B_ActlP1 0 "No" 1 "Yes" ;
VAL_ 90 TrnGearButtn_B_ActlP0 0 "No" 1 "Yes" ;
VAL_ 90 TrnGearButtn_B_ActlN2 0 "No" 1 "Yes" ;
VAL_ 90 TrnGearButtn_B_ActlN1 0 "No" 1 "Yes" ;
VAL_ 90 TrnGearButtn_U_Actl 255 "Fault" ;
VAL_ 90 TrnValidGearRq_D_Stat 0 "No_Request" 1 "Invalid_Request" 2 "Valid_Degraded_Request" 3 "Valid_Request" ;
VAL_ 90 TrnGear_D_RqDrv 0 "No_Gear" 1 "Park" 2 "Reverse" 3 "NotUsed_1" 4 "Neutral" 5 "NotUsed_2" 6 "NotUsed_3" 7 "NotUsed_4" 8 "Drive" 9 "NotUsed_5" 10 "NotUsed_6" 11 "NotUsed_7" 12 "NotUsed_8" 13 "NotUsed_9" 14 "Not_Used10" 15 "Not_Used11" 16 "Manual" 17 "NotUsed_12" 18 "NotUsed_13" 19 "NotUsed_14" 20 "NotUsed_15" 21 "Return_To_Park" 22 "NotUsed_17" 23 "NotUsed_18" 24 "NotUsed_19" 25 "NotUsed_20" 26 "NotUsed_21" 27 "NotUsed_22" 28 "NotUsed_23" 29 "NotUsed_24" 30 "NotUsed_25" 31 "Fault" ;
VAL_ 90 DrQltyDrv_D_StatGsm 0 "OpenOkay" 1 "ClosedOkay" 2 "OpenDegraded" 3 "ClosedDegraded" 4 "NotUsed1" 5 "NotUsed2" 6 "NoDataExists" 7 "Faulty" ;
VAL_ 90 TrnBtsiOvrrd_B_Stat 0 "Null" 1 "Override" ;
VAL_ 90 TrnRng_D_RqGsm 0 "Park" 1 "Reverse" 2 "Neutral" 3 "Drive" 4 "Sport_DriveSport" 5 "Low" 6 "1" 7 "2" 8 "3" 9 "4" 10 "5" 11 "6" 12 "Undefined_1" 13 "Undefined_2" 14 "UnknownPosition" 15 "Fault" ;
VAL_ 90 TrnGsmNtmState_D_Actl 0 "None" 1 "Car_Wash_Mode" 2 "Neutral_Tow_Mode" 3 "Faulty" ;
VAL_ 90 GsmGearMsgTxt_D_Rq 0 "NoMessage" 1 "Message1" 2 "Message2" 3 "Message3" ;
VAL_ 92 TrnSbwSysHlth_D_Actl 0 "Faulty" 1 "No_Data_Exists" 2 "Degraded" 3 "OK" ;
VAL_ 92 TrnGear_D_RqPt 0 "No_Gear" 1 "Park" 2 "Reverse" 3 "Neutral" 4 "Drive" 5 "Manual" 6 "NotUsed" 7 "Fault" ;
VAL_ 92 TrnNtrlTowCmd_D_Actl 0 "Normal_Mode" 1 "Car_Wash_Mode" 2 "Neutral_Tow_Entry" 3 "NotUsed" ;
VAL_ 92 TrnGearCmd_Pc_ActlPt 1023 "Fault" ;
VAL_ 92 TrnValidGear_D_Cnfm 0 "No_Command" 1 "Internal_Request" 2 "Reject" 3 "Accept" ;
VAL_ 92 TrnGearMsgTxt_D_Rq 0 "NoMessage" 1 "Message_1" 2 "Message_2" 3 "Message_3" 4 "Message_4" 5 "Message_5" 6 "Message_6" 7 "Message_7" 8 "Message_8" 9 "Message_9" 10 "Message_10" 11 "Message_11" 12 "Message_12" 13 "Message_13" 14 "Message_14" 15 "Message_15" 16 "Message_16" 17 "Message_17" 18 "Message_18" 19 "Message_19" 20 "Message_20" 21 "Message_21" 22 "Message_22" 23 "Message_23" 24 "Message_24" 25 "Message_25" 26 "Message_26" 27 "Message_27" 28 "Message_28" 29 "Message_29" 30 "Message_30" 31 "Message_31" ;
VAL_ 92 PrkBrkActv_D_RqTrnGear 0 "NotUsed1" 1 "NoRequest" 2 "RequestParkBrakeEngage" 3 "NotUsed2" ;
VAL_ 92 TrnCmdState_B_Actl 0 "No" 1 "Yes" ;
VAL_ 92 GearSelLck_D_Rq 0 "Null" 1 "Lock" 2 "Unlock" 3 "PreventionBlocker" ;
VAL_ 92 TrnLvrV_D_Rq 0 "Quiet" 1 "Normal" 2 "Aggressive" 3 "Full_Speed" ;
VAL_ 92 TrnDtpCmd_D_Actl 0 "NotUsed1" 1 "No_Command" 2 "Self_Test" 3 "Deploy" 4 "Relatch" 5 "NotUsed2" 6 "NotUsed3" 7 "NotUsed4" ;
VAL_ 92 TrnGearNtmAllow_B_Stat 0 "No" 1 "Yes" ;
VAL_ 92 TrnGearMsgTxt2_D_Rq 0 "NoMessage" 1 "Message1" 2 "Message2" 3 "Message3" 4 "Message4" 5 "Message5" 6 "Message6" 7 "Message7" 8 "Message8" 9 "Message9" 10 "Message10" 11 "Message11" 12 "Message12" 13 "Message13" 14 "Message14" 15 "Message15" 16 "Message16" 17 "Message17" 18 "Message18" 19 "Message19" 20 "Message20" 21 "Message21" 22 "Message22" 23 "Message23" 24 "Message24" 25 "Message25" 26 "Message26" 27 "Message27" 28 "Message28" 29 "Message29" 30 "Message30" 31 "Message31" ;
VAL_ 92 RaceTrakMde_D_Stat 0 "Null" 1 "NotAvailable" 2 "Available" 3 "NotUsed" ;
VAL_ 92 PrkBrkAppl_D_Rq 0 "Null" 1 "Apply" 2 "Release" 3 "PersistentUnsecured" 4 "NotUsed_1" 5 "NotUsed_2" 6 "NotUsed_3" 7 "Faulty" ;
VAL_ 96 MixblChnlZone1_D_Stat 0 "Inactive" 1 "A2B_ID1" 2 "A2B_ID2" 3 "A2B_ID3" 4 "A2B_ID4" 5 "A2B_ID5" 6 "A2B_ID6" 7 "A2B_ID7" 8 "A2B_ID8" 9 "A2B_ID9" 10 "A2B_ID10" 11 "A2B_ID11" 12 "A2B_ID12" 13 "A2B_ID13" 14 "A2B_ID14" 15 "A2B_ID15" 16 "A2B_ID16" 17 "A2B_ID17" 18 "A2B_ID18" 19 "A2B_ID19" 20 "A2B_ID20" 21 "BT_Zone2" 22 "BT_Zone3" 23 "BT_Zone4" 24 "BT_Zone5" 25 "BT_Zone6" 26 "NotUsed_1" 27 "NotUsed_2" ;
VAL_ 96 MixblChnlZone2_D_Stat 0 "Inactive" 1 "A2B_ID1" 2 "A2B_ID2" 3 "A2B_ID3" 4 "A2B_ID4" 5 "A2B_ID5" 6 "A2B_ID6" 7 "A2B_ID7" 8 "A2B_ID8" 9 "A2B_ID9" 10 "A2B_ID10" 11 "A2B_ID11" 12 "A2B_ID12" 13 "A2B_ID13" 14 "A2B_ID14" 15 "A2B_ID15" 16 "A2B_ID16" 17 "A2B_ID17" 18 "A2B_ID18" 19 "A2B_ID19" 20 "A2B_ID20" 21 "BT_Zone2" 22 "BT_Zone3" 23 "BT_Zone4" 24 "BT_Zone5" 25 "BT_Zone6" 26 "NotUsed_1" 27 "NotUsed_2" ;
VAL_ 96 SrcTypeChnl_D_Stat 0 "Inactive" 1 "A2B_ID1" 2 "A2B_ID2" 3 "A2B_ID3" 4 "A2B_ID4" 5 "A2B_ID5" 6 "A2B_ID6" 7 "A2B_ID7" 8 "A2B_ID8" 9 "A2B_ID9" 10 "A2B_ID10" 11 "A2B_ID11" 12 "A2B_ID12" 13 "A2B_ID13" 14 "A2B_ID14" 15 "A2B_ID15" 16 "A2B_ID16" 17 "A2B_ID17" 18 "A2B_ID18" 19 "A2B_ID19" 20 "A2B_ID20" 21 "BT_Zone2" 22 "BT_Zone3" 23 "BT_Zone4" 24 "BT_Zone5" 25 "BT_Zone6" 26 "NotUsed_1" 27 "NotUsed_2" ;
VAL_ 96 SrcTypeChnlZone2_D_St 0 "Inactive" 1 "A2B_ID1" 2 "A2B_ID2" 3 "A2B_ID3" 4 "A2B_ID4" 5 "A2B_ID5" 6 "A2B_ID6" 7 "A2B_ID7" 8 "A2B_ID8" 9 "A2B_ID9" 10 "A2B_ID10" 11 "A2B_ID11" 12 "A2B_ID12" 13 "A2B_ID13" 14 "A2B_ID14" 15 "A2B_ID15" 16 "A2B_ID16" 17 "A2B_ID17" 18 "A2B_ID18" 19 "A2B_ID19" 20 "A2B_ID20" 21 "BT_Zone2" 22 "BT_Zone3" 23 "BT_Zone4" 24 "BT_Zone5" 25 "BT_Zone6" 26 "NotUsed_1" 27 "NotUsed_2" ;
VAL_ 96 CabnMixblPrmpt_B_Stat 0 "Inactive" 1 "Active" ;
VAL_ 96 SpkrSel_D_Rq 0 "Inactive" 1 "External_All" 2 "External_Front" 3 "External_Rear" ;
VAL_ 96 SrcType_D_Stat 0 "InactiveAudioOFF" 1 "AuxMedia" 2 "AM" 3 "FM" 4 "SDARSSAT" 5 "SDARSIP" 6 "DAB" 7 "Phone" 8 "CallRing" 9 "RadioAnnouncement" 10 "VR" 11 "PriorityAssist" 12 "NotUsed_1" 13 "NotUsed_2" 14 "NotUsed_3" 15 "NotUsed_4" 16 "NotUsed_5" 17 "NotUsed_6" 18 "NotUsed_7" 19 "NotUsed_8" 20 "NotUsed_9" 21 "NotUsed_10" 22 "NotUsed_11" 23 "NotUsed_12" 24 "NotUsed_13" 25 "NotUsed_14" 26 "NotUsed_15" 27 "NotUsed_16" 28 "NotUsed_17" 29 "NotUsed_18" 30 "NotUsed_19" 31 "NotUsed_20" ;
VAL_ 96 MixblPrmptZone1_B_Stat 0 "Inactive" 1 "Active" ;
VAL_ 96 SrcTypeActv_D_Stat 0 "Inactive" 1 "Deallocated" 2 "Stacked" 3 "Granted" ;
VAL_ 96 SrcTypeZone2_D_Stat 0 "InactiveAudioOFF" 1 "AuxMedia" 2 "AM" 3 "FM" 4 "SDARSSAT" 5 "SDARSIP" 6 "DAB" 7 "Phone" 8 "CallRing" 9 "RadioAnnouncement" 10 "VR" 11 "PriorityAssist" 12 "NotUsed_1" 13 "NotUsed_2" 14 "NotUsed_3" 15 "NotUsed_4" 16 "NotUsed_5" 17 "NotUsed_6" 18 "NotUsed_7" 19 "NotUsed_8" 20 "NotUsed_9" 21 "NotUsed_10" 22 "NotUsed_11" 23 "NotUsed_12" 24 "NotUsed_13" 25 "NotUsed_14" 26 "NotUsed_15" 27 "NotUsed_16" 28 "NotUsed_17" 29 "NotUsed_18" 30 "NotUsed_19" 31 "NotUsed_20" ;
VAL_ 96 MixblPrmptZone2_B_Stat 0 "Inactive" 1 "Active" ;
VAL_ 96 SrcTypeActvZone2_D_St 0 "Inactive" 1 "Deallocated" 2 "Stacked" 3 "Granted" ;
VAL_ 96 SpkrAudioRoute_D_Rq 0 "Off" 1 "External_All" 2 "External_Left" 3 "External_Right" 4 "NotUsed_1" 5 "NotUsed_2" 6 "NotUsed_3" 7 "NotUsed_4" ;
VAL_ 96 VehAudioMde_D_Stat 0 "Null" 1 "Cabin" 2 "Zone" 3 "NotUsed_1" ;
VAL_ 97 SrcTypeZone3_D_Stat 0 "InactiveAudioOFF" 1 "AuxMedia" 2 "AM" 3 "FM" 4 "SDARSSAT" 5 "SDARSIP" 6 "DAB" 7 "Phone" 8 "CallRing" 9 "RadioAnnouncement" 10 "VR" 11 "PriorityAssist" 12 "NotUsed_1" 13 "NotUsed_2" 14 "NotUsed_3" 15 "NotUsed_4" 16 "NotUsed_5" 17 "NotUsed_6" 18 "NotUsed_7" 19 "NotUsed_8" 20 "NotUsed_9" 21 "NotUsed_10" 22 "NotUsed_11" 23 "NotUsed_12" 24 "NotUsed_13" 25 "NotUsed_14" 26 "NotUsed_15" 27 "NotUsed_16" 28 "NotUsed_17" 29 "NotUsed_18" 30 "NotUsed_19" 31 "NotUsed_20" ;
VAL_ 97 SrcTypeActvZone3_D_St 0 "Inactive" 1 "Deallocated" 2 "Stacked" 3 "Granted" ;
VAL_ 97 MixblPrmptZone3_B_Stat 0 "Inactive" 1 "Active" ;
VAL_ 97 SrcTypeZone5_D_Stat 0 "InactiveAudioOFF" 1 "AuxMedia" 2 "AM" 3 "FM" 4 "SDARSSAT" 5 "SDARSIP" 6 "DAB" 7 "Phone" 8 "CallRing" 9 "RadioAnnouncement" 10 "VR" 11 "PriorityAssist" 12 "NotUsed_1" 13 "NotUsed_2" 14 "NotUsed_3" 15 "NotUsed_4" 16 "NotUsed_5" 17 "NotUsed_6" 18 "NotUsed_7" 19 "NotUsed_8" 20 "NotUsed_9" 21 "NotUsed_10" 22 "NotUsed_11" 23 "NotUsed_12" 24 "NotUsed_13" 25 "NotUsed_14" 26 "NotUsed_15" 27 "NotUsed_16" 28 "NotUsed_17" 29 "NotUsed_18" 30 "NotUsed_19" 31 "NotUsed_20" ;
VAL_ 97 SrcTypeActvZone5_D_St 0 "Inactive" 1 "Deallocated" 2 "Stacked" 3 "Granted" ;
VAL_ 97 MixblPrmptZone5_B_Stat 0 "Inactive" 1 "Active" ;
VAL_ 97 MixblChnlZone3_D_Stat 0 "Inactive" 1 "A2B_ID1" 2 "A2B_ID2" 3 "A2B_ID3" 4 "A2B_ID4" 5 "A2B_ID5" 6 "A2B_ID6" 7 "A2B_ID7" 8 "A2B_ID8" 9 "A2B_ID9" 10 "A2B_ID10" 11 "A2B_ID11" 12 "A2B_ID12" 13 "A2B_ID13" 14 "A2B_ID14" 15 "A2B_ID15" 16 "A2B_ID16" 17 "A2B_ID17" 18 "A2B_ID18" 19 "A2B_ID19" 20 "A2B_ID20" 21 "A2B_ID21" 22 "A2B_ID22" 23 "A2B_ID23" 24 "A2B_ID24" 25 "A2B_ID25" 26 "A2B_ID26" 27 "A2B_ID27" 28 "A2B_ID28" 29 "A2B_ID29" 30 "A2B_ID30" 31 "A2B_ID31" 32 "A2B_ID32" 33 "BT_Zone2" 34 "BT_Zone3" 35 "BT_Zone4" 36 "BT_Zone5" 37 "BT_Zone6" 38 "NotUsed_1" 39 "NotUsed_2" 40 "NotUsed_3" 41 "NotUsed_4" 42 "NotUsed_5" 43 "NotUsed_6" 44 "NotUsed_7" 45 "NotUsed_8" 46 "NotUsed_9" 47 "NotUsed_10" 48 "NotUsed_11" 49 "NotUsed_12" 50 "NotUsed_13" 51 "NotUsed_14" 52 "NotUsed_15" 53 "NotUsed_16" 54 "NotUsed_17" 55 "NotUsed_18" 56 "NotUsed_19" 57 "NotUsed_20" 58 "NotUsed_21" 59 "NotUsed_22" 60 "NotUsed_23" 61 "NotUsed_24" 62 "NotUsed_25" 63 "NotUsed_26" 64 "NotUsed_27" 65 "NotUsed_28" 66 "NotUsed_29" 67 "NotUsed_30" 68 "NotUsed_31" 69 "NotUsed_32" 70 "NotUsed_33" 71 "NotUsed_34" 72 "NotUsed_35" 73 "NotUsed_36" 74 "NotUsed_37" 75 "NotUsed_38" 76 "NotUsed_39" 77 "NotUsed_40" 78 "NotUsed_41" 79 "NotUsed_42" 80 "NotUsed_43" 81 "NotUsed_44" 82 "NotUsed_45" 83 "NotUsed_46" 84 "NotUsed_47" 85 "NotUsed_48" 86 "NotUsed_49" 87 "NotUsed_50" 88 "NotUsed_51" 89 "NotUsed_52" 90 "NotUsed_53" 91 "NotUsed_54" 92 "NotUsed_55" 93 "NotUsed_56" 94 "NotUsed_57" 95 "NotUsed_58" 96 "NotUsed_59" 97 "NotUsed_60" 98 "NotUsed_61" 99 "NotUsed_62" 100 "NotUsed_63" 101 "NotUsed_64" 102 "NotUsed_65" 103 "NotUsed_66" 104 "NotUsed_67" 105 "NotUsed_68" 106 "NotUsed_69" 107 "NotUsed_70" 108 "NotUsed_71" 109 "NotUsed_72" 110 "NotUsed_73" 111 "NotUsed_74" 112 "NotUsed_75" 113 "NotUsed_76" 114 "NotUsed_77" 115 "NotUsed_78" 116 "NotUsed_79" 117 "NotUsed_80" 118 "NotUsed_81" 119 "NotUsed_82" 120 "NotUsed_83" 121 "NotUsed_84" 122 "NotUsed_85" 123 "NotUsed_86" 124 "NotUsed_87" 125 "NotUsed_88" 126 "NotUsed_89" 127 "NotUsed_90" 128 "NotUsed_91" 129 "NotUsed_92" 130 "NotUsed_93" 131 "NotUsed_94" 132 "NotUsed_95" 133 "NotUsed_96" 134 "NotUsed_97" 135 "NotUsed_98" 136 "NotUsed_99" 137 "NotUsed_100" 138 "NotUsed_101" 139 "NotUsed_102" 140 "NotUsed_103" 141 "NotUsed_104" 142 "NotUsed_105" 143 "NotUsed_106" 144 "NotUsed_107" 145 "NotUsed_108" 146 "NotUsed_109" 147 "NotUsed_110" 148 "NotUsed_111" 149 "NotUsed_112" 150 "NotUsed_113" 151 "NotUsed_114" 152 "NotUsed_115" 153 "NotUsed_116" 154 "NotUsed_117" 155 "NotUsed_118" 156 "NotUsed_119" 157 "NotUsed_120" 158 "NotUsed_121" 159 "NotUsed_122" 160 "NotUsed_123" 161 "NotUsed_124" 162 "NotUsed_125" 163 "NotUsed_126" 164 "NotUsed_127" 165 "NotUsed_128" 166 "NotUsed_129" 167 "NotUsed_130" 168 "NotUsed_131" 169 "NotUsed_132" 170 "NotUsed_133" 171 "NotUsed_134" 172 "NotUsed_135" 173 "NotUsed_136" 174 "NotUsed_137" 175 "NotUsed_138" 176 "NotUsed_139" 177 "NotUsed_140" 178 "NotUsed_141" 179 "NotUsed_142" 180 "NotUsed_143" 181 "NotUsed_144" 182 "NotUsed_145" 183 "NotUsed_146" 184 "NotUsed_147" 185 "NotUsed_148" 186 "NotUsed_149" 187 "NotUsed_150" 188 "NotUsed_151" 189 "NotUsed_152" 190 "NotUsed_153" 191 "NotUsed_154" 192 "NotUsed_155" 193 "NotUsed_156" 194 "NotUsed_157" 195 "NotUsed_158" 196 "NotUsed_159" 197 "NotUsed_160" 198 "NotUsed_161" 199 "NotUsed_162" 200 "NotUsed_163" 201 "NotUsed_164" 202 "NotUsed_165" 203 "NotUsed_166" 204 "NotUsed_167" 205 "NotUsed_168" 206 "NotUsed_169" 207 "NotUsed_170" 208 "NotUsed_171" 209 "NotUsed_172" 210 "NotUsed_173" 211 "NotUsed_174" 212 "NotUsed_175" 213 "NotUsed_176" 214 "NotUsed_177" 215 "NotUsed_178" 216 "NotUsed_179" 217 "NotUsed_180" 218 "NotUsed_181" 219 "NotUsed_182" 220 "NotUsed_183" 221 "NotUsed_184" 222 "NotUsed_185" 223 "NotUsed_186" 224 "NotUsed_187" 225 "NotUsed_188" 226 "NotUsed_189" 227 "NotUsed_190" 228 "NotUsed_191" 229 "NotUsed_192" 230 "NotUsed_193" 231 "NotUsed_194" 232 "NotUsed_195" 233 "NotUsed_196" 234 "NotUsed_197" 235 "NotUsed_198" 236 "NotUsed_199" 237 "NotUsed_200" 238 "NotUsed_201" 239 "NotUsed_202" 240 "NotUsed_203" 241 "NotUsed_204" 242 "NotUsed_205" 243 "NotUsed_206" 244 "NotUsed_207" 245 "NotUsed_208" 246 "NotUsed_209" 247 "NotUsed_210" 248 " NotUsed_211" 249 "NotUsed_212" 250 "NotUsed_213" 251 "NotUsed_214" 252 "NotUsed_215" 253 "NotUsed_216" 254 "NotUsed_217" 255 "NotUsed_218" ;
VAL_ 97 MixblChnlZone5_D_Stat 0 "Inactive" 1 "A2B_ID1" 2 "A2B_ID2" 3 "A2B_ID3" 4 "A2B_ID4" 5 "A2B_ID5" 6 "A2B_ID6" 7 "A2B_ID7" 8 "A2B_ID8" 9 "A2B_ID9" 10 "A2B_ID10" 11 "A2B_ID11" 12 "A2B_ID12" 13 "A2B_ID13" 14 "A2B_ID14" 15 "A2B_ID15" 16 "A2B_ID16" 17 "A2B_ID17" 18 "A2B_ID18" 19 "A2B_ID19" 20 "A2B_ID20" 21 "A2B_ID21" 22 "A2B_ID22" 23 "A2B_ID23" 24 "A2B_ID24" 25 "A2B_ID25" 26 "A2B_ID26" 27 "A2B_ID27" 28 "A2B_ID28" 29 "A2B_ID29" 30 "A2B_ID30" 31 "A2B_ID31" 32 "A2B_ID32" 33 "BT_Zone2" 34 "BT_Zone3" 35 "BT_Zone4" 36 "BT_Zone5" 37 "BT_Zone6" 38 "NotUsed_1" 39 "NotUsed_2" 40 "NotUsed_3" 41 "NotUsed_4" 42 "NotUsed_5" 43 "NotUsed_6" 44 "NotUsed_7" 45 "NotUsed_8" 46 "NotUsed_9" 47 "NotUsed_10" 48 "NotUsed_11" 49 "NotUsed_12" 50 "NotUsed_13" 51 "NotUsed_14" 52 "NotUsed_15" 53 "NotUsed_16" 54 "NotUsed_17" 55 "NotUsed_18" 56 "NotUsed_19" 57 "NotUsed_20" 58 "NotUsed_21" 59 "NotUsed_22" 60 "NotUsed_23" 61 "NotUsed_24" 62 "NotUsed_25" 63 "NotUsed_26" 64 "NotUsed_27" 65 "NotUsed_28" 66 "NotUsed_29" 67 "NotUsed_30" 68 "NotUsed_31" 69 "NotUsed_32" 70 "NotUsed_33" 71 "NotUsed_34" 72 "NotUsed_35" 73 "NotUsed_36" 74 "NotUsed_37" 75 "NotUsed_38" 76 "NotUsed_39" 77 "NotUsed_40" 78 "NotUsed_41" 79 "NotUsed_42" 80 "NotUsed_43" 81 "NotUsed_44" 82 "NotUsed_45" 83 "NotUsed_46" 84 "NotUsed_47" 85 "NotUsed_48" 86 "NotUsed_49" 87 "NotUsed_50" 88 "NotUsed_51" 89 "NotUsed_52" 90 "NotUsed_53" 91 "NotUsed_54" 92 "NotUsed_55" 93 "NotUsed_56" 94 "NotUsed_57" 95 "NotUsed_58" 96 "NotUsed_59" 97 "NotUsed_60" 98 "NotUsed_61" 99 "NotUsed_62" 100 "NotUsed_63" 101 "NotUsed_64" 102 "NotUsed_65" 103 "NotUsed_66" 104 "NotUsed_67" 105 "NotUsed_68" 106 "NotUsed_69" 107 "NotUsed_70" 108 "NotUsed_71" 109 "NotUsed_72" 110 "NotUsed_73" 111 "NotUsed_74" 112 "NotUsed_75" 113 "NotUsed_76" 114 "NotUsed_77" 115 "NotUsed_78" 116 "NotUsed_79" 117 "NotUsed_80" 118 "NotUsed_81" 119 "NotUsed_82" 120 "NotUsed_83" 121 "NotUsed_84" 122 "NotUsed_85" 123 "NotUsed_86" 124 "NotUsed_87" 125 "NotUsed_88" 126 "NotUsed_89" 127 "NotUsed_90" 128 "NotUsed_91" 129 "NotUsed_92" 130 "NotUsed_93" 131 "NotUsed_94" 132 "NotUsed_95" 133 "NotUsed_96" 134 "NotUsed_97" 135 "NotUsed_98" 136 "NotUsed_99" 137 "NotUsed_100" 138 "NotUsed_101" 139 "NotUsed_102" 140 "NotUsed_103" 141 "NotUsed_104" 142 "NotUsed_105" 143 "NotUsed_106" 144 "NotUsed_107" 145 "NotUsed_108" 146 "NotUsed_109" 147 "NotUsed_110" 148 "NotUsed_111" 149 "NotUsed_112" 150 "NotUsed_113" 151 "NotUsed_114" 152 "NotUsed_115" 153 "NotUsed_116" 154 "NotUsed_117" 155 "NotUsed_118" 156 "NotUsed_119" 157 "NotUsed_120" 158 "NotUsed_121" 159 "NotUsed_122" 160 "NotUsed_123" 161 "NotUsed_124" 162 "NotUsed_125" 163 "NotUsed_126" 164 "NotUsed_127" 165 "NotUsed_128" 166 "NotUsed_129" 167 "NotUsed_130" 168 "NotUsed_131" 169 "NotUsed_132" 170 "NotUsed_133" 171 "NotUsed_134" 172 "NotUsed_135" 173 "NotUsed_136" 174 "NotUsed_137" 175 "NotUsed_138" 176 "NotUsed_139" 177 "NotUsed_140" 178 "NotUsed_141" 179 "NotUsed_142" 180 "NotUsed_143" 181 "NotUsed_144" 182 "NotUsed_145" 183 "NotUsed_146" 184 "NotUsed_147" 185 "NotUsed_148" 186 "NotUsed_149" 187 "NotUsed_150" 188 "NotUsed_151" 189 "NotUsed_152" 190 "NotUsed_153" 191 "NotUsed_154" 192 "NotUsed_155" 193 "NotUsed_156" 194 "NotUsed_157" 195 "NotUsed_158" 196 "NotUsed_159" 197 "NotUsed_160" 198 "NotUsed_161" 199 "NotUsed_162" 200 "NotUsed_163" 201 "NotUsed_164" 202 "NotUsed_165" 203 "NotUsed_166" 204 "NotUsed_167" 205 "NotUsed_168" 206 "NotUsed_169" 207 "NotUsed_170" 208 "NotUsed_171" 209 "NotUsed_172" 210 "NotUsed_173" 211 "NotUsed_174" 212 "NotUsed_175" 213 "NotUsed_176" 214 "NotUsed_177" 215 "NotUsed_178" 216 "NotUsed_179" 217 "NotUsed_180" 218 "NotUsed_181" 219 "NotUsed_182" 220 "NotUsed_183" 221 "NotUsed_184" 222 "NotUsed_185" 223 "NotUsed_186" 224 "NotUsed_187" 225 "NotUsed_188" 226 "NotUsed_189" 227 "NotUsed_190" 228 "NotUsed_191" 229 "NotUsed_192" 230 "NotUsed_193" 231 "NotUsed_194" 232 "NotUsed_195" 233 "NotUsed_196" 234 "NotUsed_197" 235 "NotUsed_198" 236 "NotUsed_199" 237 "NotUsed_200" 238 "NotUsed_201" 239 "NotUsed_202" 240 "NotUsed_203" 241 "NotUsed_204" 242 "NotUsed_205" 243 "NotUsed_206" 244 "NotUsed_207" 245 "NotUsed_208" 246 "NotUsed_209" 247 "NotUsed_210" 248 " NotUsed_211" 249 "NotUsed_212" 250 "NotUsed_213" 251 "NotUsed_214" 252 "NotUsed_215" 253 "NotUsed_216" 254 "NotUsed_217" 255 "NotUsed_218" ;
VAL_ 97 SrcTypeChnlZone3_D_St 0 "Inactive" 1 "A2B_ID1" 2 "A2B_ID2" 3 "A2B_ID3" 4 "A2B_ID4" 5 "A2B_ID5" 6 "A2B_ID6" 7 "A2B_ID7" 8 "A2B_ID8" 9 "A2B_ID9" 10 "A2B_ID10" 11 "A2B_ID11" 12 "A2B_ID12" 13 "A2B_ID13" 14 "A2B_ID14" 15 "A2B_ID15" 16 "A2B_ID16" 17 "A2B_ID17" 18 "A2B_ID18" 19 "A2B_ID19" 20 "A2B_ID20" 21 "A2B_ID21" 22 "A2B_ID22" 23 "A2B_ID23" 24 "A2B_ID24" 25 "A2B_ID25" 26 "A2B_ID26" 27 "A2B_ID27" 28 "A2B_ID28" 29 "A2B_ID29" 30 "A2B_ID30" 31 "A2B_ID31" 32 "A2B_ID32" 33 "BT_Zone2" 34 "BT_Zone3" 35 "BT_Zone4" 36 "BT_Zone5" 37 "BT_Zone6" 38 "NotUsed_1" 39 "NotUsed_2" 40 "NotUsed_3" 41 "NotUsed_4" 42 "NotUsed_5" 43 "NotUsed_6" 44 "NotUsed_7" 45 "NotUsed_8" 46 "NotUsed_9" 47 "NotUsed_10" 48 "NotUsed_11" 49 "NotUsed_12" 50 "NotUsed_13" 51 "NotUsed_14" 52 "NotUsed_15" 53 "NotUsed_16" 54 "NotUsed_17" 55 "NotUsed_18" 56 "NotUsed_19" 57 "NotUsed_20" 58 "NotUsed_21" 59 "NotUsed_22" 60 "NotUsed_23" 61 "NotUsed_24" 62 "NotUsed_25" 63 "NotUsed_26" 64 "NotUsed_27" 65 "NotUsed_28" 66 "NotUsed_29" 67 "NotUsed_30" 68 "NotUsed_31" 69 "NotUsed_32" 70 "NotUsed_33" 71 "NotUsed_34" 72 "NotUsed_35" 73 "NotUsed_36" 74 "NotUsed_37" 75 "NotUsed_38" 76 "NotUsed_39" 77 "NotUsed_40" 78 "NotUsed_41" 79 "NotUsed_42" 80 "NotUsed_43" 81 "NotUsed_44" 82 "NotUsed_45" 83 "NotUsed_46" 84 "NotUsed_47" 85 "NotUsed_48" 86 "NotUsed_49" 87 "NotUsed_50" 88 "NotUsed_51" 89 "NotUsed_52" 90 "NotUsed_53" 91 "NotUsed_54" 92 "NotUsed_55" 93 "NotUsed_56" 94 "NotUsed_57" 95 "NotUsed_58" 96 "NotUsed_59" 97 "NotUsed_60" 98 "NotUsed_61" 99 "NotUsed_62" 100 "NotUsed_63" 101 "NotUsed_64" 102 "NotUsed_65" 103 "NotUsed_66" 104 "NotUsed_67" 105 "NotUsed_68" 106 "NotUsed_69" 107 "NotUsed_70" 108 "NotUsed_71" 109 "NotUsed_72" 110 "NotUsed_73" 111 "NotUsed_74" 112 "NotUsed_75" 113 "NotUsed_76" 114 "NotUsed_77" 115 "NotUsed_78" 116 "NotUsed_79" 117 "NotUsed_80" 118 "NotUsed_81" 119 "NotUsed_82" 120 "NotUsed_83" 121 "NotUsed_84" 122 "NotUsed_85" 123 "NotUsed_86" 124 "NotUsed_87" 125 "NotUsed_88" 126 "NotUsed_89" 127 "NotUsed_90" 128 "NotUsed_91" 129 "NotUsed_92" 130 "NotUsed_93" 131 "NotUsed_94" 132 "NotUsed_95" 133 "NotUsed_96" 134 "NotUsed_97" 135 "NotUsed_98" 136 "NotUsed_99" 137 "NotUsed_100" 138 "NotUsed_101" 139 "NotUsed_102" 140 "NotUsed_103" 141 "NotUsed_104" 142 "NotUsed_105" 143 "NotUsed_106" 144 "NotUsed_107" 145 "NotUsed_108" 146 "NotUsed_109" 147 "NotUsed_110" 148 "NotUsed_111" 149 "NotUsed_112" 150 "NotUsed_113" 151 "NotUsed_114" 152 "NotUsed_115" 153 "NotUsed_116" 154 "NotUsed_117" 155 "NotUsed_118" 156 "NotUsed_119" 157 "NotUsed_120" 158 "NotUsed_121" 159 "NotUsed_122" 160 "NotUsed_123" 161 "NotUsed_124" 162 "NotUsed_125" 163 "NotUsed_126" 164 "NotUsed_127" 165 "NotUsed_128" 166 "NotUsed_129" 167 "NotUsed_130" 168 "NotUsed_131" 169 "NotUsed_132" 170 "NotUsed_133" 171 "NotUsed_134" 172 "NotUsed_135" 173 "NotUsed_136" 174 "NotUsed_137" 175 "NotUsed_138" 176 "NotUsed_139" 177 "NotUsed_140" 178 "NotUsed_141" 179 "NotUsed_142" 180 "NotUsed_143" 181 "NotUsed_144" 182 "NotUsed_145" 183 "NotUsed_146" 184 "NotUsed_147" 185 "NotUsed_148" 186 "NotUsed_149" 187 "NotUsed_150" 188 "NotUsed_151" 189 "NotUsed_152" 190 "NotUsed_153" 191 "NotUsed_154" 192 "NotUsed_155" 193 "NotUsed_156" 194 "NotUsed_157" 195 "NotUsed_158" 196 "NotUsed_159" 197 "NotUsed_160" 198 "NotUsed_161" 199 "NotUsed_162" 200 "NotUsed_163" 201 "NotUsed_164" 202 "NotUsed_165" 203 "NotUsed_166" 204 "NotUsed_167" 205 "NotUsed_168" 206 "NotUsed_169" 207 "NotUsed_170" 208 "NotUsed_171" 209 "NotUsed_172" 210 "NotUsed_173" 211 "NotUsed_174" 212 "NotUsed_175" 213 "NotUsed_176" 214 "NotUsed_177" 215 "NotUsed_178" 216 "NotUsed_179" 217 "NotUsed_180" 218 "NotUsed_181" 219 "NotUsed_182" 220 "NotUsed_183" 221 "NotUsed_184" 222 "NotUsed_185" 223 "NotUsed_186" 224 "NotUsed_187" 225 "NotUsed_188" 226 "NotUsed_189" 227 "NotUsed_190" 228 "NotUsed_191" 229 "NotUsed_192" 230 "NotUsed_193" 231 "NotUsed_194" 232 "NotUsed_195" 233 "NotUsed_196" 234 "NotUsed_197" 235 "NotUsed_198" 236 "NotUsed_199" 237 "NotUsed_200" 238 "NotUsed_201" 239 "NotUsed_202" 240 "NotUsed_203" 241 "NotUsed_204" 242 "NotUsed_205" 243 "NotUsed_206" 244 "NotUsed_207" 245 "NotUsed_208" 246 "NotUsed_209" 247 "NotUsed_210" 248 " NotUsed_211" 249 "NotUsed_212" 250 "NotUsed_213" 251 "NotUsed_214" 252 "NotUsed_215" 253 "NotUsed_216" 254 "NotUsed_217" 255 "NotUsed_218" ;
VAL_ 97 SrcTypeChnlZone5_D_St 0 "Inactive" 1 "A2B_ID1" 2 "A2B_ID2" 3 "A2B_ID3" 4 "A2B_ID4" 5 "A2B_ID5" 6 "A2B_ID6" 7 "A2B_ID7" 8 "A2B_ID8" 9 "A2B_ID9" 10 "A2B_ID10" 11 "A2B_ID11" 12 "A2B_ID12" 13 "A2B_ID13" 14 "A2B_ID14" 15 "A2B_ID15" 16 "A2B_ID16" 17 "A2B_ID17" 18 "A2B_ID18" 19 "A2B_ID19" 20 "A2B_ID20" 21 "A2B_ID21" 22 "A2B_ID22" 23 "A2B_ID23" 24 "A2B_ID24" 25 "A2B_ID25" 26 "A2B_ID26" 27 "A2B_ID27" 28 "A2B_ID28" 29 "A2B_ID29" 30 "A2B_ID30" 31 "A2B_ID31" 32 "A2B_ID32" 33 "BT_Zone2" 34 "BT_Zone3" 35 "BT_Zone4" 36 "BT_Zone5" 37 "BT_Zone6" 38 "NotUsed_1" 39 "NotUsed_2" 40 "NotUsed_3" 41 "NotUsed_4" 42 "NotUsed_5" 43 "NotUsed_6" 44 "NotUsed_7" 45 "NotUsed_8" 46 "NotUsed_9" 47 "NotUsed_10" 48 "NotUsed_11" 49 "NotUsed_12" 50 "NotUsed_13" 51 "NotUsed_14" 52 "NotUsed_15" 53 "NotUsed_16" 54 "NotUsed_17" 55 "NotUsed_18" 56 "NotUsed_19" 57 "NotUsed_20" 58 "NotUsed_21" 59 "NotUsed_22" 60 "NotUsed_23" 61 "NotUsed_24" 62 "NotUsed_25" 63 "NotUsed_26" 64 "NotUsed_27" 65 "NotUsed_28" 66 "NotUsed_29" 67 "NotUsed_30" 68 "NotUsed_31" 69 "NotUsed_32" 70 "NotUsed_33" 71 "NotUsed_34" 72 "NotUsed_35" 73 "NotUsed_36" 74 "NotUsed_37" 75 "NotUsed_38" 76 "NotUsed_39" 77 "NotUsed_40" 78 "NotUsed_41" 79 "NotUsed_42" 80 "NotUsed_43" 81 "NotUsed_44" 82 "NotUsed_45" 83 "NotUsed_46" 84 "NotUsed_47" 85 "NotUsed_48" 86 "NotUsed_49" 87 "NotUsed_50" 88 "NotUsed_51" 89 "NotUsed_52" 90 "NotUsed_53" 91 "NotUsed_54" 92 "NotUsed_55" 93 "NotUsed_56" 94 "NotUsed_57" 95 "NotUsed_58" 96 "NotUsed_59" 97 "NotUsed_60" 98 "NotUsed_61" 99 "NotUsed_62" 100 "NotUsed_63" 101 "NotUsed_64" 102 "NotUsed_65" 103 "NotUsed_66" 104 "NotUsed_67" 105 "NotUsed_68" 106 "NotUsed_69" 107 "NotUsed_70" 108 "NotUsed_71" 109 "NotUsed_72" 110 "NotUsed_73" 111 "NotUsed_74" 112 "NotUsed_75" 113 "NotUsed_76" 114 "NotUsed_77" 115 "NotUsed_78" 116 "NotUsed_79" 117 "NotUsed_80" 118 "NotUsed_81" 119 "NotUsed_82" 120 "NotUsed_83" 121 "NotUsed_84" 122 "NotUsed_85" 123 "NotUsed_86" 124 "NotUsed_87" 125 "NotUsed_88" 126 "NotUsed_89" 127 "NotUsed_90" 128 "NotUsed_91" 129 "NotUsed_92" 130 "NotUsed_93" 131 "NotUsed_94" 132 "NotUsed_95" 133 "NotUsed_96" 134 "NotUsed_97" 135 "NotUsed_98" 136 "NotUsed_99" 137 "NotUsed_100" 138 "NotUsed_101" 139 "NotUsed_102" 140 "NotUsed_103" 141 "NotUsed_104" 142 "NotUsed_105" 143 "NotUsed_106" 144 "NotUsed_107" 145 "NotUsed_108" 146 "NotUsed_109" 147 "NotUsed_110" 148 "NotUsed_111" 149 "NotUsed_112" 150 "NotUsed_113" 151 "NotUsed_114" 152 "NotUsed_115" 153 "NotUsed_116" 154 "NotUsed_117" 155 "NotUsed_118" 156 "NotUsed_119" 157 "NotUsed_120" 158 "NotUsed_121" 159 "NotUsed_122" 160 "NotUsed_123" 161 "NotUsed_124" 162 "NotUsed_125" 163 "NotUsed_126" 164 "NotUsed_127" 165 "NotUsed_128" 166 "NotUsed_129" 167 "NotUsed_130" 168 "NotUsed_131" 169 "NotUsed_132" 170 "NotUsed_133" 171 "NotUsed_134" 172 "NotUsed_135" 173 "NotUsed_136" 174 "NotUsed_137" 175 "NotUsed_138" 176 "NotUsed_139" 177 "NotUsed_140" 178 "NotUsed_141" 179 "NotUsed_142" 180 "NotUsed_143" 181 "NotUsed_144" 182 "NotUsed_145" 183 "NotUsed_146" 184 "NotUsed_147" 185 "NotUsed_148" 186 "NotUsed_149" 187 "NotUsed_150" 188 "NotUsed_151" 189 "NotUsed_152" 190 "NotUsed_153" 191 "NotUsed_154" 192 "NotUsed_155" 193 "NotUsed_156" 194 "NotUsed_157" 195 "NotUsed_158" 196 "NotUsed_159" 197 "NotUsed_160" 198 "NotUsed_161" 199 "NotUsed_162" 200 "NotUsed_163" 201 "NotUsed_164" 202 "NotUsed_165" 203 "NotUsed_166" 204 "NotUsed_167" 205 "NotUsed_168" 206 "NotUsed_169" 207 "NotUsed_170" 208 "NotUsed_171" 209 "NotUsed_172" 210 "NotUsed_173" 211 "NotUsed_174" 212 "NotUsed_175" 213 "NotUsed_176" 214 "NotUsed_177" 215 "NotUsed_178" 216 "NotUsed_179" 217 "NotUsed_180" 218 "NotUsed_181" 219 "NotUsed_182" 220 "NotUsed_183" 221 "NotUsed_184" 222 "NotUsed_185" 223 "NotUsed_186" 224 "NotUsed_187" 225 "NotUsed_188" 226 "NotUsed_189" 227 "NotUsed_190" 228 "NotUsed_191" 229 "NotUsed_192" 230 "NotUsed_193" 231 "NotUsed_194" 232 "NotUsed_195" 233 "NotUsed_196" 234 "NotUsed_197" 235 "NotUsed_198" 236 "NotUsed_199" 237 "NotUsed_200" 238 "NotUsed_201" 239 "NotUsed_202" 240 "NotUsed_203" 241 "NotUsed_204" 242 "NotUsed_205" 243 "NotUsed_206" 244 "NotUsed_207" 245 "NotUsed_208" 246 "NotUsed_209" 247 "NotUsed_210" 248 " NotUsed_211" 249 "NotUsed_212" 250 "NotUsed_213" 251 "NotUsed_214" 252 "NotUsed_215" 253 "NotUsed_216" 254 "NotUsed_217" 255 "NotUsed_218" ;
VAL_ 98 SrcTypeZone4_D_Stat 0 "InactiveAudioOFF" 1 "AuxMedia" 2 "AM" 3 "FM" 4 "SDARSSAT" 5 "SDARSIP" 6 "DAB" 7 "Phone" 8 "CallRing" 9 "RadioAnnouncement" 10 "VR" 11 "PriorityAssist" 12 "NotUsed_1" 13 "NotUsed_2" 14 "NotUsed_3" 15 "NotUsed_4" 16 "NotUsed_5" 17 "NotUsed_6" 18 "NotUsed_7" 19 "NotUsed_8" 20 "NotUsed_9" 21 "NotUsed_10" 22 "NotUsed_11" 23 "NotUsed_12" 24 "NotUsed_13" 25 "NotUsed_14" 26 "NotUsed_15" 27 "NotUsed_16" 28 "NotUsed_17" 29 "NotUsed_18" 30 "NotUsed_19" 31 "NotUsed_20" ;
VAL_ 98 SrcTypeActvZone4_D_St 0 "Inactive" 1 "Deallocated" 2 "Stacked" 3 "Granted" ;
VAL_ 98 MixblPrmptZone4_B_Stat 0 "Inactive" 1 "Active" ;
VAL_ 98 SrcTypeZone6_D_Stat 0 "InactiveAudioOFF" 1 "AuxMedia" 2 "AM" 3 "FM" 4 "SDARSSAT" 5 "SDARSIP" 6 "DAB" 7 "Phone" 8 "CallRing" 9 "RadioAnnouncement" 10 "VR" 11 "PriorityAssist" 12 "NotUsed_1" 13 "NotUsed_2" 14 "NotUsed_3" 15 "NotUsed_4" 16 "NotUsed_5" 17 "NotUsed_6" 18 "NotUsed_7" 19 "NotUsed_8" 20 "NotUsed_9" 21 "NotUsed_10" 22 "NotUsed_11" 23 "NotUsed_12" 24 "NotUsed_13" 25 "NotUsed_14" 26 "NotUsed_15" 27 "NotUsed_16" 28 "NotUsed_17" 29 "NotUsed_18" 30 "NotUsed_19" 31 "NotUsed_20" ;
VAL_ 98 SrcTypeActvZone6_D_St 0 "Inactive" 1 "Deallocated" 2 "Stacked" 3 "Granted" ;
VAL_ 98 MixblPrmptZone6_B_Stat 0 "Inactive" 1 "Active" ;
VAL_ 98 MixblChnlZone4_D_Stat 0 "Inactive" 1 "A2B_ID1" 2 "A2B_ID2" 3 "A2B_ID3" 4 "A2B_ID4" 5 "A2B_ID5" 6 "A2B_ID6" 7 "A2B_ID7" 8 "A2B_ID8" 9 "A2B_ID9" 10 "A2B_ID10" 11 "A2B_ID11" 12 "A2B_ID12" 13 "A2B_ID13" 14 "A2B_ID14" 15 "A2B_ID15" 16 "A2B_ID16" 17 "A2B_ID17" 18 "A2B_ID18" 19 "A2B_ID19" 20 "A2B_ID20" 21 "A2B_ID21" 22 "A2B_ID22" 23 "A2B_ID23" 24 "A2B_ID24" 25 "A2B_ID25" 26 "A2B_ID26" 27 "A2B_ID27" 28 "A2B_ID28" 29 "A2B_ID29" 30 "A2B_ID30" 31 "A2B_ID31" 32 "A2B_ID32" 33 "BT_Zone2" 34 "BT_Zone3" 35 "BT_Zone4" 36 "BT_Zone5" 37 "BT_Zone6" 38 "NotUsed_1" 39 "NotUsed_2" 40 "NotUsed_3" 41 "NotUsed_4" 42 "NotUsed_5" 43 "NotUsed_6" 44 "NotUsed_7" 45 "NotUsed_8" 46 "NotUsed_9" 47 "NotUsed_10" 48 "NotUsed_11" 49 "NotUsed_12" 50 "NotUsed_13" 51 "NotUsed_14" 52 "NotUsed_15" 53 "NotUsed_16" 54 "NotUsed_17" 55 "NotUsed_18" 56 "NotUsed_19" 57 "NotUsed_20" 58 "NotUsed_21" 59 "NotUsed_22" 60 "NotUsed_23" 61 "NotUsed_24" 62 "NotUsed_25" 63 "NotUsed_26" 64 "NotUsed_27" 65 "NotUsed_28" 66 "NotUsed_29" 67 "NotUsed_30" 68 "NotUsed_31" 69 "NotUsed_32" 70 "NotUsed_33" 71 "NotUsed_34" 72 "NotUsed_35" 73 "NotUsed_36" 74 "NotUsed_37" 75 "NotUsed_38" 76 "NotUsed_39" 77 "NotUsed_40" 78 "NotUsed_41" 79 "NotUsed_42" 80 "NotUsed_43" 81 "NotUsed_44" 82 "NotUsed_45" 83 "NotUsed_46" 84 "NotUsed_47" 85 "NotUsed_48" 86 "NotUsed_49" 87 "NotUsed_50" 88 "NotUsed_51" 89 "NotUsed_52" 90 "NotUsed_53" 91 "NotUsed_54" 92 "NotUsed_55" 93 "NotUsed_56" 94 "NotUsed_57" 95 "NotUsed_58" 96 "NotUsed_59" 97 "NotUsed_60" 98 "NotUsed_61" 99 "NotUsed_62" 100 "NotUsed_63" 101 "NotUsed_64" 102 "NotUsed_65" 103 "NotUsed_66" 104 "NotUsed_67" 105 "NotUsed_68" 106 "NotUsed_69" 107 "NotUsed_70" 108 "NotUsed_71" 109 "NotUsed_72" 110 "NotUsed_73" 111 "NotUsed_74" 112 "NotUsed_75" 113 "NotUsed_76" 114 "NotUsed_77" 115 "NotUsed_78" 116 "NotUsed_79" 117 "NotUsed_80" 118 "NotUsed_81" 119 "NotUsed_82" 120 "NotUsed_83" 121 "NotUsed_84" 122 "NotUsed_85" 123 "NotUsed_86" 124 "NotUsed_87" 125 "NotUsed_88" 126 "NotUsed_89" 127 "NotUsed_90" 128 "NotUsed_91" 129 "NotUsed_92" 130 "NotUsed_93" 131 "NotUsed_94" 132 "NotUsed_95" 133 "NotUsed_96" 134 "NotUsed_97" 135 "NotUsed_98" 136 "NotUsed_99" 137 "NotUsed_100" 138 "NotUsed_101" 139 "NotUsed_102" 140 "NotUsed_103" 141 "NotUsed_104" 142 "NotUsed_105" 143 "NotUsed_106" 144 "NotUsed_107" 145 "NotUsed_108" 146 "NotUsed_109" 147 "NotUsed_110" 148 "NotUsed_111" 149 "NotUsed_112" 150 "NotUsed_113" 151 "NotUsed_114" 152 "NotUsed_115" 153 "NotUsed_116" 154 "NotUsed_117" 155 "NotUsed_118" 156 "NotUsed_119" 157 "NotUsed_120" 158 "NotUsed_121" 159 "NotUsed_122" 160 "NotUsed_123" 161 "NotUsed_124" 162 "NotUsed_125" 163 "NotUsed_126" 164 "NotUsed_127" 165 "NotUsed_128" 166 "NotUsed_129" 167 "NotUsed_130" 168 "NotUsed_131" 169 "NotUsed_132" 170 "NotUsed_133" 171 "NotUsed_134" 172 "NotUsed_135" 173 "NotUsed_136" 174 "NotUsed_137" 175 "NotUsed_138" 176 "NotUsed_139" 177 "NotUsed_140" 178 "NotUsed_141" 179 "NotUsed_142" 180 "NotUsed_143" 181 "NotUsed_144" 182 "NotUsed_145" 183 "NotUsed_146" 184 "NotUsed_147" 185 "NotUsed_148" 186 "NotUsed_149" 187 "NotUsed_150" 188 "NotUsed_151" 189 "NotUsed_152" 190 "NotUsed_153" 191 "NotUsed_154" 192 "NotUsed_155" 193 "NotUsed_156" 194 "NotUsed_157" 195 "NotUsed_158" 196 "NotUsed_159" 197 "NotUsed_160" 198 "NotUsed_161" 199 "NotUsed_162" 200 "NotUsed_163" 201 "NotUsed_164" 202 "NotUsed_165" 203 "NotUsed_166" 204 "NotUsed_167" 205 "NotUsed_168" 206 "NotUsed_169" 207 "NotUsed_170" 208 "NotUsed_171" 209 "NotUsed_172" 210 "NotUsed_173" 211 "NotUsed_174" 212 "NotUsed_175" 213 "NotUsed_176" 214 "NotUsed_177" 215 "NotUsed_178" 216 "NotUsed_179" 217 "NotUsed_180" 218 "NotUsed_181" 219 "NotUsed_182" 220 "NotUsed_183" 221 "NotUsed_184" 222 "NotUsed_185" 223 "NotUsed_186" 224 "NotUsed_187" 225 "NotUsed_188" 226 "NotUsed_189" 227 "NotUsed_190" 228 "NotUsed_191" 229 "NotUsed_192" 230 "NotUsed_193" 231 "NotUsed_194" 232 "NotUsed_195" 233 "NotUsed_196" 234 "NotUsed_197" 235 "NotUsed_198" 236 "NotUsed_199" 237 "NotUsed_200" 238 "NotUsed_201" 239 "NotUsed_202" 240 "NotUsed_203" 241 "NotUsed_204" 242 "NotUsed_205" 243 "NotUsed_206" 244 "NotUsed_207" 245 "NotUsed_208" 246 "NotUsed_209" 247 "NotUsed_210" 248 " NotUsed_211" 249 "NotUsed_212" 250 "NotUsed_213" 251 "NotUsed_214" 252 "NotUsed_215" 253 "NotUsed_216" 254 "NotUsed_217" 255 "NotUsed_218" ;
VAL_ 98 MixblChnlZone6_D_Stat 0 "Inactive" 1 "A2B_ID1" 2 "A2B_ID2" 3 "A2B_ID3" 4 "A2B_ID4" 5 "A2B_ID5" 6 "A2B_ID6" 7 "A2B_ID7" 8 "A2B_ID8" 9 "A2B_ID9" 10 "A2B_ID10" 11 "A2B_ID11" 12 "A2B_ID12" 13 "A2B_ID13" 14 "A2B_ID14" 15 "A2B_ID15" 16 "A2B_ID16" 17 "A2B_ID17" 18 "A2B_ID18" 19 "A2B_ID19" 20 "A2B_ID20" 21 "A2B_ID21" 22 "A2B_ID22" 23 "A2B_ID23" 24 "A2B_ID24" 25 "A2B_ID25" 26 "A2B_ID26" 27 "A2B_ID27" 28 "A2B_ID28" 29 "A2B_ID29" 30 "A2B_ID30" 31 "A2B_ID31" 32 "A2B_ID32" 33 "BT_Zone2" 34 "BT_Zone3" 35 "BT_Zone4" 36 "BT_Zone5" 37 "BT_Zone6" 38 "NotUsed_1" 39 "NotUsed_2" 40 "NotUsed_3" 41 "NotUsed_4" 42 "NotUsed_5" 43 "NotUsed_6" 44 "NotUsed_7" 45 "NotUsed_8" 46 "NotUsed_9" 47 "NotUsed_10" 48 "NotUsed_11" 49 "NotUsed_12" 50 "NotUsed_13" 51 "NotUsed_14" 52 "NotUsed_15" 53 "NotUsed_16" 54 "NotUsed_17" 55 "NotUsed_18" 56 "NotUsed_19" 57 "NotUsed_20" 58 "NotUsed_21" 59 "NotUsed_22" 60 "NotUsed_23" 61 "NotUsed_24" 62 "NotUsed_25" 63 "NotUsed_26" 64 "NotUsed_27" 65 "NotUsed_28" 66 "NotUsed_29" 67 "NotUsed_30" 68 "NotUsed_31" 69 "NotUsed_32" 70 "NotUsed_33" 71 "NotUsed_34" 72 "NotUsed_35" 73 "NotUsed_36" 74 "NotUsed_37" 75 "NotUsed_38" 76 "NotUsed_39" 77 "NotUsed_40" 78 "NotUsed_41" 79 "NotUsed_42" 80 "NotUsed_43" 81 "NotUsed_44" 82 "NotUsed_45" 83 "NotUsed_46" 84 "NotUsed_47" 85 "NotUsed_48" 86 "NotUsed_49" 87 "NotUsed_50" 88 "NotUsed_51" 89 "NotUsed_52" 90 "NotUsed_53" 91 "NotUsed_54" 92 "NotUsed_55" 93 "NotUsed_56" 94 "NotUsed_57" 95 "NotUsed_58" 96 "NotUsed_59" 97 "NotUsed_60" 98 "NotUsed_61" 99 "NotUsed_62" 100 "NotUsed_63" 101 "NotUsed_64" 102 "NotUsed_65" 103 "NotUsed_66" 104 "NotUsed_67" 105 "NotUsed_68" 106 "NotUsed_69" 107 "NotUsed_70" 108 "NotUsed_71" 109 "NotUsed_72" 110 "NotUsed_73" 111 "NotUsed_74" 112 "NotUsed_75" 113 "NotUsed_76" 114 "NotUsed_77" 115 "NotUsed_78" 116 "NotUsed_79" 117 "NotUsed_80" 118 "NotUsed_81" 119 "NotUsed_82" 120 "NotUsed_83" 121 "NotUsed_84" 122 "NotUsed_85" 123 "NotUsed_86" 124 "NotUsed_87" 125 "NotUsed_88" 126 "NotUsed_89" 127 "NotUsed_90" 128 "NotUsed_91" 129 "NotUsed_92" 130 "NotUsed_93" 131 "NotUsed_94" 132 "NotUsed_95" 133 "NotUsed_96" 134 "NotUsed_97" 135 "NotUsed_98" 136 "NotUsed_99" 137 "NotUsed_100" 138 "NotUsed_101" 139 "NotUsed_102" 140 "NotUsed_103" 141 "NotUsed_104" 142 "NotUsed_105" 143 "NotUsed_106" 144 "NotUsed_107" 145 "NotUsed_108" 146 "NotUsed_109" 147 "NotUsed_110" 148 "NotUsed_111" 149 "NotUsed_112" 150 "NotUsed_113" 151 "NotUsed_114" 152 "NotUsed_115" 153 "NotUsed_116" 154 "NotUsed_117" 155 "NotUsed_118" 156 "NotUsed_119" 157 "NotUsed_120" 158 "NotUsed_121" 159 "NotUsed_122" 160 "NotUsed_123" 161 "NotUsed_124" 162 "NotUsed_125" 163 "NotUsed_126" 164 "NotUsed_127" 165 "NotUsed_128" 166 "NotUsed_129" 167 "NotUsed_130" 168 "NotUsed_131" 169 "NotUsed_132" 170 "NotUsed_133" 171 "NotUsed_134" 172 "NotUsed_135" 173 "NotUsed_136" 174 "NotUsed_137" 175 "NotUsed_138" 176 "NotUsed_139" 177 "NotUsed_140" 178 "NotUsed_141" 179 "NotUsed_142" 180 "NotUsed_143" 181 "NotUsed_144" 182 "NotUsed_145" 183 "NotUsed_146" 184 "NotUsed_147" 185 "NotUsed_148" 186 "NotUsed_149" 187 "NotUsed_150" 188 "NotUsed_151" 189 "NotUsed_152" 190 "NotUsed_153" 191 "NotUsed_154" 192 "NotUsed_155" 193 "NotUsed_156" 194 "NotUsed_157" 195 "NotUsed_158" 196 "NotUsed_159" 197 "NotUsed_160" 198 "NotUsed_161" 199 "NotUsed_162" 200 "NotUsed_163" 201 "NotUsed_164" 202 "NotUsed_165" 203 "NotUsed_166" 204 "NotUsed_167" 205 "NotUsed_168" 206 "NotUsed_169" 207 "NotUsed_170" 208 "NotUsed_171" 209 "NotUsed_172" 210 "NotUsed_173" 211 "NotUsed_174" 212 "NotUsed_175" 213 "NotUsed_176" 214 "NotUsed_177" 215 "NotUsed_178" 216 "NotUsed_179" 217 "NotUsed_180" 218 "NotUsed_181" 219 "NotUsed_182" 220 "NotUsed_183" 221 "NotUsed_184" 222 "NotUsed_185" 223 "NotUsed_186" 224 "NotUsed_187" 225 "NotUsed_188" 226 "NotUsed_189" 227 "NotUsed_190" 228 "NotUsed_191" 229 "NotUsed_192" 230 "NotUsed_193" 231 "NotUsed_194" 232 "NotUsed_195" 233 "NotUsed_196" 234 "NotUsed_197" 235 "NotUsed_198" 236 "NotUsed_199" 237 "NotUsed_200" 238 "NotUsed_201" 239 "NotUsed_202" 240 "NotUsed_203" 241 "NotUsed_204" 242 "NotUsed_205" 243 "NotUsed_206" 244 "NotUsed_207" 245 "NotUsed_208" 246 "NotUsed_209" 247 "NotUsed_210" 248 " NotUsed_211" 249 "NotUsed_212" 250 "NotUsed_213" 251 "NotUsed_214" 252 "NotUsed_215" 253 "NotUsed_216" 254 "NotUsed_217" 255 "NotUsed_218" ;
VAL_ 98 SrcTypeChnlZone6_D_St 0 "Inactive" 1 "A2B_ID1" 2 "A2B_ID2" 3 "A2B_ID3" 4 "A2B_ID4" 5 "A2B_ID5" 6 "A2B_ID6" 7 "A2B_ID7" 8 "A2B_ID8" 9 "A2B_ID9" 10 "A2B_ID10" 11 "A2B_ID11" 12 "A2B_ID12" 13 "A2B_ID13" 14 "A2B_ID14" 15 "A2B_ID15" 16 "A2B_ID16" 17 "A2B_ID17" 18 "A2B_ID18" 19 "A2B_ID19" 20 "A2B_ID20" 21 "A2B_ID21" 22 "A2B_ID22" 23 "A2B_ID23" 24 "A2B_ID24" 25 "A2B_ID25" 26 "A2B_ID26" 27 "A2B_ID27" 28 "A2B_ID28" 29 "A2B_ID29" 30 "A2B_ID30" 31 "A2B_ID31" 32 "A2B_ID32" 33 "BT_Zone2" 34 "BT_Zone3" 35 "BT_Zone4" 36 "BT_Zone5" 37 "BT_Zone6" 38 "NotUsed_1" 39 "NotUsed_2" 40 "NotUsed_3" 41 "NotUsed_4" 42 "NotUsed_5" 43 "NotUsed_6" 44 "NotUsed_7" 45 "NotUsed_8" 46 "NotUsed_9" 47 "NotUsed_10" 48 "NotUsed_11" 49 "NotUsed_12" 50 "NotUsed_13" 51 "NotUsed_14" 52 "NotUsed_15" 53 "NotUsed_16" 54 "NotUsed_17" 55 "NotUsed_18" 56 "NotUsed_19" 57 "NotUsed_20" 58 "NotUsed_21" 59 "NotUsed_22" 60 "NotUsed_23" 61 "NotUsed_24" 62 "NotUsed_25" 63 "NotUsed_26" 64 "NotUsed_27" 65 "NotUsed_28" 66 "NotUsed_29" 67 "NotUsed_30" 68 "NotUsed_31" 69 "NotUsed_32" 70 "NotUsed_33" 71 "NotUsed_34" 72 "NotUsed_35" 73 "NotUsed_36" 74 "NotUsed_37" 75 "NotUsed_38" 76 "NotUsed_39" 77 "NotUsed_40" 78 "NotUsed_41" 79 "NotUsed_42" 80 "NotUsed_43" 81 "NotUsed_44" 82 "NotUsed_45" 83 "NotUsed_46" 84 "NotUsed_47" 85 "NotUsed_48" 86 "NotUsed_49" 87 "NotUsed_50" 88 "NotUsed_51" 89 "NotUsed_52" 90 "NotUsed_53" 91 "NotUsed_54" 92 "NotUsed_55" 93 "NotUsed_56" 94 "NotUsed_57" 95 "NotUsed_58" 96 "NotUsed_59" 97 "NotUsed_60" 98 "NotUsed_61" 99 "NotUsed_62" 100 "NotUsed_63" 101 "NotUsed_64" 102 "NotUsed_65" 103 "NotUsed_66" 104 "NotUsed_67" 105 "NotUsed_68" 106 "NotUsed_69" 107 "NotUsed_70" 108 "NotUsed_71" 109 "NotUsed_72" 110 "NotUsed_73" 111 "NotUsed_74" 112 "NotUsed_75" 113 "NotUsed_76" 114 "NotUsed_77" 115 "NotUsed_78" 116 "NotUsed_79" 117 "NotUsed_80" 118 "NotUsed_81" 119 "NotUsed_82" 120 "NotUsed_83" 121 "NotUsed_84" 122 "NotUsed_85" 123 "NotUsed_86" 124 "NotUsed_87" 125 "NotUsed_88" 126 "NotUsed_89" 127 "NotUsed_90" 128 "NotUsed_91" 129 "NotUsed_92" 130 "NotUsed_93" 131 "NotUsed_94" 132 "NotUsed_95" 133 "NotUsed_96" 134 "NotUsed_97" 135 "NotUsed_98" 136 "NotUsed_99" 137 "NotUsed_100" 138 "NotUsed_101" 139 "NotUsed_102" 140 "NotUsed_103" 141 "NotUsed_104" 142 "NotUsed_105" 143 "NotUsed_106" 144 "NotUsed_107" 145 "NotUsed_108" 146 "NotUsed_109" 147 "NotUsed_110" 148 "NotUsed_111" 149 "NotUsed_112" 150 "NotUsed_113" 151 "NotUsed_114" 152 "NotUsed_115" 153 "NotUsed_116" 154 "NotUsed_117" 155 "NotUsed_118" 156 "NotUsed_119" 157 "NotUsed_120" 158 "NotUsed_121" 159 "NotUsed_122" 160 "NotUsed_123" 161 "NotUsed_124" 162 "NotUsed_125" 163 "NotUsed_126" 164 "NotUsed_127" 165 "NotUsed_128" 166 "NotUsed_129" 167 "NotUsed_130" 168 "NotUsed_131" 169 "NotUsed_132" 170 "NotUsed_133" 171 "NotUsed_134" 172 "NotUsed_135" 173 "NotUsed_136" 174 "NotUsed_137" 175 "NotUsed_138" 176 "NotUsed_139" 177 "NotUsed_140" 178 "NotUsed_141" 179 "NotUsed_142" 180 "NotUsed_143" 181 "NotUsed_144" 182 "NotUsed_145" 183 "NotUsed_146" 184 "NotUsed_147" 185 "NotUsed_148" 186 "NotUsed_149" 187 "NotUsed_150" 188 "NotUsed_151" 189 "NotUsed_152" 190 "NotUsed_153" 191 "NotUsed_154" 192 "NotUsed_155" 193 "NotUsed_156" 194 "NotUsed_157" 195 "NotUsed_158" 196 "NotUsed_159" 197 "NotUsed_160" 198 "NotUsed_161" 199 "NotUsed_162" 200 "NotUsed_163" 201 "NotUsed_164" 202 "NotUsed_165" 203 "NotUsed_166" 204 "NotUsed_167" 205 "NotUsed_168" 206 "NotUsed_169" 207 "NotUsed_170" 208 "NotUsed_171" 209 "NotUsed_172" 210 "NotUsed_173" 211 "NotUsed_174" 212 "NotUsed_175" 213 "NotUsed_176" 214 "NotUsed_177" 215 "NotUsed_178" 216 "NotUsed_179" 217 "NotUsed_180" 218 "NotUsed_181" 219 "NotUsed_182" 220 "NotUsed_183" 221 "NotUsed_184" 222 "NotUsed_185" 223 "NotUsed_186" 224 "NotUsed_187" 225 "NotUsed_188" 226 "NotUsed_189" 227 "NotUsed_190" 228 "NotUsed_191" 229 "NotUsed_192" 230 "NotUsed_193" 231 "NotUsed_194" 232 "NotUsed_195" 233 "NotUsed_196" 234 "NotUsed_197" 235 "NotUsed_198" 236 "NotUsed_199" 237 "NotUsed_200" 238 "NotUsed_201" 239 "NotUsed_202" 240 "NotUsed_203" 241 "NotUsed_204" 242 "NotUsed_205" 243 "NotUsed_206" 244 "NotUsed_207" 245 "NotUsed_208" 246 "NotUsed_209" 247 "NotUsed_210" 248 " NotUsed_211" 249 "NotUsed_212" 250 "NotUsed_213" 251 "NotUsed_214" 252 "NotUsed_215" 253 "NotUsed_216" 254 "NotUsed_217" 255 "NotUsed_218" ;
VAL_ 98 SrcTypeChnlZone4_D_St 0 "Inactive" 1 "A2B_ID1" 2 "A2B_ID2" 3 "A2B_ID3" 4 "A2B_ID4" 5 "A2B_ID5" 6 "A2B_ID6" 7 "A2B_ID7" 8 "A2B_ID8" 9 "A2B_ID9" 10 "A2B_ID10" 11 "A2B_ID11" 12 "A2B_ID12" 13 "A2B_ID13" 14 "A2B_ID14" 15 "A2B_ID15" 16 "A2B_ID16" 17 "A2B_ID17" 18 "A2B_ID18" 19 "A2B_ID19" 20 "A2B_ID20" 21 "A2B_ID21" 22 "A2B_ID22" 23 "A2B_ID23" 24 "A2B_ID24" 25 "A2B_ID25" 26 "A2B_ID26" 27 "A2B_ID27" 28 "A2B_ID28" 29 "A2B_ID29" 30 "A2B_ID30" 31 "A2B_ID31" 32 "A2B_ID32" 33 "BT_Zone2" 34 "BT_Zone3" 35 "BT_Zone4" 36 "BT_Zone5" 37 "BT_Zone6" 38 "NotUsed_1" 39 "NotUsed_2" 40 "NotUsed_3" 41 "NotUsed_4" 42 "NotUsed_5" 43 "NotUsed_6" 44 "NotUsed_7" 45 "NotUsed_8" 46 "NotUsed_9" 47 "NotUsed_10" 48 "NotUsed_11" 49 "NotUsed_12" 50 "NotUsed_13" 51 "NotUsed_14" 52 "NotUsed_15" 53 "NotUsed_16" 54 "NotUsed_17" 55 "NotUsed_18" 56 "NotUsed_19" 57 "NotUsed_20" 58 "NotUsed_21" 59 "NotUsed_22" 60 "NotUsed_23" 61 "NotUsed_24" 62 "NotUsed_25" 63 "NotUsed_26" 64 "NotUsed_27" 65 "NotUsed_28" 66 "NotUsed_29" 67 "NotUsed_30" 68 "NotUsed_31" 69 "NotUsed_32" 70 "NotUsed_33" 71 "NotUsed_34" 72 "NotUsed_35" 73 "NotUsed_36" 74 "NotUsed_37" 75 "NotUsed_38" 76 "NotUsed_39" 77 "NotUsed_40" 78 "NotUsed_41" 79 "NotUsed_42" 80 "NotUsed_43" 81 "NotUsed_44" 82 "NotUsed_45" 83 "NotUsed_46" 84 "NotUsed_47" 85 "NotUsed_48" 86 "NotUsed_49" 87 "NotUsed_50" 88 "NotUsed_51" 89 "NotUsed_52" 90 "NotUsed_53" 91 "NotUsed_54" 92 "NotUsed_55" 93 "NotUsed_56" 94 "NotUsed_57" 95 "NotUsed_58" 96 "NotUsed_59" 97 "NotUsed_60" 98 "NotUsed_61" 99 "NotUsed_62" 100 "NotUsed_63" 101 "NotUsed_64" 102 "NotUsed_65" 103 "NotUsed_66" 104 "NotUsed_67" 105 "NotUsed_68" 106 "NotUsed_69" 107 "NotUsed_70" 108 "NotUsed_71" 109 "NotUsed_72" 110 "NotUsed_73" 111 "NotUsed_74" 112 "NotUsed_75" 113 "NotUsed_76" 114 "NotUsed_77" 115 "NotUsed_78" 116 "NotUsed_79" 117 "NotUsed_80" 118 "NotUsed_81" 119 "NotUsed_82" 120 "NotUsed_83" 121 "NotUsed_84" 122 "NotUsed_85" 123 "NotUsed_86" 124 "NotUsed_87" 125 "NotUsed_88" 126 "NotUsed_89" 127 "NotUsed_90" 128 "NotUsed_91" 129 "NotUsed_92" 130 "NotUsed_93" 131 "NotUsed_94" 132 "NotUsed_95" 133 "NotUsed_96" 134 "NotUsed_97" 135 "NotUsed_98" 136 "NotUsed_99" 137 "NotUsed_100" 138 "NotUsed_101" 139 "NotUsed_102" 140 "NotUsed_103" 141 "NotUsed_104" 142 "NotUsed_105" 143 "NotUsed_106" 144 "NotUsed_107" 145 "NotUsed_108" 146 "NotUsed_109" 147 "NotUsed_110" 148 "NotUsed_111" 149 "NotUsed_112" 150 "NotUsed_113" 151 "NotUsed_114" 152 "NotUsed_115" 153 "NotUsed_116" 154 "NotUsed_117" 155 "NotUsed_118" 156 "NotUsed_119" 157 "NotUsed_120" 158 "NotUsed_121" 159 "NotUsed_122" 160 "NotUsed_123" 161 "NotUsed_124" 162 "NotUsed_125" 163 "NotUsed_126" 164 "NotUsed_127" 165 "NotUsed_128" 166 "NotUsed_129" 167 "NotUsed_130" 168 "NotUsed_131" 169 "NotUsed_132" 170 "NotUsed_133" 171 "NotUsed_134" 172 "NotUsed_135" 173 "NotUsed_136" 174 "NotUsed_137" 175 "NotUsed_138" 176 "NotUsed_139" 177 "NotUsed_140" 178 "NotUsed_141" 179 "NotUsed_142" 180 "NotUsed_143" 181 "NotUsed_144" 182 "NotUsed_145" 183 "NotUsed_146" 184 "NotUsed_147" 185 "NotUsed_148" 186 "NotUsed_149" 187 "NotUsed_150" 188 "NotUsed_151" 189 "NotUsed_152" 190 "NotUsed_153" 191 "NotUsed_154" 192 "NotUsed_155" 193 "NotUsed_156" 194 "NotUsed_157" 195 "NotUsed_158" 196 "NotUsed_159" 197 "NotUsed_160" 198 "NotUsed_161" 199 "NotUsed_162" 200 "NotUsed_163" 201 "NotUsed_164" 202 "NotUsed_165" 203 "NotUsed_166" 204 "NotUsed_167" 205 "NotUsed_168" 206 "NotUsed_169" 207 "NotUsed_170" 208 "NotUsed_171" 209 "NotUsed_172" 210 "NotUsed_173" 211 "NotUsed_174" 212 "NotUsed_175" 213 "NotUsed_176" 214 "NotUsed_177" 215 "NotUsed_178" 216 "NotUsed_179" 217 "NotUsed_180" 218 "NotUsed_181" 219 "NotUsed_182" 220 "NotUsed_183" 221 "NotUsed_184" 222 "NotUsed_185" 223 "NotUsed_186" 224 "NotUsed_187" 225 "NotUsed_188" 226 "NotUsed_189" 227 "NotUsed_190" 228 "NotUsed_191" 229 "NotUsed_192" 230 "NotUsed_193" 231 "NotUsed_194" 232 "NotUsed_195" 233 "NotUsed_196" 234 "NotUsed_197" 235 "NotUsed_198" 236 "NotUsed_199" 237 "NotUsed_200" 238 "NotUsed_201" 239 "NotUsed_202" 240 "NotUsed_203" 241 "NotUsed_204" 242 "NotUsed_205" 243 "NotUsed_206" 244 "NotUsed_207" 245 "NotUsed_208" 246 "NotUsed_209" 247 "NotUsed_210" 248 " NotUsed_211" 249 "NotUsed_212" 250 "NotUsed_213" 251 "NotUsed_214" 252 "NotUsed_215" 253 "NotUsed_216" 254 "NotUsed_217" 255 "NotUsed_218" ;
VAL_ 99 OffstVolUpdtZone2_B_St 0 "NoUpdate" 1 "Update" ;
VAL_ 99 OffstVolUpdtZone1_B_St 0 "NoUpdate" 1 "Update" ;
VAL_ 99 OffstVolUpdtZone4_B_St 0 "NoUpdate" 1 "Update" ;
VAL_ 99 OffstVolUpdtZone3_B_St 0 "NoUpdate" 1 "Update" ;
VAL_ 99 OffstVolUpdtZone6_B_St 0 "NoUpdate" 1 "Update" ;
VAL_ 99 OffstVolUpdtZone5_B_St 0 "NoUpdate" 1 "Update" ;
VAL_ 99 MedVolUpdt_B_Stat 0 "NoUpdate" 1 "Update" ;
VAL_ 99 CabnMedVolLvl_D_Stat 0 "No_Volume" 1 "Vol_Step1" 2 "Vol_Step2" 3 "Vol_Step3" 4 "Vol_Step4" 5 "Vol_Step5" 6 "Vol_Step6" 7 "Vol_Step7" 8 "Vol_Step8" 9 "Vol_Step9" 10 "Vol_Step10" 11 "Vol_Step11" 12 "Vol_Step12" 13 "Vol_Step13" 14 "Vol_Step14" 15 "Vol_Step15" 16 "Vol_Step16" 17 "Vol_Step17" 18 "Vol_Step18" 19 "Vol_Step19" 20 "Vol_Step20" 21 "Vol_Step21" 22 "Vol_Step22" 23 "Vol_Step23" 24 "Vol_Step24" 25 "Vol_Step25" 26 "Vol_Step26" 27 "Vol_Step27" 28 "Vol_Step28" 29 "Vol_Step29" 30 "Vol_Step30" 31 "NotUsed_1" ;
VAL_ 99 PhonVolUpdt_B_Stat 0 "NoUpdate" 1 "Update" ;
VAL_ 99 CabnPhonVolLvl_D_Stat 0 "No_Volume" 1 "Vol_Step1" 2 "Vol_Step2" 3 "Vol_Step3" 4 "Vol_Step4" 5 "Vol_Step5" 6 "Vol_Step6" 7 "Vol_Step7" 8 "Vol_Step8" 9 "Vol_Step9" 10 "Vol_Step10" 11 "Vol_Step11" 12 "Vol_Step12" 13 "Vol_Step13" 14 "Vol_Step14" 15 "Vol_Step15" 16 "Vol_Step16" 17 "Vol_Step17" 18 "Vol_Step18" 19 "Vol_Step19" 20 "Vol_Step20" 21 "Vol_Step21" 22 "Vol_Step22" 23 "Vol_Step23" 24 "Vol_Step24" 25 "Vol_Step25" 26 "Vol_Step26" 27 "Vol_Step27" 28 "Vol_Step28" 29 "Vol_Step29" 30 "Vol_Step30" 31 "NotUsed_1" ;
VAL_ 99 PrmptVolUpdt_B_Stat 0 "NoUpdate" 1 "Update" ;
VAL_ 99 CabnPrmptVolLvl_D_Stat 0 "No_Volume" 1 "Vol_Step1" 2 "Vol_Step2" 3 "Vol_Step3" 4 "Vol_Step4" 5 "Vol_Step5" 6 "Vol_Step6" 7 "Vol_Step7" 8 "Vol_Step8" 9 "Vol_Step9" 10 "Vol_Step10" 11 "Vol_Step11" 12 "Vol_Step12" 13 "Vol_Step13" 14 "Vol_Step14" 15 "Vol_Step15" 16 "Vol_Step16" 17 "Vol_Step17" 18 "Vol_Step18" 19 "Vol_Step19" 20 "Vol_Step20" 21 "Vol_Step21" 22 "Vol_Step22" 23 "Vol_Step23" 24 "Vol_Step24" 25 "Vol_Step25" 26 "Vol_Step26" 27 "Vol_Step27" 28 "Vol_Step28" 29 "Vol_Step29" 30 "Vol_Step30" 31 "NotUsed_1" ;
VAL_ 99 RaVolUpdt_B_Stat 0 "NoUpdate" 1 "Update" ;
VAL_ 99 CabnRaVolLvl_D_Stat 0 "No_Volume" 1 "Vol_Step1" 2 "Vol_Step2" 3 "Vol_Step3" 4 "Vol_Step4" 5 "Vol_Step5" 6 "Vol_Step6" 7 "Vol_Step7" 8 "Vol_Step8" 9 "Vol_Step9" 10 "Vol_Step10" 11 "Vol_Step11" 12 "Vol_Step12" 13 "Vol_Step13" 14 "Vol_Step14" 15 "Vol_Step15" 16 "Vol_Step16" 17 "Vol_Step17" 18 "Vol_Step18" 19 "Vol_Step19" 20 "Vol_Step20" 21 "Vol_Step21" 22 "Vol_Step22" 23 "Vol_Step23" 24 "Vol_Step24" 25 "Vol_Step25" 26 "Vol_Step26" 27 "Vol_Step27" 28 "Vol_Step28" 29 "Vol_Step29" 30 "Vol_Step30" 31 "NotUsed_1" ;
VAL_ 99 CallRngVolUpdt_B_Stat 0 "NoUpdate" 1 "Update" ;
VAL_ 99 CabnCallRngVolLvl_D_St 0 "No_Volume" 1 "Vol_Step1" 2 "Vol_Step2" 3 "Vol_Step3" 4 "Vol_Step4" 5 "Vol_Step5" 6 "Vol_Step6" 7 "Vol_Step7" 8 "Vol_Step8" 9 "Vol_Step9" 10 "Vol_Step10" 11 "Vol_Step11" 12 "Vol_Step12" 13 "Vol_Step13" 14 "Vol_Step14" 15 "Vol_Step15" 16 "Vol_Step16" 17 "Vol_Step17" 18 "Vol_Step18" 19 "Vol_Step19" 20 "Vol_Step20" 21 "Vol_Step21" 22 "Vol_Step22" 23 "Vol_Step23" 24 "Vol_Step24" 25 "Vol_Step25" 26 "Vol_Step26" 27 "Vol_Step27" 28 "Vol_Step28" 29 "Vol_Step29" 30 "Vol_Step30" 31 "NotUsed_1" ;
VAL_ 100 OvrhdLamp_B_Rq 0 "Not_Pressed" 1 "Pressed" ;
VAL_ 100 DrDefeatMde_B_Rq 0 "Disable" 1 "Enable" ;
VAL_ 100 MedVolUpdtZone1_B_Stat 0 "NoUpdate" 1 "Update" ;
VAL_ 100 MedVolLvlZone1_D_Stat 0 "No_Volume" 1 "Vol_Step1" 2 "Vol_Step2" 3 "Vol_Step3" 4 "Vol_Step4" 5 "Vol_Step5" 6 "Vol_Step6" 7 "Vol_Step7" 8 "Vol_Step8" 9 "Vol_Step9" 10 "Vol_Step10" 11 "Vol_Step11" 12 "Vol_Step12" 13 "Vol_Step13" 14 "Vol_Step14" 15 "Vol_Step15" 16 "Vol_Step16" 17 "Vol_Step17" 18 "Vol_Step18" 19 "Vol_Step19" 20 "Vol_Step20" 21 "Vol_Step21" 22 "Vol_Step22" 23 "Vol_Step23" 24 "Vol_Step24" 25 "Vol_Step25" 26 "Vol_Step26" 27 "Vol_Step27" 28 "Vol_Step28" 29 "Vol_Step29" 30 "Vol_Step30" 31 "NotUsed_1" ;
VAL_ 100 OvrhdLampFmid_B_Rq 0 "Not_Pressed" 1 "Pressed" ;
VAL_ 100 OvrhdLampFl_B_Rq 0 "Not_Pressed" 1 "Pressed" ;
VAL_ 100 MedVolUpdtZone2_B_Stat 0 "NoUpdate" 1 "Update" ;
VAL_ 100 MedVolLvlZone2_D_Stat 0 "No_Volume" 1 "Vol_Step1" 2 "Vol_Step2" 3 "Vol_Step3" 4 "Vol_Step4" 5 "Vol_Step5" 6 "Vol_Step6" 7 "Vol_Step7" 8 "Vol_Step8" 9 "Vol_Step9" 10 "Vol_Step10" 11 "Vol_Step11" 12 "Vol_Step12" 13 "Vol_Step13" 14 "Vol_Step14" 15 "Vol_Step15" 16 "Vol_Step16" 17 "Vol_Step17" 18 "Vol_Step18" 19 "Vol_Step19" 20 "Vol_Step20" 21 "Vol_Step21" 22 "Vol_Step22" 23 "Vol_Step23" 24 "Vol_Step24" 25 "Vol_Step25" 26 "Vol_Step26" 27 "Vol_Step27" 28 "Vol_Step28" 29 "Vol_Step29" 30 "Vol_Step30" 31 "NotUsed_1" ;
VAL_ 100 OvrhdLampR2Left_B_Rq 0 "Not_Pressed" 1 "Pressed" ;
VAL_ 100 OvrhdLampFr_B_Rq 0 "Not_Pressed" 1 "Pressed" ;
VAL_ 100 MedVolUpdtZone3_B_Stat 0 "NoUpdate" 1 "Update" ;
VAL_ 100 MedVolLvlZone3_D_Stat 0 "No_Volume" 1 "Vol_Step1" 2 "Vol_Step2" 3 "Vol_Step3" 4 "Vol_Step4" 5 "Vol_Step5" 6 "Vol_Step6" 7 "Vol_Step7" 8 "Vol_Step8" 9 "Vol_Step9" 10 "Vol_Step10" 11 "Vol_Step11" 12 "Vol_Step12" 13 "Vol_Step13" 14 "Vol_Step14" 15 "Vol_Step15" 16 "Vol_Step16" 17 "Vol_Step17" 18 "Vol_Step18" 19 "Vol_Step19" 20 "Vol_Step20" 21 "Vol_Step21" 22 "Vol_Step22" 23 "Vol_Step23" 24 "Vol_Step24" 25 "Vol_Step25" 26 "Vol_Step26" 27 "Vol_Step27" 28 "Vol_Step28" 29 "Vol_Step29" 30 "Vol_Step30" 31 "NotUsed_1" ;
VAL_ 100 OvrhdLampR2Right_B_Rq 0 "Not_Pressed" 1 "Pressed" ;
VAL_ 100 OvrhdLampR2Mid_B_Rq 0 "Not_Pressed" 1 "Pressed" ;
VAL_ 100 MedVolUpdtZone4_B_Stat 0 "NoUpdate" 1 "Update" ;
VAL_ 100 MedVolLvlZone4_D_Stat 0 "No_Volume" 1 "Vol_Step1" 2 "Vol_Step2" 3 "Vol_Step3" 4 "Vol_Step4" 5 "Vol_Step5" 6 "Vol_Step6" 7 "Vol_Step7" 8 "Vol_Step8" 9 "Vol_Step9" 10 "Vol_Step10" 11 "Vol_Step11" 12 "Vol_Step12" 13 "Vol_Step13" 14 "Vol_Step14" 15 "Vol_Step15" 16 "Vol_Step16" 17 "Vol_Step17" 18 "Vol_Step18" 19 "Vol_Step19" 20 "Vol_Step20" 21 "Vol_Step21" 22 "Vol_Step22" 23 "Vol_Step23" 24 "Vol_Step24" 25 "Vol_Step25" 26 "Vol_Step26" 27 "Vol_Step27" 28 "Vol_Step28" 29 "Vol_Step29" 30 "Vol_Step30" 31 "NotUsed_1" ;
VAL_ 100 OvrhdLampR3Mid_B_Rq 0 "Not_Pressed" 1 "Pressed" ;
VAL_ 100 OvrhdLampR3Left_B_Rq 0 "Noy_Pressed" 1 "Pressed" ;
VAL_ 100 MedVolUpdtZone5_B_Stat 0 "NoUpdate" 1 "Update" ;
VAL_ 100 MedVolLvlZone5_D_Stat 0 "No_Volume" 1 "Vol_Step1" 2 "Vol_Step2" 3 "Vol_Step3" 4 "Vol_Step4" 5 "Vol_Step5" 6 "Vol_Step6" 7 "Vol_Step7" 8 "Vol_Step8" 9 "Vol_Step9" 10 "Vol_Step10" 11 "Vol_Step11" 12 "Vol_Step12" 13 "Vol_Step13" 14 "Vol_Step14" 15 "Vol_Step15" 16 "Vol_Step16" 17 "Vol_Step17" 18 "Vol_Step18" 19 "Vol_Step19" 20 "Vol_Step20" 21 "Vol_Step21" 22 "Vol_Step22" 23 "Vol_Step23" 24 "Vol_Step24" 25 "Vol_Step25" 26 "Vol_Step26" 27 "Vol_Step27" 28 "Vol_Step28" 29 "Vol_Step29" 30 "Vol_Step30" 31 "NotUsed_1" ;
VAL_ 100 OvrhdLampR3Right_B_Rq 0 "Not_Pressed" 1 "Pressed" ;
VAL_ 100 MedVolUpdtZone6_B_Stat 0 "NoUpdate" 1 "Update" ;
VAL_ 100 MedVolLvlZone6_D_Stat 0 "No_Volume" 1 "Vol_Step1" 2 "Vol_Step2" 3 "Vol_Step3" 4 "Vol_Step4" 5 "Vol_Step5" 6 "Vol_Step6" 7 "Vol_Step7" 8 "Vol_Step8" 9 "Vol_Step9" 10 "Vol_Step10" 11 "Vol_Step11" 12 "Vol_Step12" 13 "Vol_Step13" 14 "Vol_Step14" 15 "Vol_Step15" 16 "Vol_Step16" 17 "Vol_Step17" 18 "Vol_Step18" 19 "Vol_Step19" 20 "Vol_Step20" 21 "Vol_Step21" 22 "Vol_Step22" 23 "Vol_Step23" 24 "Vol_Step24" 25 "Vol_Step25" 26 "Vol_Step26" 27 "Vol_Step27" 28 "Vol_Step28" 29 "Vol_Step29" 30 "Vol_Step30" 31 "NotUsed_1" ;
VAL_ 100 PersStorePsngr_D_Rq 0 "Null" 1 "PERS_1" 2 "PERS_2" 3 "PERS_3" 4 "PERS_4" 5 "Vehicle" 6 "NotUsed_1" 7 "NotUsed_2" ;
VAL_ 100 PersRecallPsngr_D_Rq 0 "Null" 1 "PERS_1" 2 "PERS_2" 3 "PERS_3" 4 "PERS_4" 5 "Vehicle" 6 "NotUsed_1" 7 "NotUsed_2" ;
VAL_ 100 StwblStewMde_D_RqMnu 0 "UNUSED" 1 "UNUSED" 2 "UNUSED" 3 "UNUSED" ;
VAL_ 101 PrmptVolUpdtZone1_B_St 0 "NoUpdate" 1 "Update" ;
VAL_ 101 PrmptVolLvlZone1_D_St 0 "No_Volume" 1 "Vol_Step1" 2 "Vol_Step2" 3 "Vol_Step3" 4 "Vol_Step4" 5 "Vol_Step5" 6 "Vol_Step6" 7 "Vol_Step7" 8 "Vol_Step8" 9 "Vol_Step9" 10 "Vol_Step10" 11 "Vol_Step11" 12 "Vol_Step12" 13 "Vol_Step13" 14 "Vol_Step14" 15 "Vol_Step15" 16 "Vol_Step16" 17 "Vol_Step17" 18 "Vol_Step18" 19 "Vol_Step19" 20 "Vol_Step20" 21 "Vol_Step21" 22 "Vol_Step22" 23 "Vol_Step23" 24 "Vol_Step24" 25 "Vol_Step25" 26 "Vol_Step26" 27 "Vol_Step27" 28 "Vol_Step28" 29 "Vol_Step29" 30 "Vol_Step30" 31 "NotUsed_1" ;
VAL_ 101 PrmptVolUpdtZone2_B_St 0 "NoUpdate" 1 "Update" ;
VAL_ 101 PrmptVolLvlZone2_D_St 0 "No_Volume" 1 "Vol_Step1" 2 "Vol_Step2" 3 "Vol_Step3" 4 "Vol_Step4" 5 "Vol_Step5" 6 "Vol_Step6" 7 "Vol_Step7" 8 "Vol_Step8" 9 "Vol_Step9" 10 "Vol_Step10" 11 "Vol_Step11" 12 "Vol_Step12" 13 "Vol_Step13" 14 "Vol_Step14" 15 "Vol_Step15" 16 "Vol_Step16" 17 "Vol_Step17" 18 "Vol_Step18" 19 "Vol_Step19" 20 "Vol_Step20" 21 "Vol_Step21" 22 "Vol_Step22" 23 "Vol_Step23" 24 "Vol_Step24" 25 "Vol_Step25" 26 "Vol_Step26" 27 "Vol_Step27" 28 "Vol_Step28" 29 "Vol_Step29" 30 "Vol_Step30" 31 "NotUsed_1" ;
VAL_ 101 PrmptVolUpdtZone3_B_St 0 "NoUpdate" 1 "Update" ;
VAL_ 101 PrmptVolLvlZone3_D_St 0 "No_Volume" 1 "Vol_Step1" 2 "Vol_Step2" 3 "Vol_Step3" 4 "Vol_Step4" 5 "Vol_Step5" 6 "Vol_Step6" 7 "Vol_Step7" 8 "Vol_Step8" 9 "Vol_Step9" 10 "Vol_Step10" 11 "Vol_Step11" 12 "Vol_Step12" 13 "Vol_Step13" 14 "Vol_Step14" 15 "Vol_Step15" 16 "Vol_Step16" 17 "Vol_Step17" 18 "Vol_Step18" 19 "Vol_Step19" 20 "Vol_Step20" 21 "Vol_Step21" 22 "Vol_Step22" 23 "Vol_Step23" 24 "Vol_Step24" 25 "Vol_Step25" 26 "Vol_Step26" 27 "Vol_Step27" 28 "Vol_Step28" 29 "Vol_Step29" 30 "Vol_Step30" 31 "NotUsed_1" ;
VAL_ 101 PrmptVolUpdtZone4_B_St 0 "NoUpdate" 1 "Update" ;
VAL_ 101 PrmptVolLvlZone4_D_St 0 "No_Volume" 1 "Vol_Step1" 2 "Vol_Step2" 3 "Vol_Step3" 4 "Vol_Step4" 5 "Vol_Step5" 6 "Vol_Step6" 7 "Vol_Step7" 8 "Vol_Step8" 9 "Vol_Step9" 10 "Vol_Step10" 11 "Vol_Step11" 12 "Vol_Step12" 13 "Vol_Step13" 14 "Vol_Step14" 15 "Vol_Step15" 16 "Vol_Step16" 17 "Vol_Step17" 18 "Vol_Step18" 19 "Vol_Step19" 20 "Vol_Step20" 21 "Vol_Step21" 22 "Vol_Step22" 23 "Vol_Step23" 24 "Vol_Step24" 25 "Vol_Step25" 26 "Vol_Step26" 27 "Vol_Step27" 28 "Vol_Step28" 29 "Vol_Step29" 30 "Vol_Step30" 31 "NotUsed_1" ;
VAL_ 101 PrmptVolUpdtZone5_B_St 0 "NoUpdate" 1 "Update" ;
VAL_ 101 PrmptVolLvlZone5_D_St 0 "No_Volume" 1 "Vol_Step1" 2 "Vol_Step2" 3 "Vol_Step3" 4 "Vol_Step4" 5 "Vol_Step5" 6 "Vol_Step6" 7 "Vol_Step7" 8 "Vol_Step8" 9 "Vol_Step9" 10 "Vol_Step10" 11 "Vol_Step11" 12 "Vol_Step12" 13 "Vol_Step13" 14 "Vol_Step14" 15 "Vol_Step15" 16 "Vol_Step16" 17 "Vol_Step17" 18 "Vol_Step18" 19 "Vol_Step19" 20 "Vol_Step20" 21 "Vol_Step21" 22 "Vol_Step22" 23 "Vol_Step23" 24 "Vol_Step24" 25 "Vol_Step25" 26 "Vol_Step26" 27 "Vol_Step27" 28 "Vol_Step28" 29 "Vol_Step29" 30 "Vol_Step_30" 31 "NotUsed_1" ;
VAL_ 101 PrmptVolUpdtZone6_B_St 0 "NoUpdate" 1 "Update" ;
VAL_ 101 PrmptVolLvlZone6_D_St 0 "No_Volume" 1 "Vol_Step1" 2 "Vol_Step2" 3 "Vol_Step3" 4 "Vol_Step4" 5 "Vol_Step5" 6 "Vol_Step6" 7 "Vol_Step7" 8 "Vol_Step8" 9 "Vol_Step9" 10 "Vol_Step10" 11 "Vol_Step11" 12 "Vol_Step12" 13 "Vol_Step13" 14 "Vol_Step14" 15 "Vol_Step15" 16 "Vol_Step16" 17 "Vol_Step17" 18 "Vol_Step18" 19 "Vol_Step19" 20 "Vol_Step20" 21 "Vol_Step21" 22 "Vol_Step22" 23 "Vol_Step23" 24 "Vol_Step24" 25 "Vol_Step25" 26 "Vol_Step26" 27 "Vol_Step27" 28 "Vol_Step28" 29 "Vol_Step29" 30 "Vol_Step30" 31 "NotUsed_1" ;
VAL_ 102 CaptAnouncmnt_D_Rq 0 "Null" 1 "Activate" 2 "Cancel" 3 "NotUsed_1" ;
VAL_ 102 PhonRaVolUpdtZon1_B_St 0 "NoUpdate" 1 "Update" ;
VAL_ 102 PhonRaVolLvlZone1_D_St 0 "No_Volume" 1 "Vol_Step1" 2 "Vol_Step2" 3 "Vol_Step3" 4 "Vol_Step4" 5 "Vol_Step5" 6 "Vol_Step6" 7 "Vol_Step7" 8 "Vol_Step8" 9 "Vol_Step9" 10 "Vol_Step10" 11 "Vol_Step11" 12 "Vol_Step12" 13 "Vol_Step13" 14 "Vol_Step14" 15 "Vol_Step15" 16 "Vol_Step16" 17 "Vol_Step17" 18 "Vol_Step18" 19 "Vol_Step19" 20 "Vol_Step20" 21 "Vol_Step21" 22 "Vol_Step22" 23 "Vol_Step23" 24 "Vol_Step24" 25 "Vol_Step25" 26 "Vol_Step26" 27 "Vol_Step27" 28 "Vol_Step28" 29 "Vol_Step29" 30 "Vol_Step30" 31 "NotUsed_1" ;
VAL_ 102 PhonCallZone2_D_Stat 0 "Inactive" 1 "Privacy" 2 "Handsfree" 3 "NotUsed_1" ;
VAL_ 102 PhonRaVolUpdtZon2_B_St 0 "NoUpdate" 1 "Update" ;
VAL_ 102 PhonRaVolLvlZone2_D_St 0 "No_Volume" 1 "Vol_Step1" 2 "Vol_Step2" 3 "Vol_Step3" 4 "Vol_Step4" 5 "Vol_Step5" 6 "Vol_Step6" 7 "Vol_Step7" 8 "Vol_Step8" 9 "Vol_Step9" 10 "Vol_Step10" 11 "Vol_Step11" 12 "Vol_Step12" 13 "Vol_Step13" 14 "Vol_Step14" 15 "Vol_Step15" 16 "Vol_Step16" 17 "Vol_Step17" 18 "Vol_Step18" 19 "Vol_Step19" 20 "Vol_Step20" 21 "Vol_Step21" 22 "Vol_Step22" 23 "Vol_Step23" 24 "Vol_Step24" 25 "Vol_Step25" 26 "Vol_Step26" 27 "Vol_Step27" 28 "Vol_Step28" 29 "Vol_Step29" 30 "Vol_Step30" 31 "NotUsed_1" ;
VAL_ 102 PhonCallZone3_D_Stat 0 "Inactive" 1 "Privacy" 2 "Handsfree" 3 "CX3_NotUsed_1" ;
VAL_ 102 PhonRaVolUpdtZon3_B_St 0 "NoUpdate" 1 "Update" ;
VAL_ 102 PhonRaVolLvlZone3_D_St 0 "No_Volume" 1 "Vol_Step1" 2 "Vol_Step2" 3 "Vol_Step3" 4 "Vol_Step4" 5 "Vol_Step5" 6 "Vol_Step6" 7 "Vol_Step7" 8 "Vol_Step8" 9 "Vol_Step9" 10 "Vol_Step10" 11 "Vol_Step11" 12 "Vol_Step12" 13 "Vol_Step13" 14 "Vol_Step14" 15 "Vol_Step15" 16 "Vol_Step16" 17 "Vol_Step17" 18 "Vol_Step18" 19 "Vol_Step19" 20 "Vol_Step20" 21 "Vol_Step21" 22 "Vol_Step22" 23 "Vol_Step23" 24 "Vol_Step24" 25 "Vol_Step25" 26 "Vol_Step26" 27 "Vol_Step27" 28 "Vol_Step28" 29 "Vol_Step29" 30 "Vol_Step30" 31 "NotUsed_1" ;
VAL_ 102 PhonCallZone4_D_Stat 0 "Inactive" 1 "Privacy" 2 "Handsfree" 3 "NotUsed_1" ;
VAL_ 102 PhonRaVolUpdtZon4_B_St 0 "NoUpdate" 1 "Update" ;
VAL_ 102 PhonRaVolLvlZone4_D_St 0 "No_Volume" 1 "Vol_Step1" 2 "Vol_Step2" 3 "Vol_Step3" 4 "Vol_Step4" 5 "Vol_Step5" 6 "Vol_Step6" 7 "Vol_Step7" 8 "Vol_Step8" 9 "Vol_Step9" 10 "Vol_Step10" 11 "Vol_Step11" 12 "Vol_Step12" 13 "Vol_Step13" 14 "Vol_Step14" 15 "Vol_Step15" 16 "Vol_Step16" 17 "Vol_Step17" 18 "Vol_Step18" 19 "Vol_Step19" 20 "Vol_Step20" 21 "Vol_Step21" 22 "Vol_Step22" 23 "Vol_Step23" 24 "Vol_Step24" 25 "Vol_Step25" 26 "Vol_Step26" 27 "Vol_Step27" 28 "Vol_Step28" 29 "Vol_Step29" 30 "Vol_Step30" 31 "NotUsed_1" ;
VAL_ 102 PhonCallZone5_D_Stat 0 "Inactive" 1 "Privacy" 2 "Handsfree" 3 "NotUsed_1" ;
VAL_ 102 PhonRaVolUpdtZon5_B_St 0 "NoUpdate" 1 "Update" ;
VAL_ 102 PhonRaVolLvlZone5_D_St 0 "No_Volume" 1 "Vol_Step1" 2 "Vol_Step2" 3 "Vol_Step3" 4 "Vol_Step4" 5 "Vol_Step5" 6 "Vol_Step6" 7 "Vol_Step7" 8 "Vol_Step8" 9 "Vol_Step9" 10 "Vol_Step10" 11 "Vol_Step11" 12 "Vol_Step12" 13 "Vol_Step13" 14 "Vol_Step14" 15 "Vol_Step15" 16 "Vol_Step16" 17 "Vol_Step17" 18 "Vol_Step18" 19 "Vol_Step19" 20 "Vol_Step20" 21 "Vol_Step21" 22 "Vol_Step22" 23 "Vol_Step23" 24 "Vol_Step24" 25 "Vol_Step25" 26 "Vol_Step26" 27 "Vol_Step27" 28 "Vol_Step28" 29 "Vol_Step29" 30 "Vol_Step30" 31 "NotUsed_1" ;
VAL_ 102 PhonCallZone6_D_Stat 0 "Inactive" 1 "Privacy" 2 "Handsfree" 3 "NotUsed_1" ;
VAL_ 102 PhonRaVolUpdtZon6_B_St 0 "NoUpdate" 1 "Update" ;
VAL_ 102 PhonRaVolLvlZone6_D_St 0 "No_Volume" 1 "Vol_Step1" 2 "Vol_Step2" 3 "Vol_Step3" 4 "Vol_Step4" 5 "Vol_Step5" 6 "Vol_Step6" 7 "Vol_Step7" 8 "Vol_Step8" 9 "Vol_Step9" 10 "Vol_Step10" 11 "Vol_Step11" 12 "Vol_Step12" 13 "Vol_Step13" 14 "Vol_Step14" 15 "Vol_Step15" 16 "Vol_Step16" 17 "Vol_Step17" 18 "Vol_Step18" 19 "Vol_Step19" 20 "Vol_Step20" 21 "Vol_Step21" 22 "Vol_Step22" 23 "Vol_Step23" 24 "Vol_Step24" 25 "Vol_Step25" 26 "Vol_Step26" 27 "Vol_Step27" 28 "Vol_Step28" 29 "Vol_Step29" 30 "Vol_Step30" 31 "NotUsed_1" ;
VAL_ 102 ThemSel_D_Stat 0 "Null" 1 "ChangeWithDriveMode" 2 "Theme_1" 3 "Theme_2" 4 "Theme_3" 5 "Theme_4" 6 "Theme_5" 7 "Theme_6" 8 "Theme_7" 9 "Theme_8" 10 "Theme_9" 11 "Theme_10" 12 "Theme_11" 13 "Theme_12" 14 "Theme_13" 15 "Theme_14" ;
VAL_ 102 InCarComm_B_Rq 0 "Inactive" 1 "Active" ;
VAL_ 102 TvfSndShrt_D_Stat 0 "Inactive" 1 "NotAccepted" 2 "Accepted" 3 "NotUsed_1" ;
VAL_ 103 AuxAmpfy_D_Stat 0 "Null" 1 "NormalOperation" 2 "ErrorState_NoAudio" 3 "NotUsed" ;
VAL_ 103 RaSrcType_D_Stat 0 "Inactive" 1 "FM" 2 "DAB" 3 "NotUsed_1" ;
VAL_ 103 VehAudioMdeCtl_D_Stat 0 "Null" 1 "Cabin" 2 "Zone" 3 "NotUsed_1" ;
VAL_ 103 ActvNseMute_D_Stat2 0 "Inactive" 1 "NotMuted" 2 "Muted" 3 "NotUsed_1" ;
VAL_ 103 AudioCtlChnl1_D_Stat 0 "Null" 1 "NormalOperation" 2 "ErrorState_NoAudio" 3 "NotUsed" ;
VAL_ 103 RaActvType_D_Stat 0 "Inactive" 1 "TA" 2 "News" 3 "Alarm" 4 "Type_1" 5 "Type_2" 6 "Type_3" 7 "Type_4" 8 "Type_5" 9 "Type_6" 10 "Type_7" 11 "Type_8" 12 "Type_9" 13 "Type_10" 14 "Type_11" 15 "Type_12" 16 "Type_13" 17 "Type_14" 18 "Type_15" 19 "Type_16" 20 "NotUsed_1" 21 "NotUsed_2" 22 "NotUsed_3" 23 "NotUsed_4" 24 "NotUsed_5" 25 "NotUsed_6" 26 "NotUsed_7" 27 "NotUsed_8" 28 "NotUsed_9" 29 "NotUsed_10" 30 "NotUsed_11" 31 "NotUsed_12" ;
VAL_ 103 AudioCtlChnl2_D_Stat 0 "Null" 1 "Normaloperation" 2 "ErrorState_NoAudio" 3 "NotUsed" ;
VAL_ 103 AudioCtlChnl3_D_Stat 0 "Null" 1 "NormalOperation" 2 "ErrorState_NoAudio" 3 "NotUsed" ;
VAL_ 103 CabnMedVolCtl_D_Stat 0 "No_Volume" 1 "Vol_Step1" 2 "Vol_Step2" 3 "Vol_Step3" 4 "Vol_Step4" 5 "Vol_Step5" 6 "Vol_Step6" 7 "Vol_Step7" 8 "Vol_Step8" 9 "Vol_Step9" 10 "Vol_Step10" 11 "Vol_Step11" 12 "Vol_Step12" 13 "Vol_Step13" 14 "Vol_Step14" 15 "Vol_Step15" 16 "Vol_Step16" 17 "Vol_Step17" 18 "Vol_Step18" 19 "Vol_Step19" 20 "Vol_Step20" 21 "Vol_Step21" 22 "Vol_Step22" 23 "Vol_Step23" 24 "Vol_Step24" 25 "Vol_Step25" 26 "Vol_Step26" 27 "Vol_Step27" 28 "Vol_Step28" 29 "Vol_Step29" 30 "Vol_Step30" 31 "NotUsed_1" ;
VAL_ 103 AudioCtlChnl4_D_Stat 0 "Null" 1 "NormalOperation" 2 "ErrorState_NoAudio" 3 "NotUsed" ;
VAL_ 103 CabnRaVolCtl_D_Stat 0 "No_Volume" 1 "Vol_Step1" 2 "Vol_Step2" 3 "Vol_Step3" 4 "Vol_Step4" 5 "Vol_Step5" 6 "Vol_Step6" 7 "Vol_Step7" 8 "Vol_Step8" 9 "Vol_Step9" 10 "Vol_Step10" 11 "Vol_Step11" 12 "Vol_Step12" 13 "Vol_Step13" 14 "Vol_Step14" 15 "Vol_Step15" 16 "Vol_Step16" 17 "Vol_Step17" 18 "Vol_Step18" 19 "Vol_Step19" 20 "Vol_Step20" 21 "Vol_Step21" 22 "Vol_Step22" 23 "Vol_Step23" 24 "Vol_Step24" 25 "Vol_Step25" 26 "Vol_Step26" 27 "Vol_Step27" 28 "Vol_Step28" 29 "Vol_Step29" 30 "Vol_Step30" 31 "NotUsed_1" ;
VAL_ 103 AudioCtlChnl5_D_Stat 0 "Null" 1 "NormalOperation" 2 "ErrorState_NoAudio" 3 "NotUsed" ;
VAL_ 103 SpkrCnnctRear_D_Stat 0 "Inactive" 1 "NormalOperation" 2 "Faulted" 3 "NotUsed_1" ;
VAL_ 103 SpkrCnnctFront_D_Stat 0 "Inactive" 1 "NormalOperation" 2 "Faulted" 3 "NotUsed_1" ;
VAL_ 103 SpkrSel_B_Res 0 "External_Front" 1 "External_Rear" ;
VAL_ 103 AuxAmpfyChnl4_D_Stat 0 "Null" 1 "NormalOperation" 2 "ErrorState_NoAudio" 3 "NotUsed" ;
VAL_ 103 AuxAmpfyChnl3_D_Stat 0 "Null" 1 "NormalOperation" 2 "ErrorState_NoAudio" 3 "NotUsed" ;
VAL_ 103 AuxAmpfyChnl2_D_Stat 0 "Null" 1 "NormalOperation" 2 "ErrorState_NoAudio" 3 "NotUsed" ;
VAL_ 103 AuxAmpfyChnl1_D_Stat 0 "Null" 1 "NormalOperation" 2 "ErrorState_NoAudio" 3 "NotUsed" ;
VAL_ 103 SetCrntStation_D_Res 0 "Inactive" 1 "Invalid_Station" 2 "Valid_Station" 3 "NotUsed_1" ;
VAL_ 103 AudioCtlChnl8_D_Stat 0 "Null" 1 "NormalOperation" 2 "ErrorState_NoAudio" 3 "NotUsed" ;
VAL_ 103 AudioCtlChnl7_D_Stat 0 "Null" 1 "NormalOperation" 2 "ErrorState_NoAudio" 3 "NotUsed" ;
VAL_ 103 AudioCtlChnl6_D_Stat 0 "Null" 1 "NormalOperation" 2 "ErrorState_NoAudio" 3 "NotUsed" ;
VAL_ 104 MedVolCtlZone1_D_Stat 0 "No_Volume" 1 "Vol_Step1" 2 "Vol_Step2" 3 "Vol_Step3" 4 "Vol_Step4" 5 "Vol_Step5" 6 "Vol_Step6" 7 "Vol_Step7" 8 "Vol_Step8" 9 "Vol_Step9" 10 "Vol_Step10" 11 "Vol_Step11" 12 "Vol_Step12" 13 "Vol_Step13" 14 "Vol_Step14" 15 "Vol_Step15" 16 "Vol_Step16" 17 "Vol_Step17" 18 "Vol_Step18" 19 "Vol_Step19" 20 "Vol_Step20" 21 "Vol_Step21" 22 "Vol_Step22" 23 "Vol_Step23" 24 "Vol_Step24" 25 "Vol_Step25" 26 "Vol_Step26" 27 "Vol_Step27" 28 "Vol_Step28" 29 "Vol_Step29" 30 "Vol_Step30" 31 "NotUsed_1" ;
VAL_ 104 MedVolCtlZone2_D_Stat 0 "No_Volume" 1 "Vol_Step1" 2 "Vol_Step2" 3 "Vol_Step3" 4 "Vol_Step4" 5 "Vol_Step5" 6 "Vol_Step6" 7 "Vol_Step7" 8 "Vol_Step8" 9 "Vol_Step9" 10 "Vol_Step10" 11 "Vol_Step11" 12 "Vol_Step12" 13 "Vol_Step13" 14 "Vol_Step14" 15 "Vol_Step15" 16 "Vol_Step16" 17 "Vol_Step17" 18 "Vol_Step18" 19 "Vol_Step19" 20 "Vol_Step20" 21 "Vol_Step21" 22 "Vol_Step22" 23 "Vol_Step23" 24 "Vol_Step24" 25 "Vol_Step25" 26 "Vol_Step26" 27 "Vol_Step27" 28 "Vol_Step28" 29 "Vol_Step29" 30 "Vol_Step30" 31 "NotUsed_1" ;
VAL_ 104 MedVolCtlZone3_D_Stat 0 "No_Volume" 1 "Vol_Step1" 2 "Vol_Step2" 3 "Vol_Step3" 4 "Vol_Step4" 5 "Vol_Step5" 6 "Vol_Step6" 7 "Vol_Step7" 8 "Vol_Step8" 9 "Vol_Step9" 10 "Vol_Step10" 11 "Vol_Step11" 12 "Vol_Step12" 13 "Vol_Step13" 14 "Vol_Step14" 15 "Vol_Step15" 16 "Vol_Step16" 17 "Vol_Step17" 18 "Vol_Step18" 19 "Vol_Step19" 20 "Vol_Step20" 21 "Vol_Step21" 22 "Vol_Step22" 23 "Vol_Step23" 24 "Vol_Step24" 25 "Vol_Step25" 26 "Vol_Step26" 27 "Vol_Step27" 28 "Vol_Step28" 29 "Vol_Step29" 30 "Vol_Step30" 31 "NotUsed_1" ;
VAL_ 104 MedVolCtlZone4_D_Stat 0 "No_Volume" 1 "Vol_Step1" 2 "Vol_Step2" 3 "Vol_Step3" 4 "Vol_Step4" 5 "Vol_Step5" 6 "Vol_Step6" 7 "Vol_Step7" 8 "Vol_Step8" 9 "Vol_Step9" 10 "Vol_Step10" 11 "Vol_Step11" 12 "Vol_Step12" 13 "Vol_Step13" 14 "Vol_Step14" 15 "Vol_Step15" 16 "Vol_Step16" 17 "Vol_Step17" 18 "Vol_Step18" 19 "Vol_Step19" 20 "Vol_Step20" 21 "Vol_Step21" 22 "Vol_Step22" 23 "Vol_Step23" 24 "Vol_Step24" 25 "Vol_Step25" 26 "Vol_Step26" 27 "Vol_Step27" 28 "Vol_Step28" 29 "Vol_Step29" 30 "Vol_Step30" 31 "NotUsed_1" ;
VAL_ 104 MedVolCtlZone5_D_Stat 0 "No_Volume" 1 "Vol_Step1" 2 "Vol_Step2" 3 "Vol_Step3" 4 "Vol_Step4" 5 "Vol_Step5" 6 "Vol_Step6" 7 "Vol_Step7" 8 "Vol_Step8" 9 "Vol_Step9" 10 "Vol_Step10" 11 "Vol_Step11" 12 "Vol_Step12" 13 "Vol_Step13" 14 "Vol_Step14" 15 "Vol_Step15" 16 "Vol_Step16" 17 "Vol_Step17" 18 "Vol_Step18" 19 "Vol_Step19" 20 "Vol_Step20" 21 "Vol_Step21" 22 "Vol_Step22" 23 "Vol_Step23" 24 "Vol_Step24" 25 "Vol_Step25" 26 "Vol_Step26" 27 "Vol_Step27" 28 "Vol_Step28" 29 "Vol_Step29" 30 "Vol_Step30" 31 "NotUsed_1" ;
VAL_ 104 MedVolCtlZone6_D_Stat 0 "No_Volume" 1 "Vol_Step1" 2 "Vol_Step2" 3 "Vol_Step3" 4 "Vol_Step4" 5 "Vol_Step5" 6 "Vol_Step6" 7 "Vol_Step7" 8 "Vol_Step8" 9 "Vol_Step9" 10 "Vol_Step10" 11 "Vol_Step11" 12 "Vol_Step12" 13 "Vol_Step13" 14 "Vol_Step14" 15 "Vol_Step15" 16 "Vol_Step16" 17 "Vol_Step17" 18 "Vol_Step18" 19 "Vol_Step19" 20 "Vol_Step20" 21 "Vol_Step21" 22 "Vol_Step22" 23 "Vol_Step23" 24 "Vol_Step24" 25 "Vol_Step25" 26 "Vol_Step26" 27 "Vol_Step27" 28 "Vol_Step28" 29 "Vol_Step29" 30 "Vol_Step30" 31 "NotUsed_1" ;
VAL_ 105 PhonCallZone6_D_Rq 0 "Call_Inactive_NoCall" 1 "CallRinging" 2 "Cx2CallActive" 3 "NotUsed_1" ;
VAL_ 105 PhonRaVolCtlZone1_D_St 0 "No_Volume" 1 "Vol_Step1" 2 "Vol_Step2" 3 "Vol_Step3" 4 "Vol_Step4" 5 "Vol_Step5" 6 "Vol_Step6" 7 "Vol_Step7" 8 "Vol_Step8" 9 "Vol_Step9" 10 "Vol_Step10" 11 "Vol_Step11" 12 "Vol_Step12" 13 "Vol_Step13" 14 "Vol_Step14" 15 "Vol_Step15" 16 "Vol_Step16" 17 "Vol_Step17" 18 "Vol_Step18" 19 "Vol_Step19" 20 "Vol_Step20" 21 "Vol_Step21" 22 "Vol_Step22" 23 "Vol_Step23" 24 "Vol_Step24" 25 "Vol_Step25" 26 "Vol_Step26" 27 "Vol_Step27" 28 "Vol_Step28" 29 "Vol_Step29" 30 "Vol_Step30" 31 "NotUsed_1" ;
VAL_ 105 PhonCallZone5_D_Rq 0 "Call_Inactive_NoCall" 1 "CallRinging" 2 "Cx2CallActive" 3 "NotUsed_1" ;
VAL_ 105 PhonRaVolCtlZone2_D_St 0 "No_Volume" 1 "Vol_Step1" 2 "Vol_Step2" 3 "Vol_Step3" 4 "Vol_Step4" 5 "Vol_Step5" 6 "Vol_Step6" 7 "Vol_Step7" 8 "Vol_Step8" 9 "Vol_Step9" 10 "Vol_Step10" 11 "Vol_Step11" 12 "Vol_Step12" 13 "Vol_Step13" 14 "Vol_Step14" 15 "Vol_Step15" 16 "Vol_Step16" 17 "Vol_Step17" 18 "Vol_Step18" 19 "Vol_Step19" 20 "Vol_Step20" 21 "Vol_Step21" 22 "Vol_Step22" 23 "Vol_Step23" 24 "Vol_Step24" 25 "Vol_Step25" 26 "Vol_Step26" 27 "Vol_Step27" 28 "Vol_Step28" 29 "Vol_Step29" 30 "Vol_Step30" 31 "NotUsed_1" ;
VAL_ 105 PhonCallZone4_D_Rq 0 "Call_Inactive_NoCall" 1 "CallRinging" 2 "Cx2CallActive" 3 "NotUsed_1" ;
VAL_ 105 PhonRaVolCtlZone3_D_St 0 "No_Volume" 1 "Vol_Step1" 2 "Vol_Step2" 3 "Vol_Step3" 4 "Vol_Step4" 5 "Vol_Step5" 6 "Vol_Step6" 7 "Vol_Step7" 8 "Vol_Step8" 9 "Vol_Step9" 10 "Vol_Step10" 11 "Vol_Step11" 12 "Vol_Step12" 13 "Vol_Step13" 14 "Vol_Step14" 15 "Vol_Step15" 16 "Vol_Step16" 17 "Vol_Step17" 18 "Vol_Step18" 19 "Vol_Step19" 20 "Vol_Step20" 21 "Vol_Step21" 22 "Vol_Step22" 23 "Vol_Step23" 24 "Vol_Step24" 25 "Vol_Step25" 26 "Vol_Step26" 27 "Vol_Step27" 28 "Vol_Step28" 29 "Vol_Step29" 30 "Vol_Step30" 31 "NotUsed_1" ;
VAL_ 105 InCarComm_D_Stat 0 "Inactive" 1 "Active" 2 "TemporarilyDisabled" 3 "NotUsed_1" ;
VAL_ 105 PhonRaVolCtlZone4_D_St 0 "No_Volume" 1 "Vol_Step1" 2 "Vol_Step2" 3 "Vol_Step3" 4 "Vol_Step4" 5 "Vol_Step5" 6 "Vol_Step6" 7 "Vol_Step7" 8 "Vol_Step8" 9 "Vol_Step9" 10 "Vol_Step10" 11 "Vol_Step11" 12 "Vol_Step12" 13 "Vol_Step13" 14 "Vol_Step14" 15 "Vol_Step15" 16 "Vol_Step16" 17 "Vol_Step17" 18 "Vol_Step18" 19 "Vol_Step19" 20 "Vol_Step20" 21 "Vol_Step21" 22 "Vol_Step22" 23 "Vol_Step23" 24 "Vol_Step24" 25 "Vol_Step25" 26 "Vol_Step26" 27 "Vol_Step27" 28 "Vol_Step28" 29 "Vol_Step29" 30 "Vol_Step30" 31 "NotUsed_1" ;
VAL_ 105 CaptAnouncmnt_D_Stat 0 "Inactive" 1 "Active" 2 "Disabled" 3 "NotUsed_1" ;
VAL_ 105 PhonRaVolCtlZone5_D_St 0 "No_Volume" 1 "Vol_Step1" 2 "Vol_Step2" 3 "Vol_Step3" 4 "Vol_Step4" 5 "Vol_Step5" 6 "Vol_Step6" 7 "Vol_Step7" 8 "Vol_Step8" 9 "Vol_Step9" 10 "Vol_Step10" 11 "Vol_Step11" 12 "Vol_Step12" 13 "Vol_Step13" 14 "Vol_Step14" 15 "Vol_Step15" 16 "Vol_Step16" 17 "Vol_Step17" 18 "Vol_Step18" 19 "Vol_Step19" 20 "Vol_Step20" 21 "Vol_Step21" 22 "Vol_Step22" 23 "Vol_Step23" 24 "Vol_Step24" 25 "Vol_Step25" 26 "Vol_Step26" 27 "Vol_Step27" 28 "Vol_Step28" 29 "Vol_Step29" 30 "Vol_Step30" 31 "NotUsed_1" ;
VAL_ 105 PhonCallZone2_D_Rq 0 "Call_Inactive_NoCall" 1 "CallRinging" 2 "Cx2CallActive" 3 "NotUsed_1" ;
VAL_ 105 PhonRaVolCtlZone6_D_St 0 "No_Volume" 1 "Vol_Step1" 2 "Vol_Step2" 3 "Vol_Step3" 4 "Vol_Step4" 5 "Vol_Step5" 6 "Vol_Step6" 7 "Vol_Step7" 8 "Vol_Step8" 9 "Vol_Step9" 10 "Vol_Step10" 11 "Vol_Step11" 12 "Vol_Step12" 13 "Vol_Step13" 14 "Vol_Step14" 15 "Vol_Step15" 16 "Vol_Step16" 17 "Vol_Step17" 18 "Vol_Step18" 19 "Vol_Step19" 20 "Vol_Step20" 21 "Vol_Step21" 22 "Vol_Step22" 23 "Vol_Step23" 24 "Vol_Step24" 25 "Vol_Step25" 26 "Vol_Step26" 27 "Vol_Step27" 28 "Vol_Step28" 29 "Vol_Step29" 30 "Vol_Step30" 31 "NotUsed_1" ;
VAL_ 105 PhonCallZone3_D_Rq 0 "Call_Inactive_NoCall" 1 "CallRinging" 2 "Cx2CallActive" 3 "NotUsed_1" ;
VAL_ 106 MedVolCtlZone1_D_Stat2 0 "No_Volume" 1 "Vol_Step1" 2 "Vol_Step2" 3 "Vol_Step3" 4 "Vol_Step4" 5 "Vol_Step5" 6 "Vol_Step6" 7 "Vol_Step7" 8 "Vol_Step8" 9 "Vol_Step9" 10 "Vol_Step10" 11 "Vol_Step11" 12 "Vol_Step12" 13 "Vol_Step13" 14 "Vol_Step14" 15 "Vol_Step15" 16 "Vol_Step16" 17 "Vol_Step17" 18 "Vol_Step18" 19 "Vol_Step19" 20 "Vol_Step20" 21 "Vol_Step21" 22 "Vol_Step22" 23 "Vol_Step23" 24 "Vol_Step24" 25 "Vol_Step25" 26 "Vol_Step26" 27 "Vol_Step27" 28 "Vol_Step28" 29 "Vol_Step29" 30 "Vol_Step30" 31 "NotUsed_1" ;
VAL_ 106 MedVolCtlZone2_D_Stat2 0 "No_Volume" 1 "Vol_Step1" 2 "Vol_Step2" 3 "Vol_Step3" 4 "Vol_Step4" 5 "Vol_Step5" 6 "Vol_Step6" 7 "Vol_Step7" 8 "Vol_Step8" 9 "Vol_Step9" 10 "Vol_Step10" 11 "Vol_Step11" 12 "Vol_Step12" 13 "Vol_Step13" 14 "Vol_Step14" 15 "Vol_Step15" 16 "Vol_Step16" 17 "Vol_Step17" 18 "Vol_Step18" 19 "Vol_Step19" 20 "Vol_Step20" 21 "Vol_Step21" 22 "Vol_Step22" 23 "Vol_Step23" 24 "Vol_Step24" 25 "Vol_Step25" 26 "Vol_Step26" 27 "Vol_Step27" 28 "Vol_Step28" 29 "Vol_Step29" 30 "Vol_Step30" 31 "NotUsed_1" ;
VAL_ 106 MedVolCtlZone3_D_Stat2 0 "No_Volume" 1 "Vol_Step1" 2 "Vol_Step2" 3 "Vol_Step3" 4 "Vol_Step4" 5 "Vol_Step5" 6 "Vol_Step6" 7 "Vol_Step7" 8 "Vol_Step8" 9 "Vol_Step9" 10 "Vol_Step10" 11 "Vol_Step11" 12 "Vol_Step12" 13 "Vol_Step13" 14 "Vol_Step14" 15 "Vol_Step15" 16 "Vol_Step16" 17 "Vol_Step17" 18 "Vol_Step18" 19 "Vol_Step19" 20 "Vol_Step20" 21 "Vol_Step21" 22 "Vol_Step22" 23 "Vol_Step23" 24 "Vol_Step24" 25 "Vol_Step25" 26 "Vol_Step26" 27 "Vol_Step27" 28 "Vol_Step28" 29 "Vol_Step29" 30 "Vol_Step30" 31 "NotUsed_1" ;
VAL_ 106 MedVolCtlZone4_D_Stat2 0 "No_Volume" 1 "Vol_Step1" 2 "Vol_Step2" 3 "Vol_Step3" 4 "Vol_Step4" 5 "Vol_Step5" 6 "Vol_Step6" 7 "Vol_Step7" 8 "Vol_Step8" 9 "Vol_Step9" 10 "Vol_Step10" 11 "Vol_Step11" 12 "Vol_Step12" 13 "Vol_Step13" 14 "Vol_Step14" 15 "Vol_Step15" 16 "Vol_Step16" 17 "Vol_Step17" 18 "Vol_Step18" 19 "Vol_Step19" 20 "Vol_Step20" 21 "Vol_Step21" 22 "Vol_Step22" 23 "Vol_Step23" 24 "Vol_Step24" 25 "Vol_Step25" 26 "Vol_Step26" 27 "Vol_Step27" 28 "Vol_Step28" 29 "Vol_Step29" 30 "Vol_Step30" 31 "NotUsed_1" ;
VAL_ 106 MedVolCtlZone5_D_Stat2 0 "No_Volume" 1 "Vol_Step1" 2 "Vol_Step2" 3 "Vol_Step3" 4 "Vol_Step4" 5 "Vol_Step5" 6 "Vol_Step6" 7 "Vol_Step7" 8 "Vol_Step8" 9 "Vol_Step9" 10 "Vol_Step10" 11 "Vol_Step11" 12 "Vol_Step12" 13 "Vol_Step13" 14 "Vol_Step14" 15 "Vol_Step15" 16 "Vol_Step16" 17 "Vol_Step17" 18 "Vol_Step18" 19 "Vol_Step19" 20 "Vol_Step20" 21 "Vol_Step21" 22 "Vol_Step22" 23 "Vol_Step23" 24 "Vol_Step24" 25 "Vol_Step25" 26 "Vol_Step26" 27 "Vol_Step27" 28 "Vol_Step28" 29 "Vol_Step29" 30 "Vol_Step30" 31 "NotUsed_1" ;
VAL_ 106 MedVolCtlZone6_D_Stat2 0 "No_Volume" 1 "Vol_Step1" 2 "Vol_Step2" 3 "Vol_Step3" 4 "Vol_Step4" 5 "Vol_Step5" 6 "Vol_Step6" 7 "Vol_Step7" 8 "Vol_Step8" 9 "Vol_Step9" 10 "Vol_Step10" 11 "Vol_Step11" 12 "Vol_Step12" 13 "Vol_Step13" 14 "Vol_Step14" 15 "Vol_Step15" 16 "Vol_Step16" 17 "Vol_Step17" 18 "Vol_Step18" 19 "Vol_Step19" 20 "Vol_Step20" 21 "Vol_Step21" 22 "Vol_Step22" 23 "Vol_Step23" 24 "Vol_Step24" 25 "Vol_Step25" 26 "Vol_Step26" 27 "Vol_Step27" 28 "Vol_Step28" 29 "Vol_Step29" 30 "Vol_Step30" 31 "NotUsed_1" ;
VAL_ 106 VehAudioMdeCtl_D_Stat2 0 "Null" 1 "Cabin" 2 "Zone" 3 "NotUsed_1" ;
VAL_ 106 CabnMedVolCtl_D_Stat2 0 "No_Volume" 1 "Vol_Step1" 2 "Vol_Step2" 3 "Vol_Step3" 4 "Vol_Step4" 5 "Vol_Step5" 6 "Vol_Step6" 7 "Vol_Step7" 8 "Vol_Step8" 9 "Vol_Step9" 10 "Vol_Step10" 11 "Vol_Step11" 12 "Vol_Step12" 13 "Vol_Step13" 14 "Vol_Step14" 15 "Vol_Step15" 16 "Vol_Step16" 17 "Vol_Step17" 18 "Vol_Step18" 19 "Vol_Step19" 20 "Vol_Step20" 21 "Vol_Step21" 22 "Vol_Step22" 23 "Vol_Step23" 24 "Vol_Step24" 25 "Vol_Step25" 26 "Vol_Step26" 27 "Vol_Step27" 28 "Vol_Step28" 29 "Vol_Step29" 30 "Vol_Step30" 31 "NotUsed_1" ;
VAL_ 106 InfotainmentAudio_St2 0 "Null" 1 "NormalOperation" 2 "ErrorState_NoAudio" 3 "NotUsed" ;
VAL_ 106 CabnRaVolCtl_D_Stat2 0 "No_Volume" 1 "Vol_Step1" 2 "Vol_Step2" 3 "Vol_Step3" 4 "Vol_Step4" 5 "Vol_Step5" 6 "Vol_Step6" 7 "Vol_Step7" 8 "Vol_Step8" 9 "Vol_Step9" 10 "Vol_Step10" 11 "Vol_Step11" 12 "Vol_Step12" 13 "Vol_Step13" 14 "Vol_Step14" 15 "Vol_Step15" 16 "Vol_Step16" 17 "Vol_Step17" 18 "Vol_Step18" 19 "Vol_Step19" 20 "Vol_Step20" 21 "Vol_Step21" 22 "Vol_Step22" 23 "Vol_Step23" 24 "Vol_Step24" 25 "Vol_Step25" 26 "Vol_Step26" 27 "Vol_Step27" 28 "Vol_Step28" 29 "Vol_Step29" 30 "Vol_Step30" 31 "NotUsed_" ;
VAL_ 107 PhonRaVolCtlZon1_D_St2 0 "No_Volume" 1 "Vol_Step1" 2 "Vol_Step2" 3 "Vol_Step3" 4 "Vol_Step4" 5 "Vol_Step5" 6 "Vol_Step6" 7 "Vol_Step7" 8 "Vol_Step8" 9 "Vol_Step9" 10 "Vol_Step10" 11 "Vol_Step11" 12 "Vol_Step12" 13 "Vol_Step13" 14 "Vol_Step14" 15 "Vol_Step15" 16 "Vol_Step16" 17 "Vol_Step17" 18 "Vol_Step18" 19 "Vol_Step19" 20 "Vol_Step20" 21 "Vol_Step21" 22 "Vol_Step22" 23 "Vol_Step23" 24 "Vol_Step24" 25 "Vol_Step25" 26 "Vol_Step26" 27 "Vol_Step27" 28 "Vol_Step28" 29 "Vol_Step29" 30 "Vol_Step30" 31 "NotUsed_1" ;
VAL_ 107 PhonRaVolCtlZon2_D_St2 0 "No_Volume" 1 "Vol_Step1" 2 "Vol_Step2" 3 "Vol_Step3" 4 "Vol_Step4" 5 "Vol_Step5" 6 "Vol_Step6" 7 "Vol_Step7" 8 "Vol_Step8" 9 "Vol_Step9" 10 "Vol_Step10" 11 "Vol_Step11" 12 "Vol_Step12" 13 "Vol_Step13" 14 "Vol_Step14" 15 "Vol_Step15" 16 "Vol_Step16" 17 "Vol_Step17" 18 "Vol_Step18" 19 "Vol_Step19" 20 "Vol_Step20" 21 "Vol_Step21" 22 "Vol_Step22" 23 "Vol_Step23" 24 "Vol_Step24" 25 "Vol_Step25" 26 "Vol_Step26" 27 "Vol_Step27" 28 "Vol_Step28" 29 "Vol_Step29" 30 "Vol_Step30" 31 "NotUsed_1" ;
VAL_ 107 PhonRaVolCtlZon3_D_St2 0 "No_Volume" 1 "Vol_Step1" 2 "Vol_Step2" 3 "Vol_Step3" 4 "Vol_Step4" 5 "Vol_Step5" 6 "Vol_Step6" 7 "Vol_Step7" 8 "Vol_Step8" 9 "Vol_Step9" 10 "Vol_Step10" 11 "Vol_Step11" 12 "Vol_Step12" 13 "Vol_Step13" 14 "Vol_Step14" 15 "Vol_Step15" 16 "Vol_Step16" 17 "Vol_Step17" 18 "Vol_Step18" 19 "Vol_Step19" 20 "Vol_Step20" 21 "Vol_Step21" 22 "Vol_Step22" 23 "Vol_Step23" 24 "Vol_Step24" 25 "Vol_Step25" 26 "Vol_Step26" 27 "Vol_Step27" 28 "Vol_Step28" 29 "Vol_Step29" 30 "Vol_Step30" 31 "NotUsed_1" ;
VAL_ 107 PhonRaVolCtlZon4_D_St2 0 "No_Volume" 1 "Vol_Step1" 2 "Vol_Step2" 3 "Vol_Step3" 4 "Vol_Step4" 5 "Vol_Step5" 6 "Vol_Step6" 7 "Vol_Step7" 8 "Vol_Step8" 9 "Vol_Step9" 10 "Vol_Step10" 11 "Vol_Step11" 12 "Vol_Step12" 13 "Vol_Step13" 14 "Vol_Step14" 15 "Vol_Step15" 16 "Vol_Step16" 17 "Vol_Step17" 18 "Vol_Step18" 19 "Vol_Step19" 20 "Vol_Step20" 21 "Vol_Step21" 22 "Vol_Step22" 23 "Vol_Step23" 24 "Vol_Step24" 25 "Vol_Step25" 26 "Vol_Step26" 27 "Vol_Step27" 28 "Vol_Step28" 29 "Vol_Step29" 30 "Vol_Step30" 31 "NotUsed_1" ;
VAL_ 107 PhonRaVolCtlZon5_D_St2 0 "No_Volume" 1 "Vol_Step1" 2 "Vol_Step2" 3 "Vol_Step3" 4 "Vol_Step4" 5 "Vol_Step5" 6 "Vol_Step6" 7 "Vol_Step7" 8 "Vol_Step8" 9 "Vol_Step9" 10 "Vol_Step10" 11 "Vol_Step11" 12 "Vol_Step12" 13 "Vol_Step13" 14 "Vol_Step14" 15 "Vol_Step15" 16 "Vol_Step16" 17 "Vol_Step17" 18 "Vol_Step18" 19 "Vol_Step19" 20 "Vol_Step20" 21 "Vol_Step21" 22 "Vol_Step22" 23 "Vol_Step23" 24 "Vol_Step24" 25 "Vol_Step25" 26 "Vol_Step26" 27 "Vol_Step27" 28 "Vol_Step28" 29 "Vol_Step29" 30 "Vol_Step30" 31 "NotUsed_1" ;
VAL_ 107 PhonRaVolCtlZon6_D_St2 0 "No_Volume" 1 "Vol_Step1" 2 "Vol_Step2" 3 "Vol_Step3" 4 "Vol_Step4" 5 "Vol_Step5" 6 "Vol_Step6" 7 "Vol_Step7" 8 "Vol_Step8" 9 "Vol_Step9" 10 "Vol_Step10" 11 "Vol_Step11" 12 "Vol_Step12" 13 "Vol_Step13" 14 "Vol_Step14" 15 "Vol_Step15" 16 "Vol_Step16" 17 "Vol_Step17" 18 "Vol_Step18" 19 "Vol_Step19" 20 "Vol_Step20" 21 "Vol_Step21" 22 "Vol_Step22" 23 "Vol_Step23" 24 "Vol_Step24" 25 "Vol_Step25" 26 "Vol_Step26" 27 "Vol_Step27" 28 "Vol_Step28" 29 "Vol_Step29" 30 "Vol_Step30" 31 "NotUsed_1" ;
VAL_ 109 SetCrntStationOpr_D_Rq 0 "Inactive" 1 "Frequency_BlockID" 2 "Frequency_PICode" 3 "BlockID_SID_ECC" 4 "Frequency_MCChannel" 5 "NotUsed_1" 6 "NotUsed_2" 7 "NotUsed_3" ;
VAL_ 109 SetCrntStationMde_D_Rq 0 "Inactive" 1 "AM_AMHD" 2 "FM_FMHD" 3 "DAB" ;
VAL_ 109 SetCrntStnMcChnl_D_Rq 0 "Inactive" 1 "MCChannel1" 2 "MCChannel2" 3 "MCChannel3" 4 "MCChannel4" 5 "MCChannel5" 6 "MCChannel6" 7 "MCChannel7" ;
VAL_ 110 AudioAmpfyChnl4_D_Stat 0 "Null" 1 "NormalOperation" 2 "ErrorState_NoAudio" 3 "NotUsed" ;
VAL_ 110 AudioAmpfyChnl3_D_Stat 0 "Null" 1 "NormalOperation" 2 "ErrorState_NoAudio" 3 "NotUsed" ;
VAL_ 110 AudioAmpfyChnl2_D_Stat 0 "Null" 1 "NormalOperation" 2 "ErrorState_NoAudio" 3 "NotUsed" ;
VAL_ 110 AudioAmpfyChnl1_D_Stat 0 "Null" 1 "NormalOperation" 2 "ErrorState_NoAudio" 3 "NotUsed" ;
VAL_ 110 AudioAmpfyChnl8_D_Stat 0 "Null" 1 "NormalOperation" 2 "ErrorState_NoAudio" 3 "NotUsed" ;
VAL_ 110 AudioAmpfyChnl7_D_Stat 0 "Null" 1 "NormalOperation" 2 "ErrorState_NoAudio" 3 "NotUsed" ;
VAL_ 110 AudioAmpfyChnl6_D_Stat 0 "Null" 1 "NormalOperation" 2 "ErrorState_NoAudio" 3 "NotUsed" ;
VAL_ 110 AudioAmpfyChnl5_D_Stat 0 "Null" 1 "NormalOperation" 2 "ErrorState_NoAudio" 3 "NotUsed" ;
VAL_ 110 AudioAmpfyChnl12_D_St 0 "Null" 1 "NormalOperation" 2 "ErrorState_NoAudio" 3 "NotUsed" ;
VAL_ 110 AudioAmpfyChnl11_D_St 0 "Null" 1 "NormalOperation" 2 "ErrorState_NoAudio" 3 "NotUsed" ;
VAL_ 110 AudioAmpfyChnl10_D_St 0 "Null" 1 "NormalOperation" 2 "ErrorState_NoAudio" 3 "NotUsed" ;
VAL_ 110 AudioAmpfyChnl9_D_Stat 0 "Null" 1 "NormalOperation" 2 "ErrorState_NoAudio" 3 "NotUsed" ;
VAL_ 110 AudioAmpfyChnl16_D_St 0 "Null" 1 "NormalOperation" 2 "ErrorState_NoAudio" 3 "NotUsed" ;
VAL_ 110 AudioAmpfyChnl15_D_St 0 "Null" 1 "NormalOperation" 2 "ErrorState_NoAudio" 3 "NotUsed" ;
VAL_ 110 AudioAmpfyChnl14_D_St 0 "Null" 1 "NormalOperation" 2 "ErrorState_NoAudio" 3 "NotUsed" ;
VAL_ 110 AudioAmpfyChnl13_D_St 0 "Null" 1 "NormalOperation" 2 "ErrorState_NoAudio" 3 "NotUsed" ;
VAL_ 110 AudioAmpfyChnl20_D_St 0 "Null" 1 "NormalOperation" 2 "ErrorState_NoAudio" 3 "NotUsed" ;
VAL_ 110 AudioAmpfyChnl19_D_St 0 "Null" 1 "NormalOperation" 2 "ErrorState_NoAudio" 3 "NotUsed" ;
VAL_ 110 AudioAmpfyChnl18_D_St 0 "Null" 1 "NormalOperation" 2 "ErrorState_NoAudio" 3 "NotUsed" ;
VAL_ 110 AudioAmpfyChnl17_D_St 0 "Null" 1 "NormalOperation" 2 "ErrorState_NoAudio" 3 "NotUsed" ;
VAL_ 110 AudioAmpfyChnl24_D_St 0 "Null" 1 "NormalOperation" 2 "ErrorState_NoAudio" 3 "NotUsed" ;
VAL_ 110 AudioAmpfyChnl23_D_St 0 "Null" 1 "NormalOperation" 2 "ErrorState_NoAudio" 3 "NotUsed" ;
VAL_ 110 AudioAmpfyChnl22_D_St 0 "Null" 1 "NormalOperation" 2 "ErrorState_NoAudio" 3 "NotUsed" ;
VAL_ 110 AudioAmpfyChnl21_D_St 0 "Null" 1 "NormalOperation" 2 "ErrorState_NoAudio" 3 "NotUsed" ;
VAL_ 112 SeatLatcWarnR2Psn_D_Rq2 0 "Inactive" 1 "Warning_1" 2 "Warning_2" 3 "Warning_3" ;
VAL_ 112 SeatLatcWarnR2Drv_D_Rq2 0 "Inactive" 1 "Warning_1" 2 "Warning_2" 3 "Warning_3" ;
VAL_ 117 DrvSlipCtlLamp_D_Rq_EF 0 "Off" 1 "On" 2 "Slow Flash" 3 "Fast Flash" ;
VAL_ 117 DrvAntiLckLamp_D_Rq_EF 0 "Off" 1 "On" 2 "Slow Flash" 3 "Fast Flash" ;
VAL_ 117 BrkLamp_B_Rq_EF 0 "No" 1 "Yes" ;
VAL_ 117 PrkBrkYwLamp_D_Rq_EF 0 "Off" 1 "On" 2 "Slow Flash" 3 "Fast Flash" ;
VAL_ 117 PrkBrkRedLamp_D_Rq_EF 0 "Off" 1 "On" 2 "Slow Flash" 3 "Fast Flash" ;
VAL_ 117 DrvSlipCtlOffLamp_D_Rq_EF 0 "Off" 1 "On" 2 "Slow Flash" 3 "Fast Flash" ;
VAL_ 118 StopLamp_B_RqBrk 0 "Inactive" 1 "Active" ;
VAL_ 118 DrvSte_D_Stat 0 "DSR_Deactivated" 1 "DSR_Request_Not_Applicable" 2 "EPAS_Comm_Disturbed" 3 "DSR_in_Normal_Idle_Mode" 4 "Ignition_Off" 5 "Request_Active" 6 "NotUsed1" 7 "NotUsed2" 8 "NotUsed3" 9 "NotUsed4" 10 "NotUsed5" 11 "NotUsed6" 12 "NotUsed7" 13 "NotUsed8" 14 "NotUsed9" 15 "NotUsed10" ;
VAL_ 118 EmgcyBrkLamp_D_Rq 0 "Inactive" 1 "Active_at_speed" 2 "Active_at_standstill" 3 "NotUsed" ;
VAL_ 118 SteWhlCompAnEst_D_Qf 0 "Faulty" 1 "No_Data_Exists" 2 "Not_Within_Specifications" 3 "OK" ;
VAL_ 118 DrvSte_Tq_Rq 254 "Unknown" 255 "Invalid" ;
VAL_ 118 BrkTerrMde_D_Actl 0 "Special_Operating_Mode_Off" 1 "Low_Mu_Mode" 2 "Undefined" 3 "Sand_Mode" 4 "Mud_Ruts_Mode" 5 "Rock_Crawl_Mode" 6 "Dynamic_Mode" 7 "Fail_Safe_Default" ;
VAL_ 118 BrkCtrFnd_B_Stat 0 "No" 1 "Yes" ;
VAL_ 118 BrkTerrMdeChng_D_Rdy 0 "Mode_Change_Available" 1 "Module_In_Initialization" 2 "ModeUnavailDynamicCond" 3 "SpOpModes_NotSupported" 4 "ModeUnavailDrInputRqd" 5 "Undefined_1" 6 "Undefined_2" 7 "Fault" ;
VAL_ 124 VehOverGnd_V_Est 65534 "Unknown" 65535 "Invalid" ;
VAL_ 124 VehYawComp_W_Actl 4094 "NoDataExists" 4095 "Fault" ;
VAL_ 124 VehTrvlDir_D_Stat 0 "LikelyForward" 1 "Forward" 2 "LikelyReverse" 3 "Reverse" 4 "NotUsed1" 5 "NotUsed2" 6 "NoDataExists" 7 "Faulty" ;
VAL_ 124 VehLatComp_A_Actl 1022 "NoDataExists" 1023 "Fault" ;
VAL_ 124 VehLongComp_A_Actl 1022 "NoDataExists" 1023 "Fault" ;
VAL_ 125 BrkTot_Tq_RqArb 8190 "Unknown" 8191 "Fault" ;
VAL_ 125 HsaStat_D_Actl 0 "Inactive" 1 "FindingGradient" 2 "ActiveBrakePedalPressed" 3 "ActiveBrakePedalReleased" 4 "FastRelease" 5 "SlowRelease" 6 "FaultyWithDriverIndication" 7 "Faulty" ;
VAL_ 125 BrkTot_Tq_Actl 8190 "Unknown" 8191 "Fault" ;
VAL_ 125 VehVertComp_A_Actl 1022 "NoDataExists" 1023 "Fault" ;
VAL_ 125 VehRolComp_W_Actl 4094 "NoDataExists" 4095 "Fault" ;
VAL_ 126 StePinRelInit_An_Sns 65534 "NoDataExists" 65535 "Faulty" ;
VAL_ 126 StePw_B_Rq 0 "No" 1 "Yes" ;
VAL_ 126 StePinCompAnEst_D_Qf 0 "Faulty" 1 "No_Data_Exists" 2 "Degraded" 3 "OK" ;
VAL_ 129 SteWhlSwtchDown_B_Stat 0 "Not_Pressed" 1 "Pressed" ;
VAL_ 129 SteWhlSwtchLeft_B_Stat 0 "Not_Pressed" 1 "Pressed" ;
VAL_ 129 SteWhlSwtchRght_B_Stat 0 "Not_Pressed" 1 "Pressed" ;
VAL_ 129 SteWhlSwtchUp_B_Stat 0 "Not_Pressed" 1 "Pressed" ;
VAL_ 129 SteWhlSwtchOk_B_Stat 0 "Not_Pressed" 1 "Pressed" ;
VAL_ 129 SteEffortInc_B_RqDrv 0 "Not_Pressed" 1 "Pressed" ;
VAL_ 129 SelDrvMdeInc_B_RqDrv 0 "Not_Pressed" 1 "Pressed" ;
VAL_ 129 SelDrvMdeDec_B_RqDrv 0 "Not_Pressed" 1 "Pressed" ;
VAL_ 129 SteWhlSwtchSet_B_Stat 0 "Not_Pressed" 1 "Pressed" ;
VAL_ 129 SteWhlSwtchPhon_B_Stat 0 "Not_Pressed" 1 "Pressed" ;
VAL_ 129 SteWhlSwtchNav_B_Stat 0 "Not_Pressed" 1 "Pressed" ;
VAL_ 129 SteWhlSwtchMed_B_Stat 0 "Not_Pressed" 1 "Pressed" ;
VAL_ 129 SteWhlSwtchIod_B_Stat 0 "Not_Pressed" 1 "Pressed" ;
VAL_ 129 SteWhlSwtchHud_B_Stat 0 "Not_Pressed" 1 "Pressed" ;
VAL_ 129 SteWhlSwtchBack_B_Stat 0 "Not_Pressed" 1 "Pressed" ;
VAL_ 129 SuspDampInc_B_RqDrv 0 "Not_Pressed" 1 "Pressed" ;
VAL_ 129 PoliceAux2Swtch_B_Stat 0 "Switch_Not_Active" 1 "Switch_Active" ;
VAL_ 129 PoliceAux1Swtch_B_Stat 0 "Switch_Not_Active" 1 "Switch_Active" ;
VAL_ 129 SteWhlSwtchInfo_B_Stat 0 "Not_Pressed" 1 "Pressed" ;
VAL_ 129 SteWhlSwtchHome_B_Stat 0 "Not_Pressed" 1 "Pressed" ;
VAL_ 129 SelDrvMdeSwtch_D_Stat4 0 "NotPressed" 1 "SwitchState1" 2 "SwitchState2" 3 "Faulty" ;
VAL_ 129 SteWhlSwtchMenu_B_Stat 0 "Not_Pressed" 1 "Pressed" ;
VAL_ 129 SteWhlSwtchView_B_Stat 0 "Not_Pressed" 1 "Pressed" ;
VAL_ 129 SelDrvMdeSwtch3_D_Stat4 0 "Null" 1 "NotPressed" 2 "Pressed" 3 "Faulty" ;
VAL_ 129 SelDrvMdeSwtch2_D_Stat4 0 "Null" 1 "NotPressed" 2 "Pressed" 3 "Faulty" ;
VAL_ 129 SelDrvMdeSwtch1_D_Stat4 0 "Null" 1 "NotPressed" 2 "Pressed" 3 "Faulty" ;
VAL_ 129 PoliceAux4Swtch_B_Stat 0 "Switch_Not_Active" 1 "Switch_Active" ;
VAL_ 129 PoliceAux3Swtch_B_Stat 0 "Switch_Not_Active" 1 "Switch_Active" ;
VAL_ 129 TiltableSteMsgTxt_D_Rq 0 "NoMessage" 1 "VehMtnNotAllwAirbagDactv" 2 "ShifToParkToEnblWhlTilting" 3 "ApplyPrkBrkToEnblWhlTilting" 4 "CntrSteWhlToEnblWhlTilting" 5 "Fault_VehicleSafeToDrive" 6 "Fault_WhlToBeForcedIntoPos" 7 "Fault_VehNotSafeToDrive" 8 "Fault_VehMotionInhibited" 9 "VehMotionNotAllowed" 10 "ShifToNtrlToEnblWhlTilting" 11 "NotUsed_1" 12 "NotUsed_2" 13 "NotUsed_3" 14 "NotUsed_4" 15 "NotUsed_5" ;
VAL_ 129 AirbagDrv_B_RqDactv 0 "NoRequest" 1 "Request" ;
VAL_ 129 SelDrvMdeSwtch4_D_Stat4 0 "Null" 1 "NotPressed" 2 "Pressed" 3 "Faulty" ;
VAL_ 129 EngExhMdeQuiet_B_RqDrv2 0 "Not_Pressed" 1 "Pressed" ;
VAL_ 129 StewSwtchScnd_D_Stat 0 "Not_Pressed" 1 "Pressed" ;
VAL_ 129 StewSwtchPrimPos_D_St 0 "Null" 1 "One" 2 "Two" 3 "Three" 4 "Four" 5 "Five" 6 "Six" 7 "Seven" 8 "Eight" 9 "Nine" 10 "NotUsed_1" 11 "NotUsed_2" 12 "NotUsed_3" 13 "NotUsed_4" 14 "NotUsed_5" 15 "Faulty" ;
VAL_ 129 StewSwtchPrim_D_Stat 0 "Not_Pressed" 1 "Pressed" ;
VAL_ 129 VdsButtnOn_B_Rq 0 "Not_Pressed" 1 "Pressed" ;
VAL_ 129 VdsButtnActv_B_Rq 0 "Not_Pressed" 1 "Pressed" ;
VAL_ 129 StewSwtchScndPos_D_St 0 "Null" 1 "One" 2 "Two" 3 "Three" 4 "Four" 5 "Five" 6 "Six" 7 "Seven" 8 "Eight" 9 "Nine" 10 "NotUsed_1" 11 "NotUsed_2" 12 "NotUsed_3" 13 "NotUsed_4" 14 "NotUsed_5" 15 "Faulty" ;
VAL_ 130 SteeringColumnTorque 254 "Unknown" 255 "Invalid" ;
VAL_ 130 EPAS_Failure 0 "EPAS_OK_NO_MESSAGE" 1 "POWER_STRG_ASSIST_FAULT" 2 "SERVICE_POWER_STEERING" 3 "SERVICE_POWER_STEERING_NOW" ;
VAL_ 130 DrvSteActv_B_Stat 0 "Inactive" 1 "Active" ;
VAL_ 130 SAPPAngleControlStat2 0 "NoRel_ExtSteeringAngleReqx" 1 "Rel_ExtSteeringAngleReqx" ;
VAL_ 130 SAPPAngleControlStat3 0 "ExternalSigContentOKforEAC" 1 "EARactiveNoReverseEngage" ;
VAL_ 130 SAPPAngleControlStat4 0 "ExternalSigContentOKforEAC" 1 "SpeedLimitExceededEAROn" ;
VAL_ 130 SAPPAngleControlStat5 0 "ExternalSigContentOKforEAC" 1 "StrgColTorqueExceed_EAROn" ;
VAL_ 130 SAPPAngleControlStat6 0 "RequestedAngleCanBeReached" 1 "RequestedAngleNotReached" ;
VAL_ 130 SteMdule_I_Est 4095 "Invalid" ;
VAL_ 130 SAPPAngleControlStat1 0 "Closed" 1 "Open" 2 "Active" 3 "Fault" ;
VAL_ 130 TrlrHitchLamp_D_Rqst 0 "Off" 1 "On" ;
VAL_ 130 VehVTrlrAid_B_Rq 0 "NoRequest" 1 "Request" ;
VAL_ 130 SteMdule_U_Meas 255 "Invalid" ;
VAL_ 130 DrvSte_Tq_Actl 254 "Unknown" 255 "Invalid" ;
VAL_ 130 ElPwAsstSte_B_Stat 0 "Inactive" 1 "Active" ;
VAL_ 130 SteEffort_D_Stat 0 "Normal" 1 "Sport" 2 "Comfort" 3 "SpecialMode_1" 4 "SpecialMode_2" 5 "NotUsed_1" 6 "NotUsed_2" 7 "NotUsed_3" ;
VAL_ 130 SteMdule_D_Stat 0 "EPAS_Initialization" 1 "Normal_Op_Limited_Assist" 2 "Normal_Op_Full_Assist" 3 "EPAS_Shutdown" 4 "System_Failure" 5 "EPAS_Failure2" 6 "EPAS_Failure3" 7 "NotUsed" ;
VAL_ 131 WiprFront_D_Stat 0 "OFF" 1 "AUTO_OFF" 2 "OFF_MOVING" 3 "MAN_INT_OFF" 4 "MAN_INT_ON" 5 "MAN_LOW" 6 "MAN_HIGH" 7 "MIST_FLICK" 8 "WASH" 9 "AUTO_LOW" 10 "AUTO_HIGH" 11 "COURTESYWIPE" 12 "AUTO_ADJUST" 13 "RESERVED" 14 "STALLED" 15 "NO_DATA_EXISTS" ;
VAL_ 131 TurnLghtSwtch_D_Stat 0 "Off" 1 "Left" 2 "Right" 3 "Unused_Treat_As_Off" ;
VAL_ 131 ElPwAsstSte_B_RqDactv 0 "NoRequest" 1 "Request" ;
VAL_ 131 CcAslButtnCnclPress 0 "Button_Not_Pressed" 1 "Button_Pressed" ;
VAL_ 131 AslButtnOnOffPress 0 "Button_Not_Pressed" 1 "Button_Pressed" ;
VAL_ 131 AslButtnOnOffCnclPress 0 "Button_Not_Pressed" 1 "Button_Pressed" ;
VAL_ 131 AccButtnGapIncPress 0 "Button_Not_Pressed" 1 "Button_Pressed" ;
VAL_ 131 AccButtnGapDecPress 0 "Button_Not_Pressed" 1 "Button_Pressed" ;
VAL_ 131 LghtAmb_D_Sns 0 "Dark" 1 "Light" 2 "Twilight" 3 "Tunnel_On" 4 "Tunnel_Off" 5 "Unused1" 6 "Unused2" 7 "No_Data_Exists" ;
VAL_ 131 CcAslButtnOnOffCncl 0 "Button_Not_Pressed" 1 "Button_Pressed" ;
VAL_ 131 CcAslButtnOffCnclPress 0 "Button_Not_Pressed" 1 "Button_Pressed" ;
VAL_ 131 CcAslButtnIndxIncPress 0 "Button_Not_Pressed" 1 "Button_Pressed" ;
VAL_ 131 CcAslButtnIndxDecPress 0 "Button_Not_Pressed" 1 "Button_Pressed" ;
VAL_ 131 CcAslButtnDeny_B_Actl 0 "No" 1 "Yes" ;
VAL_ 131 CcAslButtnCnclResPress 0 "Button_Not_Pressed" 1 "Button_Pressed" ;
VAL_ 131 LaSwtchPos_D_Stat 0 "Open" 1 "Pressed" 2 "Unused" 3 "Fault" ;
VAL_ 131 CcButtnOffPress 0 "Button_Not_Pressed" 1 "Button_Pressed" ;
VAL_ 131 CcAsllButtnResPress 0 "Button_Not_Pressed" 1 "Button_Pressed" ;
VAL_ 131 CcAslButtnSetPress 0 "Button_Not_Pressed" 1 "Button_Pressed" ;
VAL_ 131 CcAslButtnSetIncPress 0 "Button_Not_Pressed" 1 "Button_Pressed" ;
VAL_ 131 CcAslButtnSetDecPress 0 "Button_Not_Pressed" 1 "Button_Pressed" ;
VAL_ 131 CcAslButtnResIncPress 0 "Button_Not_Pressed" 1 "Button_Pressed" ;
VAL_ 131 CcAslButtnResDecPress 0 "Button_Not_Pressed" 1 "Button_Pressed" ;
VAL_ 131 CcAslButtnOnPress 0 "Button_Not_Pressed" 1 "Button_Pressed" ;
VAL_ 131 AccButtnGapTogglePress 0 "Not_Pressed" 1 "Pressed" ;
VAL_ 131 AhbStat_B_Dsply 0 "Off" 1 "On" ;
VAL_ 131 HeadLghtHiOn_B_StatAhb 0 "Off" 1 "On" ;
VAL_ 131 HeadLghtHiFlash_D_Actl 0 "Null" 1 "Flash_to_Pass" 2 "High" 3 "NotUsed" ;
VAL_ 131 CcButtnOnPress 0 "Button_Not_Pressed" 1 "Button_Pressed" ;
VAL_ 131 CcButtnOnOffPress 0 "Button_Not_Pressed" 1 "Button_Pressed" ;
VAL_ 131 CcButtnOnOffCnclPress 0 "Button_Not_Pressed" 1 "Button_Pressed" ;
VAL_ 131 TjaButtnOnOffPress 0 "Not_Pressed" 1 "Pressed" ;
VAL_ 131 HeadLghtHiCtrl_D_RqAhb 0 "Null" 1 "Man_LoBeam" 2 "Man_HiBeam" 3 "Flash" 4 "Auto_LoBeam" 5 "Auto_HiBeam" 6 "NotUsed1" 7 "NotUsed2" ;
VAL_ 131 WiprFrontSwtch_D_Stat 0 "Off" 1 "Position1" 2 "Position2" 3 "Position3" 4 "Position4" 5 "Position5" 6 "Position6" 7 "Low" 8 "High" 9 "PositionNotDetermined" 10 "NotUsed1" 11 "NotUsed2" 12 "NotUsed3" 13 "NotUsed4" 14 "NotUsed5" 15 "NotUsed6" ;
VAL_ 131 RainIntensity_D_Stat 0 "No_Rain" 1 "Rain_Level1" 2 "Rain_Level2" 3 "Rain_Level3" 4 "Rain_Level4" 5 "Rain_Level5" 6 "Rain_Level6" 7 "No_Data_Exist" ;
VAL_ 131 HeadLghtHiFlash_D_Stat 0 "Null" 1 "Flash_To_Pass" 2 "High" 3 "Not Used" ;
VAL_ 131 TurnLghtSwtch_D_Arb 0 "Idle" 1 "LeftPreLc" 2 "RightPreLc" 3 "LeftLaneChange" 4 "RightLaneChange" 5 "LeftLcCancelled" 6 "RightLcCancelled" 7 "LeftTurn" 8 "RightTurn" 9 "LeftTurnCancelled" 10 "RightTurnCancelled" 11 "NotUsed_1" 12 "NotUsed_2" 13 "NotUsed_3" 14 "NotUsed_4" 15 "Faulty" ;
VAL_ 133 WrlssAcsyChrg_Pc_Actl2 126 "Nodataexists" 127 "Faulty" ;
VAL_ 133 WrlssAcsyChrgr_D_Stat2 0 "Null" 1 "ChargingNotInProgress" 2 "ChargingInProgress" 3 "ChargingComplete" 4 "MetalObjectDetected" 5 "Overheat" 6 "Misalignment" 7 "NotUsed_1" ;
VAL_ 134 DispGlblClkAdj_B_Rq 0 "NoRequest" 1 "Request" ;
VAL_ 135 McGlblClkAdj_B_Rq 0 "NoRequest" 1 "Request" ;
VAL_ 139 CcAslButtnIndxDecPres2 0 "Button_Not_Pressed" 1 "Button_Pressed" ;
VAL_ 139 CcAslButtnDeny_B_Actl2 0 "No" 1 "Yes" ;
VAL_ 139 CcAslButtnCnclResPres2 0 "Button_Not_Pressed" 1 "Button_Pressed" ;
VAL_ 139 CcAslButtnCnclPress2 0 "Button_Not_Pressed" 1 "Button_Pressed" ;
VAL_ 139 AslButtnOnOffPress2 0 "Button_Not_Pressed" 1 "Button_Pressed" ;
VAL_ 139 AslButtnOnOffCnclPres2 0 "Button_Not_Pressed" 1 "Button_Pressed" ;
VAL_ 139 AccButtnGapIncPress2 0 "Button_Not_Pressed" 1 "Button_Pressed" ;
VAL_ 139 AccButtnGapDecPress2 0 "Button_Not_Pressed" 1 "Button_Pressed" ;
VAL_ 139 CcAslButtnSetIncPress2 0 "Button_Not_Pressed" 1 "Button_Pressed" ;
VAL_ 139 CcAslButtnSetDecPress2 0 "Button_Not_Pressed" 1 "Button_Pressed" ;
VAL_ 139 CcAslButtnResIncPress2 0 "Button_Not_Pressed" 1 "Button_Pressed" ;
VAL_ 139 CcAslButtnResDecPress2 0 "Button_Not_Pressed" 1 "Button_Pressed" ;
VAL_ 139 CcAslButtnOnPress2 0 "Button_Not_Pressed" 1 "Button_Pressed" ;
VAL_ 139 CcAslButtnOnOffCncl2 0 "Button_Not_Pressed" 1 "Button_Pressed" ;
VAL_ 139 CcAslButtnOffCnclPres2 0 "Button_Not_Pressed" 1 "Button_Pressed" ;
VAL_ 139 CcAslButtnIndxIncPres2 0 "Button_Not_Pressed" 1 "Button_Pressed" ;
VAL_ 139 ActvFrontSteLck_D_Stat 0 "Test_incomplete" 1 "Test_cannot_run" 2 "Test_failed" 3 "Test_passed" ;
VAL_ 139 CcButtnOnPress2 0 "Button_Not_Pressed" 1 "Button_Pressed" ;
VAL_ 139 CcButtnOnOffPress2 0 "Button_Not_Pressed" 1 "Button_Pressed" ;
VAL_ 139 CcButtnOnOffCnclPress2 0 "Button_Not_Pressed" 1 "Button_Pressed" ;
VAL_ 139 CcButtnOffPress2 0 "Button_Not_Pressed" 1 "Button_Pressed" ;
VAL_ 139 CcAsllButtnResPress2 0 "Button_Not_Pressed" 1 "Button_Pressed" ;
VAL_ 139 CcAslButtnSetPress2 0 "Button_Not_Pressed" 1 "Button_Pressed" ;
VAL_ 139 AfsPw_B_Rq 0 "No" 1 "Yes" ;
VAL_ 139 AccButtnGpTogglePress2 0 "Not_Pressed" 1 "Pressed" ;
VAL_ 139 TjaButtnOnOffPress2 0 "Not_Pressed" 1 "Pressed" ;
VAL_ 139 SelDrvMdeAdptSte_D_Stat 0 "NotAvailable" 1 "Available" 2 "TemporarilyNotAvailable" 3 "Faulty" ;
VAL_ 139 ActvFrontSteMsgTxt_D_Rq 0 "NoMessage" 1 "Message1" 2 "Message2" 3 "Message3" 4 "Message4" 5 "Message5" 6 "Message6" 7 "Message7" ;
VAL_ 140 StewPosAdjTlt_D_Rq 0 "Null" 1 "Up" 2 "Down" 3 "NotUsed" ;
VAL_ 140 StewPosAdjTel_D_Rq 0 "Null" 1 "Out" 2 "In" 3 "NotUsed_1" ;
VAL_ 140 TjaButtnOnOffPress4 0 "Not_Pressed" 1 "Pressed" ;
VAL_ 140 AccButtnGapTogglePress3 0 "Not_Pressed" 1 "Pressed" ;
VAL_ 140 AccButtnGapIncPress4 0 "Not_Pressed" 1 "Pressed" ;
VAL_ 140 AccButtnGapDecPress4 0 "Not_Pressed" 1 "Pressed" ;
VAL_ 140 CcAslButtnCnclPress3 0 "Not_pressed" 1 "Pressed" ;
VAL_ 140 AslButtnOnOffPress3 0 "Not_pressed" 1 "Pressed" ;
VAL_ 140 AslButtnOnOffCnclPress2 0 "Not_pressed" 1 "Pressed" ;
VAL_ 140 ExtMirrorAdj_D_Rq 0 "Null" 1 "Down" 2 "Up" 3 "Left" 4 "Right" 5 "NotUsed_1" 6 "NotUsed_2" 7 "NotUsed_3" ;
VAL_ 140 MirrorSelFold_D_Rq 0 "Null" 1 "Left" 2 "Right" 3 "Fold_Unfold" ;
VAL_ 140 CcAslButtnOnOffCncl3 0 "Not_pressed" 1 "Pressed" ;
VAL_ 140 CcAslButtnOffCnclPress2 0 "Button_Not_Pressed" 1 "Button_Pressed" ;
VAL_ 140 CcAslButtnIndxIncPress2 0 "Button_Not_Pressed" 1 "Button_Pressed" ;
VAL_ 140 CcAslButtnIndxDecPress2 0 "Button_Not_Pressed" 1 "Button_Pressed" ;
VAL_ 140 CcAslButtnDeny_B_Actl3 0 "Not_pressed" 1 "Pressed" ;
VAL_ 140 CcAslButtnCnclResPress2 0 "Button_Not_Pressed" 1 "Button_Pressed" ;
VAL_ 140 SteWhlSwtchMde_D_Stat 0 "Domain" 1 "Dialog" 2 "NotUsed_1" 3 "NotUsed_2" ;
VAL_ 140 CcButtnOffPress3 0 "Not_pressed" 1 "Pressed" ;
VAL_ 140 CcAsllButtnResPress3 0 "Not_pressed" 1 "Pressed" ;
VAL_ 140 CcAslButtnSetPress3 0 "Not_pressed" 1 "Pressed" ;
VAL_ 140 CcAslButtnSetIncPress3 0 "Not_pressed" 1 "Pressed" ;
VAL_ 140 CcAslButtnSetDecPress3 0 "Not_pressed" 1 "Pressed" ;
VAL_ 140 CcAslButtnResIncPress3 0 "Not_pressed" 1 "Pressed" ;
VAL_ 140 CcAslButtnResDecPress3 0 "Not_pressed" 1 "Pressed" ;
VAL_ 140 CcAslButtnOnPress3 0 "Not_pressed" 1 "Pressed" ;
VAL_ 140 PdlAdj_D_Rq 0 "Null" 1 "Forward" 2 "Backward" 3 "NotUsed_1" ;
VAL_ 140 StewSwtchIlumnat_B_Rq 0 "Off" 1 "On" ;
VAL_ 140 DcacPwResetBttn_D_Stat 0 "Not_Pressed" 1 "Pressed" 2 "Stuck" 3 "NotUsed" ;
VAL_ 140 CcButtnOnPress3 0 "Not_pressed" 1 "Pressed" ;
VAL_ 140 CcButtnOnOffPress3 0 "Not_pressed" 1 "Pressed" ;
VAL_ 140 CcButtnOnOffCnclPress3 0 "Not_pressed" 1 "Pressed" ;
VAL_ 140 BrkMaintMde_D_Rq 0 "NoRequest" 1 "RequestEnterMaintMode" 2 "RequestExitMaintMode" 3 "NotUsed_1" ;
VAL_ 141 WrlssAcsyChrg_Pc_Actl3 126 "Nodataexists" 127 "Faulty" ;
VAL_ 141 WrlssAcsyChrgr_D_Stat3 0 "Null" 1 "ChargingNotInProgress" 2 "ChargingInProgress" 3 "ChargingComplete" 4 "MetalObjectDetected" 5 "Overheat" 6 "Misalignment" 7 "NotUsed_1" ;
VAL_ 142 MobcGlblSrcPrim_D_Stat 0 "None" 1 "Primary" 2 "Secondary" 3 "Both" ;
VAL_ 142 MobcCpbltyPrim_B_Stat 0 "Degraded" 1 "Ok" ;
VAL_ 142 MobcAlignMsgPrim_D_Rq 0 "NoMessage" 1 "Steer_Left" 2 "Steer_Right" 3 "Alignment_Incomplete" ;
VAL_ 142 RoadWhlAlignPrim_D_Stat 0 "NotAligned" 1 "FineAligned" 2 "CoarseAligned" 3 "NotUsed_1" ;
VAL_ 143 MobcGlblSrcScnd_D_Stat 0 "None" 1 "Primary" 2 "Secondary" 3 "Both" ;
VAL_ 143 MobcCpbltyScnd_B_Stat 0 "Degraded" 1 "Ok" ;
VAL_ 143 MobcAlignMsgScnd_D_Rq 0 "NoMessage" 1 "Steer_Left" 2 "Steer_Right" 3 "Alignment_Incomplete" ;
VAL_ 143 RoadWhlAlignScnd_D_Stat 0 "NotAligned" 1 "FineAligned" 2 "CoarseAligned" 3 "NotUsed_1" ;
VAL_ 144 SetTimeFormat 0 "Inactive" 1 "12h_mode" 2 "24h_mode" 3 "NotUsed" ;
VAL_ 144 DateAdjustRequest 0 "NoDateAdjustRequest" 1 "DateAdjustRequest" ;
VAL_ 144 TimeAdjustRequest 0 "NoTimeAdjustRequest" 1 "TimeAdjustRequest" ;
VAL_ 146 VehLat2_A_Actl 8190 "NoDataExists" 8191 "Faulty" ;
VAL_ 146 VehLatAActl_D_Qf 0 "Faulty" 1 "No_Data_Exists" 2 "Not_Within_Specifications" 3 "OK" ;
VAL_ 146 VehLong2_A_Actl 8190 "NoDataExists" 8191 "Faulty" ;
VAL_ 146 VehLongAActl_D_Qf 0 "Faulty" 1 "No_Data_Exists" 2 "Not_Within_Specifications" 3 "OK" ;
VAL_ 146 VehVert2_A_Actl 8190 "NoDataExists" 8191 "Faulty" ;
VAL_ 146 VehVertAActl_D_Qf 0 "Faulty" 1 "No_Data_Exists" 2 "Not_Within_Specifications" 3 "OK" ;
VAL_ 148 VehRol_W_Actl 65534 "NoDataExists" 65535 "Faulty" ;
VAL_ 148 VehYaw_W_Actl 65534 "NoDataExists" 65535 "Faulty" ;
VAL_ 148 VehYawWActl_D_Qf 0 "Faulty" 1 "No_Data_Exists" 2 "Not_Within_Specifications" 3 "OK" ;
VAL_ 148 VehRolWActl_D_Qf 0 "Faulty" 1 "No_Data_Exists" 2 "Not_Within_Specifications" 3 "OK" ;
VAL_ 256 FrwlAnmtnDsply_D_Rq 0 "Default_Value" 1 "TriggerToStrtFrwlAnimation" 2 "NotUsed_1" 3 "NotUsed_2" ;
VAL_ 257 MFD_GetTagInfo 0 "Inactive" 1 "TagInformation" ;
VAL_ 257 MFD_SetHDModeRq 0 "Inactive" 1 "Off" 2 "On" ;
VAL_ 257 MFD_SetTagMode 0 "Inactive" 1 "Off" 2 "On" ;
VAL_ 257 MFD_SetRBDSMode 0 "Inactive" 1 "Off" 2 "On" ;
VAL_ 258 LghtAmbDynmc_D_Rq 0 "Default_Value" 1 "StartAmbLghtDynmclllumntn" 2 "NotUsed_1" 3 "NotUsed_2" ;
VAL_ 259 SDARS_ChipControl_Rq 0 "Inactive" 1 "PowerUp" 2 "PowerDown" 3 "Reset" 4 "NotUsed_1" 5 "NotUsed_2" 6 "NotUsed_3" 7 "NotUsed_4" ;
VAL_ 259 SDARS_AlertStatus_Rq 0 "Inactive" 1 "Enable" 2 "Disable" ;
VAL_ 260 SDARS_SRReplay_Rq 0 "Inactive" 1 "Enable" 2 "Disable" ;
VAL_ 260 MFD_SDARS_SetOpMode_Rq 0 "Invalid" 1 "Stop" 2 "Play" 3 "Pause" 4 "FastForwardSpeed1" 5 "FastForwardSpeed2" 6 "FastRewindSpeed1" 7 "FastRewindSpeed2" ;
VAL_ 260 SDARS_FactoryReset_Rq 0 "Invalid" 1 "ResetFactoryDefaults" ;
VAL_ 260 SDARS_GetESN_Rq 0 "Invalid" 1 "RequestESN" ;
SIG_GROUP_ 117 SG_BrkLamp_E2E_P01A 1 : BrkLamp_B_Rq_EF BrkLamp_No_Cnt BrkLamp_No_Cs BrkLamp_UNUSED_1bit_1 BrkLamp_UNUSED_8bit_1 BrkLamp_UNUSED_8bit_2 BrkLamp_UNUSED_8bit_3 BrkLamp_UNUSED_8bit_4 BrkLamp_UNUSED_8bit_5 DrvAntiLckLamp_D_Rq_EF DrvSlipCtlLamp_D_Rq_EF DrvSlipCtlOffLamp_D_Rq_EF PrkBrkRedLamp_D_Rq_EF PrkBrkYwLamp_D_Rq_EF;
